VERSION ""

NS_ :

BS_:

BU_: Turbocharger OnBoardDataLogger OffBoardDiagnosticTool2 OffBoardDiagnosticTool1 FileServer ParkingBrakeController SeatControl2 FanDriveController SteeringColumnUnit CommunicationUnitRadio CommunicationUnitSatellite CommunicationUnitCellular PropulsionBatteryCharger ChassisController2 ChassisController1 EngineValveControl AuxiliaryHeater2 AuxiliaryHeater1 ClutchUnit RampControl InformationSystem1 SuspensionSystemController2 OilSensor VehicleDynamicStability ExhaustEmissionController TransmissionDisplay2 TransmissionDisplay1 ClimateControl2 WaterPumpController RearAxleSteeringController LightingOperatorControl SeatController1 IgnitionController2 IgnitionController1 TirePressureController CabController2 CabController1 PneumaticSystemController SuspensionSystemController1 HydraulicPumpController EnduranceBrakingSystem RetarderExhaustEngine2 OnBoardDiagnosticUnit HeadwayController RetarderExhaustEngine1 CabDisplay1 ManagementComputer VirtualTerminal OffVehicleGateway PowerTakeOffFront HitchControl AuxiliaryValveControl BodyController TractorTrailerBridge1 StarterSystem ElectricalSystem VehicleSecurity VehicleNavigation AerodynamicControl ElectricalChargingSystem ClimateControl1 TripRecorder InstrumentCluster SuspensionDriveAxle2 SuspensionDriveAxle1 SuspensionSteerAxle SteeringController FuelSystem CruiseControl RetarderDriveline RetarderEngine BrakesDriveAxle2 BrakesDriveAxle1 BrakesSystemController BrakesSteerAxle AxleDrive2 AxleDrive1 AxleSteering PowerTakeOff ShiftConsoleSecondary ShiftConsolePrimary Transmission2 Transmission1 Engine2 Engine1

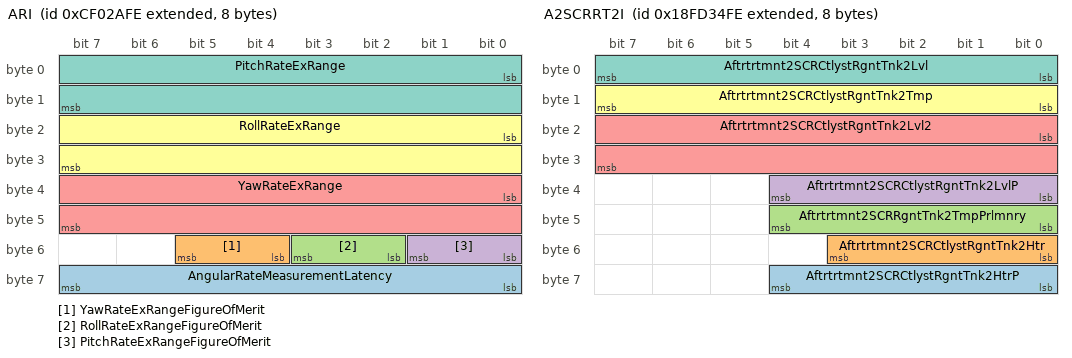
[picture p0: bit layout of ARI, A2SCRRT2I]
BO_ 2364549886 ARI: 8 Vector__XXX
 SG_ AngularRateMeasurementLatency : 56|8@1+ (0.5,0) [0|125] "ms" Vector__XXX
 SG_ YawRateExRangeFigureOfMerit : 52|2@1+ (1,0) [0|3] "" Vector__XXX
 SG_ RollRateExRangeFigureOfMerit : 50|2@1+ (1,0) [0|3] "" Vector__XXX
 SG_ PitchRateExRangeFigureOfMerit : 48|2@1+ (1,0) [0|3] "" Vector__XXX
 SG_ YawRateExRange : 32|16@1+ (0.0078125,-250) [-250|250.992] "deg/sec" Vector__XXX
 SG_ RollRateExRange : 16|16@1+ (0.0078125,-250) [-250|250.992] "deg/sec" Vector__XXX
 SG_ PitchRateExRange : 0|16@1+ (0.0078125,-250) [-250|250.992] "deg/sec" Vector__XXX

BO_ 2566712318 AFT2NAI: 8 Vector__XXX
 SG_ Aftrtrtmnt2NOxAdsrbrDSOxRgnrtnSt : 2|2@1+ (1,0) [0|3] "" Vector__XXX
 SG_ Aftrtrtmnt2NOxAdsrbrDNOxRgnrtnSt : 0|2@1+ (1,0) [0|3] "" Vector__XXX

BO_ 2566712574 AFT1NAI: 8 Vector__XXX
 SG_ Aftrtrtmnt1NOxAdsrbrDSOxRgnrtnSt : 2|2@1+ (1,0) [0|3] "" Vector__XXX
 SG_ Aftrtrtmnt1NOxAdsrbrDNOxRgnrtnSt : 0|2@1+ (1,0) [0|3] "" Vector__XXX

BO_ 2164078590 A2SCRSI: 8 Vector__XXX
 SG_ Aftrtrtmnt2SCRCtlystCnvrsnEffcnc : 32|8@1+ (0.4,0) [0|100] "%" Vector__XXX
 SG_ Aftrtrtmnt2SCRCmddCtlystRgntCnsm : 16|16@1+ (0.05,0) [0|3212.75] "L/h" Vector__XXX
 SG_ Aftrtrtmnt2SCRAvrgCtlystRgntCnsm : 0|16@1+ (0.05,0) [0|3212.75] "L/h" Vector__XXX

BO_ 2566731006 A2SCRRT2I: 8 Vector__XXX
 SG_ Aftrtrtmnt2SCRCtlystRgntTnk2HtrP : 56|5@1+ (1,0) [0|31] "" Vector__XXX
 SG_ Aftrtrtmnt2SCRCtlystRgntTnk2Htr : 48|4@1+ (1,0) [0|15] "" Vector__XXX
 SG_ Aftrtrtmnt2SCRRgntTnk2TmpPrlmnry : 40|5@1+ (1,0) [0|31] "" Vector__XXX
 SG_ Aftrtrtmnt2SCRCtlystRgntTnk2LvlP : 32|5@1+ (1,0) [0|31] "" Vector__XXX
 SG_ Aftrtrtmnt2SCRCtlystRgntTnk2Lvl2 : 16|16@1+ (0.1,0) [0|6425.5] "mm" Vector__XXX
 SG_ Aftrtrtmnt2SCRCtlystRgntTnk2Tmp : 8|8@1+ (1,-40) [-40|210] "degC" Vector__XXX
 SG_ Aftrtrtmnt2SCRCtlystRgntTnk2Lvl : 0|8@1+ (0.4,0) [0|100] "%" Vector__XXX

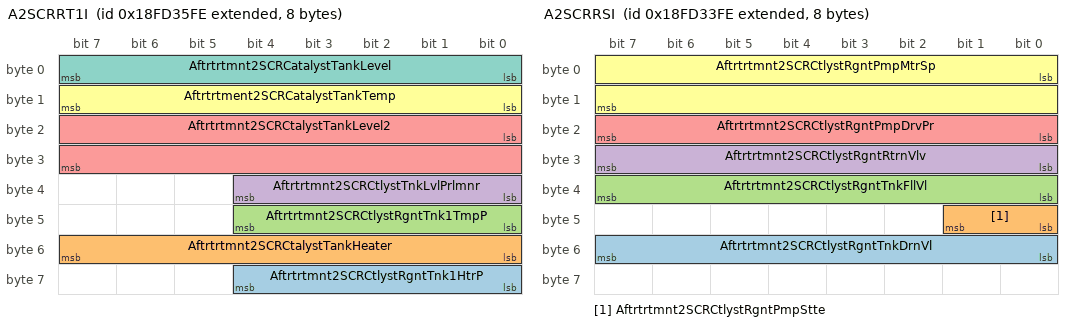
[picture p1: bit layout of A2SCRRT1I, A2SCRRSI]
BO_ 2566731262 A2SCRRT1I: 8 Vector__XXX
 SG_ Aftrtrtmnt2SCRCtlystRgntTnk1HtrP : 56|5@1+ (1,0) [0|31] "" Vector__XXX
 SG_ Aftrtrtmnt2SCRCtalystTankHeater : 48|8@1+ (0.4,0) [0|100] "%" Vector__XXX
 SG_ Aftrtrtmnt2SCRCtlystRgntTnk1TmpP : 40|5@1+ (1,0) [0|31] "" Vector__XXX
 SG_ Aftrtrtmnt2SCRCtlystTnkLvlPrlmnr : 32|5@1+ (1,0) [0|31] "" Vector__XXX
 SG_ Aftrtrtmnt2SCRCtalystTankLevel2 : 16|16@1+ (0.1,0) [0|6425.5] "mm" Vector__XXX
 SG_ Aftrtrtment2SCRCatalystTankTemp : 8|8@1+ (1,-40) [-40|210] "degC" Vector__XXX
 SG_ Aftrtrtmnt2SCRCatalystTankLevel : 0|8@1+ (0.4,0) [0|100] "%" Vector__XXX

BO_ 2566730750 A2SCRRSI: 8 Vector__XXX
 SG_ Aftrtrtmnt2SCRCtlystRgntTnkDrnVl : 48|8@1+ (0.4,0) [0|100] "%" Vector__XXX
 SG_ Aftrtrtmnt2SCRCtlystRgntPmpStte : 40|2@1+ (1,0) [0|3] "" Vector__XXX
 SG_ Aftrtrtmnt2SCRCtlystRgntTnkFllVl : 32|8@1+ (0.4,0) [0|100] "%" Vector__XXX
 SG_ Aftrtrtmnt2SCRCtlystRgntRtrnVlv : 24|8@1+ (0.4,0) [0|100] "%" Vector__XXX
 SG_ Aftrtrtmnt2SCRCtlystRgntPmpDrvPr : 16|8@1+ (0.4,0) [0|100] "%" Vector__XXX
 SG_ Aftrtrtmnt2SCRCtlystRgntPmpMtrSp : 0|16@1+ (0.5,0) [0|32127.5] "rpm" Vector__XXX

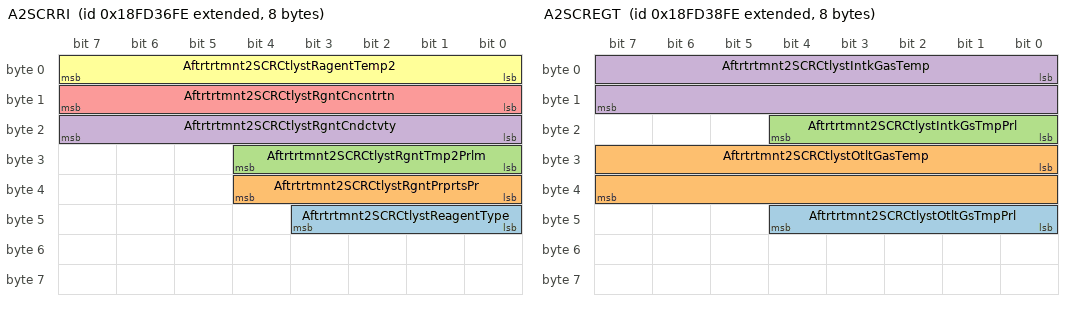
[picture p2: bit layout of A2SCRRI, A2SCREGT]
BO_ 2566731518 A2SCRRI: 8 Vector__XXX
 SG_ Aftrtrtmnt2SCRCtlystReagentType : 40|4@1+ (1,0) [0|15] "" Vector__XXX
 SG_ Aftrtrtmnt2SCRCtlystRgntPrprtsPr : 32|5@1+ (1,0) [0|31] "" Vector__XXX
 SG_ Aftrtrtmnt2SCRCtlystRgntTmp2Prlm : 24|5@1+ (1,0) [0|31] "" Vector__XXX
 SG_ Aftrtrtmnt2SCRCtlystRgntCndctvty : 16|8@1+ (5,0) [0|1250] "microSiemens/mm" Vector__XXX
 SG_ Aftrtrtmnt2SCRCtlystRgntCncntrtn : 8|8@1+ (0.25,0) [0|62.5] "%" Vector__XXX
 SG_ Aftrtrtmnt2SCRCtlystRagentTemp2 : 0|8@1+ (1,-40) [-40|210] "degC" Vector__XXX

BO_ 2566732030 A2SCREGT: 8 Vector__XXX
 SG_ Aftrtrtmnt2SCRCtlystOtltGsTmpPrl : 40|5@1+ (1,0) [0|31] "" Vector__XXX
 SG_ Aftrtrtmnt2SCRCtlystOtltGasTemp : 24|16@1+ (0.03125,-273) [-273|1734.96875] "degC" Vector__XXX
 SG_ Aftrtrtmnt2SCRCtlystIntkGsTmpPrl : 16|5@1+ (1,0) [0|31] "" Vector__XXX
 SG_ Aftrtrtmnt2SCRCtlystIntkGasTemp : 0|16@1+ (0.03125,-273) [-273|1734.96875] "degC" Vector__XXX

BO_ 2566732286 A2SCREGP: 8 Vector__XXX
 SG_ Aftrtrtmnt2SCRCtlystExhstGsDffPr : 16|5@1+ (1,0) [0|31] "" Vector__XXX
 SG_ Aftrtrtmnt2SCRCtlystExhstGs_0000 : 0|16@1+ (0.1,0) [0|6425.5] "kPa" Vector__XXX

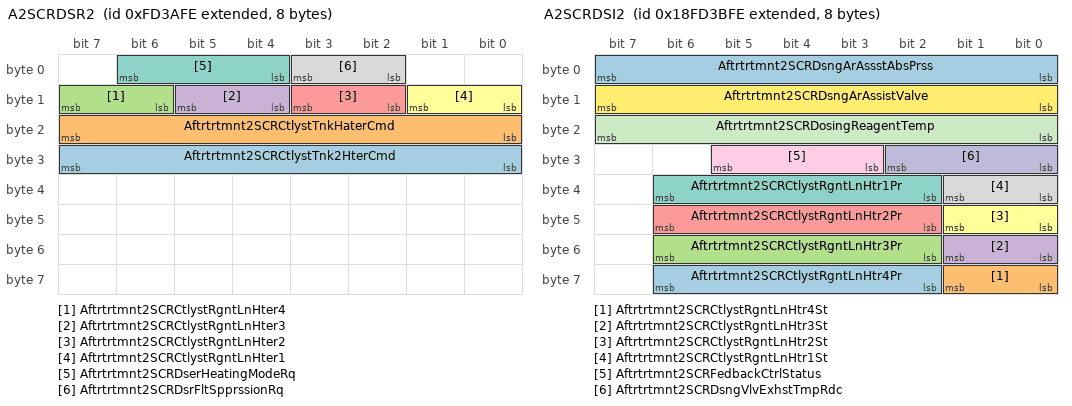
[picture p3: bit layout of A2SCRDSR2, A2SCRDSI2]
BO_ 2164079358 A2SCRDSR2: 8 Vector__XXX
 SG_ Aftrtrtmnt2SCRCtlystTnk2HterCmd : 24|8@1+ (0.4,0) [0|100] "%" Vector__XXX
 SG_ Aftrtrtmnt2SCRCtlystTnkHaterCmd : 16|8@1+ (0.4,0) [0|100] "%" Vector__XXX
 SG_ Aftrtrtmnt2SCRCtlystRgntLnHter4 : 14|2@1+ (1,0) [0|3] "" Vector__XXX
 SG_ Aftrtrtmnt2SCRCtlystRgntLnHter3 : 12|2@1+ (1,0) [0|3] "" Vector__XXX
 SG_ Aftrtrtmnt2SCRCtlystRgntLnHter2 : 10|2@1+ (1,0) [0|3] "" Vector__XXX
 SG_ Aftrtrtmnt2SCRCtlystRgntLnHter1 : 8|2@1+ (1,0) [0|3] "" Vector__XXX
 SG_ Aftrtrtmnt2SCRDserHeatingModeRq : 4|3@1+ (1,0) [0|7] "" Vector__XXX
 SG_ Aftrtrtmnt2SCRDsrFltSpprssionRq : 2|2@1+ (1,0) [0|3] "" Vector__XXX

BO_ 2364549118 A2SCRDSR1: 8 Vector__XXX
 SG_ Aftrtrtmnt2SCRRqdRgntQnttyFrIntg : 24|16@1+ (0.1,0) [0|6425.5] "g" Vector__XXX
 SG_ Aftrtratment2SCRSystemRqedState : 16|4@1+ (1,0) [0|15] "" Vector__XXX
 SG_ Aftrtrtmnt2SCRRqdDsngRgntQntity : 0|16@1+ (0.3,0) [0|19276.5] "g/h" Vector__XXX

BO_ 2566732798 A2SCRDSI2: 8 Vector__XXX
 SG_ Aftrtrtmnt2SCRCtlystRgntLnHtr4Pr : 58|5@1+ (1,0) [0|31] "" Vector__XXX
 SG_ Aftrtrtmnt2SCRCtlystRgntLnHtr4St : 56|2@1+ (1,0) [0|3] "" Vector__XXX
 SG_ Aftrtrtmnt2SCRCtlystRgntLnHtr3Pr : 50|5@1+ (1,0) [0|31] "" Vector__XXX
 SG_ Aftrtrtmnt2SCRCtlystRgntLnHtr3St : 48|2@1+ (1,0) [0|3] "" Vector__XXX
 SG_ Aftrtrtmnt2SCRCtlystRgntLnHtr2Pr : 42|5@1+ (1,0) [0|31] "" Vector__XXX
 SG_ Aftrtrtmnt2SCRCtlystRgntLnHtr2St : 40|2@1+ (1,0) [0|3] "" Vector__XXX
 SG_ Aftrtrtmnt2SCRCtlystRgntLnHtr1Pr : 34|5@1+ (1,0) [0|31] "" Vector__XXX
 SG_ Aftrtrtmnt2SCRCtlystRgntLnHtr1St : 32|2@1+ (1,0) [0|3] "" Vector__XXX
 SG_ Aftrtrtmnt2SCRFedbackCtrlStatus : 27|3@1+ (1,0) [0|7] "" Vector__XXX
 SG_ Aftrtrtmnt2SCRDsngVlvExhstTmpRdc : 24|3@1+ (1,0) [0|7] "" Vector__XXX
 SG_ Aftrtrtmnt2SCRDosingReagentTemp : 16|8@1+ (1,-40) [-40|210] "degC" Vector__XXX
 SG_ Aftrtrtmnt2SCRDsngArAssistValve : 8|8@1+ (0.4,0) [0|100] "%" Vector__XXX
 SG_ Aftrtrtmnt2SCRDsngArAssstAbsPrss : 0|8@1+ (8,0) [0|2000] "kPa" Vector__XXX

BO_ 2364548862 A2SCRDSI1: 8 Vector__XXX
 SG_ Aftrtrtmnt2SCRDsngRgentAbsPress : 40|8@1+ (8,0) [0|2000] "kPa" Vector__XXX
 SG_ Aftrtrtmnt2SCRActlRgntQnttyOfInt : 24|16@1+ (0.1,0) [0|6425.5] "g" Vector__XXX
 SG_ Aftertreatment2SCRSystemState : 16|4@1+ (1,0) [0|15] "" Vector__XXX
 SG_ Aftrtrtmnt2SCRActlDsngRgntQntty : 0|16@1+ (0.3,0) [0|19276.5] "g/h" Vector__XXX

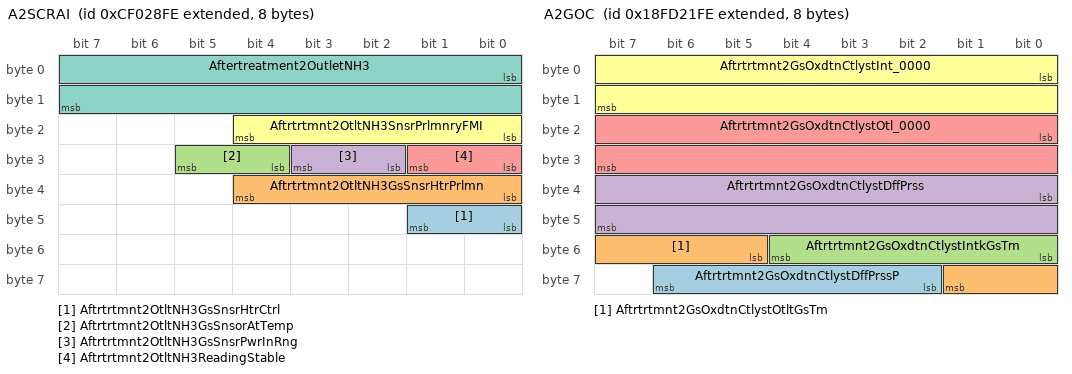
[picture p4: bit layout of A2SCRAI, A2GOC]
BO_ 2364549374 A2SCRAI: 8 Vector__XXX
 SG_ Aftrtrtmnt2OtltNH3GsSnsrHtrCtrl : 40|2@1+ (1,0) [0|3] "" Vector__XXX
 SG_ Aftrtrtmnt2OtltNH3GsSnsrHtrPrlmn : 32|5@1+ (1,0) [0|31] "" Vector__XXX
 SG_ Aftrtrtmnt2OtltNH3GsSnsorAtTemp : 28|2@1+ (1,0) [0|3] "" Vector__XXX
 SG_ Aftrtrtmnt2OtltNH3GsSnsrPwrInRng : 26|2@1+ (1,0) [0|3] "" Vector__XXX
 SG_ Aftrtrtmnt2OtltNH3ReadingStable : 24|2@1+ (1,0) [0|3] "" Vector__XXX
 SG_ Aftrtrtmnt2OtltNH3SnsrPrlmnryFMI : 16|5@1+ (1,0) [0|31] "" Vector__XXX
 SG_ Aftertreatment2OutletNH3 : 0|16@1+ (0.3,0) [0|19276.5] "g/h" Vector__XXX

BO_ 2566726142 A2GOC: 8 Vector__XXX
 SG_ Aftrtrtmnt2GsOxdtnCtlystDffPrssP : 58|5@1+ (1,0) [0|31] "" Vector__XXX
 SG_ Aftrtrtmnt2GsOxdtnCtlystOtltGsTm : 53|5@1+ (1,0) [0|31] "" Vector__XXX
 SG_ Aftrtrtmnt2GsOxdtnCtlystIntkGsTm : 48|5@1+ (1,0) [0|31] "" Vector__XXX
 SG_ Aftrtrtmnt2GsOxdtnCtlystDffPrss : 32|16@1+ (0.1,0) [0|6425.5] "kPa" Vector__XXX
 SG_ Aftrtrtmnt2GsOxdtnCtlystOtl_0000 : 16|16@1+ (0.03125,-273) [-273|1734.96875] "degC" Vector__XXX
 SG_ Aftrtrtmnt2GsOxdtnCtlystInt_0000 : 0|16@1+ (0.03125,-273) [-273|1734.96875] "degC" Vector__XXX

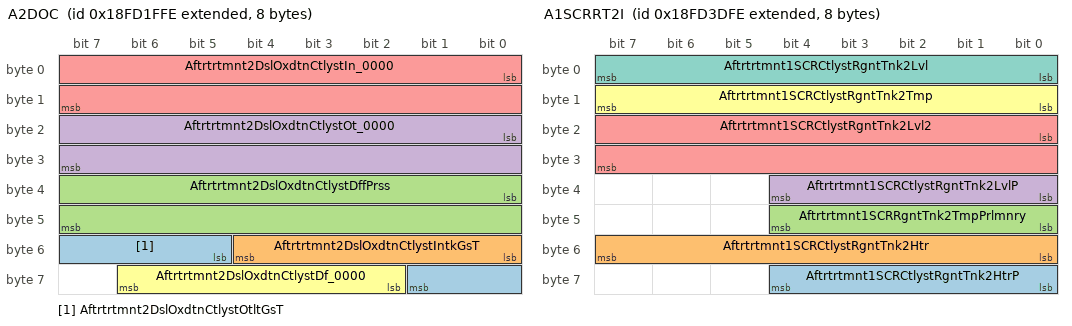
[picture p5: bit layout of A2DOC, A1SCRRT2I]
BO_ 2566725630 A2DOC: 8 Vector__XXX
 SG_ Aftrtrtmnt2DslOxdtnCtlystOtltGsT : 53|5@1+ (1,0) [0|31] "" Vector__XXX
 SG_ Aftrtrtmnt2DslOxdtnCtlystIntkGsT : 48|5@1+ (1,0) [0|31] "" Vector__XXX
 SG_ Aftrtrtmnt2DslOxdtnCtlystDffPrss : 32|16@1+ (0.5,0) [0|32127.5] "kPa" Vector__XXX
 SG_ Aftrtrtmnt2DslOxdtnCtlystOt_0000 : 16|16@1+ (0.03125,-273) [-273|1734.96875] "degC" Vector__XXX
 SG_ Aftrtrtmnt2DslOxdtnCtlystIn_0000 : 0|16@1+ (0.03125,-273) [-273|1734.96875] "degC" Vector__XXX
 SG_ Aftrtrtmnt2DslOxdtnCtlystDf_0000 : 58|5@1+ (1,0) [0|31] "" Vector__XXX

BO_ 2566733310 A1SCRRT2I: 8 Vector__XXX
 SG_ Aftrtrtmnt1SCRCtlystRgntTnk2HtrP : 56|5@1+ (1,0) [0|31] "" Vector__XXX
 SG_ Aftrtrtmnt1SCRCtlystRgntTnk2Htr : 48|8@1+ (0.4,0) [0|100] "%" Vector__XXX
 SG_ Aftrtrtmnt1SCRRgntTnk2TmpPrlmnry : 40|5@1+ (1,0) [0|31] "" Vector__XXX
 SG_ Aftrtrtmnt1SCRCtlystRgntTnk2LvlP : 32|5@1+ (1,0) [0|31] "" Vector__XXX
 SG_ Aftrtrtmnt1SCRCtlystRgntTnk2Lvl2 : 16|16@1+ (0.1,0) [0|6425.5] "mm" Vector__XXX
 SG_ Aftrtrtmnt1SCRCtlystRgntTnk2Tmp : 8|8@1+ (1,-40) [-40|210] "degC" Vector__XXX
 SG_ Aftrtrtmnt1SCRCtlystRgntTnk2Lvl : 0|8@1+ (0.4,0) [0|100] "%" Vector__XXX

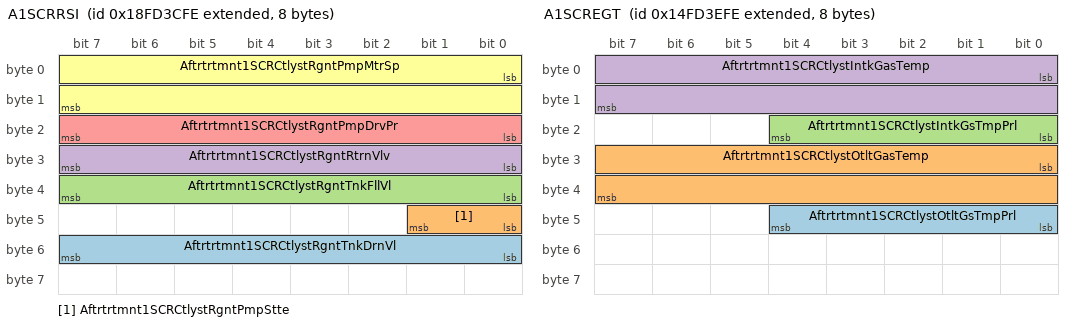
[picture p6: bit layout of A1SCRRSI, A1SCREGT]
BO_ 2566733054 A1SCRRSI: 8 Vector__XXX
 SG_ Aftrtrtmnt1SCRCtlystRgntTnkDrnVl : 48|8@1+ (0.4,0) [0|100] "%" Vector__XXX
 SG_ Aftrtrtmnt1SCRCtlystRgntPmpStte : 40|2@1+ (1,0) [0|3] "" Vector__XXX
 SG_ Aftrtrtmnt1SCRCtlystRgntTnkFllVl : 32|8@1+ (0.4,0) [0|100] "%" Vector__XXX
 SG_ Aftrtrtmnt1SCRCtlystRgntRtrnVlv : 24|8@1+ (0.4,0) [0|100] "%" Vector__XXX
 SG_ Aftrtrtmnt1SCRCtlystRgntPmpDrvPr : 16|8@1+ (0.4,0) [0|100] "%" Vector__XXX
 SG_ Aftrtrtmnt1SCRCtlystRgntPmpMtrSp : 0|16@1+ (0.5,0) [0|32127.5] "rpm" Vector__XXX

BO_ 2499624702 A1SCREGT: 8 Vector__XXX
 SG_ Aftrtrtmnt1SCRCtlystOtltGsTmpPrl : 40|5@1+ (1,0) [0|31] "" Vector__XXX
 SG_ Aftrtrtmnt1SCRCtlystOtltGasTemp : 24|16@1+ (0.03125,-273) [-273|1734.96875] "degC" Vector__XXX
 SG_ Aftrtrtmnt1SCRCtlystIntkGsTmpPrl : 16|5@1+ (1,0) [0|31] "" Vector__XXX
 SG_ Aftrtrtmnt1SCRCtlystIntkGasTemp : 0|16@1+ (0.03125,-273) [-273|1734.96875] "degC" Vector__XXX

BO_ 2566733822 A1SCREGP: 8 Vector__XXX
 SG_ Aftrtrtmnt1SCRCtlystExhstGsDffPr : 16|5@1+ (1,0) [0|31] "" Vector__XXX
 SG_ Aftrtrtmnt1SCRCtlystExhstGs_0000 : 0|16@1+ (0.1,0) [0|6425.5] "kPa" Vector__XXX

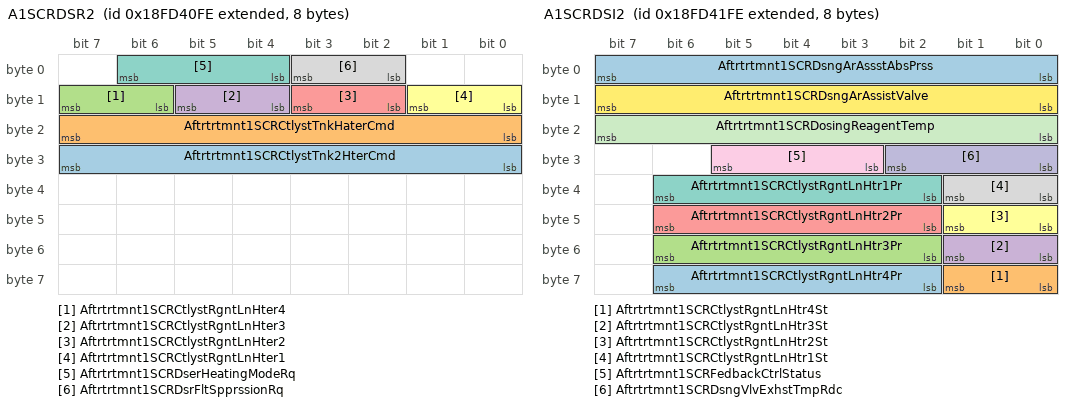
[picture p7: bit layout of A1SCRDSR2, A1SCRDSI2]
BO_ 2566734078 A1SCRDSR2: 8 Vector__XXX
 SG_ Aftrtrtmnt1SCRCtlystTnk2HterCmd : 24|8@1+ (0.4,0) [0|100] "%" Vector__XXX
 SG_ Aftrtrtmnt1SCRCtlystTnkHaterCmd : 16|8@1+ (0.4,0) [0|100] "%" Vector__XXX
 SG_ Aftrtrtmnt1SCRCtlystRgntLnHter4 : 14|2@1+ (1,0) [0|3] "" Vector__XXX
 SG_ Aftrtrtmnt1SCRCtlystRgntLnHter3 : 12|2@1+ (1,0) [0|3] "" Vector__XXX
 SG_ Aftrtrtmnt1SCRCtlystRgntLnHter2 : 10|2@1+ (1,0) [0|3] "" Vector__XXX
 SG_ Aftrtrtmnt1SCRCtlystRgntLnHter1 : 8|2@1+ (1,0) [0|3] "" Vector__XXX
 SG_ Aftrtrtmnt1SCRDserHeatingModeRq : 4|3@1+ (1,0) [0|7] "" Vector__XXX
 SG_ Aftrtrtmnt1SCRDsrFltSpprssionRq : 2|2@1+ (1,0) [0|3] "" Vector__XXX

BO_ 2364548350 A1SCRDSR1: 8 Vector__XXX
 SG_ Aftrtrtmnt1SCRRqdRgntQnttyFrIntg : 24|16@1+ (0.1,0) [0|6425.5] "g" Vector__XXX
 SG_ Aftrtratment1SCRSystemRqedState : 16|4@1+ (1,0) [0|15] "" Vector__XXX
 SG_ Aftrtrtmnt1SCRRqdDsngRgntQntity : 0|16@1+ (0.3,0) [0|19276.5] "g/h" Vector__XXX

BO_ 2566734334 A1SCRDSI2: 8 Vector__XXX
 SG_ Aftrtrtmnt1SCRCtlystRgntLnHtr4Pr : 58|5@1+ (1,0) [0|31] "" Vector__XXX
 SG_ Aftrtrtmnt1SCRCtlystRgntLnHtr4St : 56|2@1+ (1,0) [0|3] "" Vector__XXX
 SG_ Aftrtrtmnt1SCRCtlystRgntLnHtr3Pr : 50|5@1+ (1,0) [0|31] "" Vector__XXX
 SG_ Aftrtrtmnt1SCRCtlystRgntLnHtr3St : 48|2@1+ (1,0) [0|3] "" Vector__XXX
 SG_ Aftrtrtmnt1SCRCtlystRgntLnHtr2Pr : 42|5@1+ (1,0) [0|31] "" Vector__XXX
 SG_ Aftrtrtmnt1SCRCtlystRgntLnHtr2St : 40|2@1+ (1,0) [0|3] "" Vector__XXX
 SG_ Aftrtrtmnt1SCRCtlystRgntLnHtr1Pr : 34|5@1+ (1,0) [0|31] "" Vector__XXX
 SG_ Aftrtrtmnt1SCRCtlystRgntLnHtr1St : 32|2@1+ (1,0) [0|3] "" Vector__XXX
 SG_ Aftrtrtmnt1SCRFedbackCtrlStatus : 27|3@1+ (1,0) [0|7] "" Vector__XXX
 SG_ Aftrtrtmnt1SCRDsngVlvExhstTmpRdc : 24|3@1+ (1,0) [0|7] "" Vector__XXX
 SG_ Aftrtrtmnt1SCRDosingReagentTemp : 16|8@1+ (1,-40) [-40|210] "degC" Vector__XXX
 SG_ Aftrtrtmnt1SCRDsngArAssistValve : 8|8@1+ (0.4,0) [0|100] "%" Vector__XXX
 SG_ Aftrtrtmnt1SCRDsngArAssstAbsPrss : 0|8@1+ (8,0) [0|2000] "kPa" Vector__XXX

BO_ 2364548094 A1SCRDSI1: 8 Vector__XXX
 SG_ Aftrtrtmnt1SCRDsngRgentAbsPress : 40|8@1+ (8,0) [0|2000] "kPa" Vector__XXX
 SG_ Aftrtrtmnt1SCRActlRgntQnttyOfInt : 24|16@1+ (0.1,0) [0|6425.5] "g" Vector__XXX
 SG_ Aftertreatment1SCRSystemState : 16|4@1+ (1,0) [0|15] "" Vector__XXX
 SG_ Aftrtrtmnt1SCRActlDsngRgntQntty : 0|16@1+ (0.3,0) [0|19276.5] "g/h" Vector__XXX

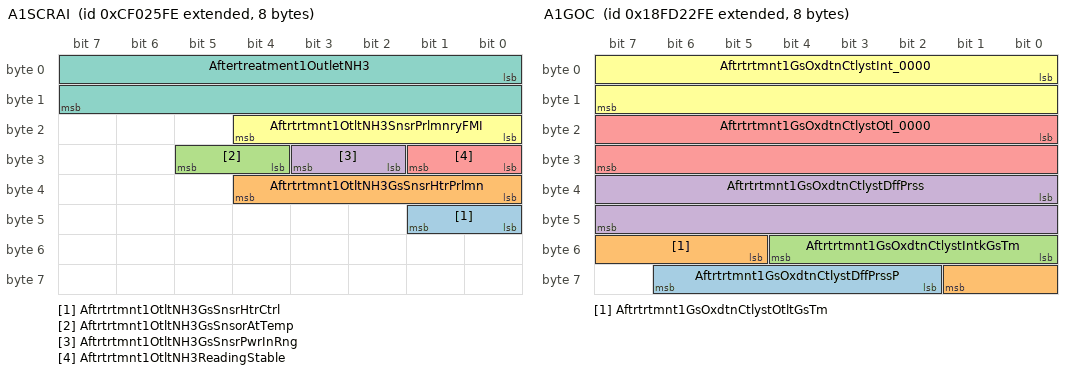
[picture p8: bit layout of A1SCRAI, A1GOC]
BO_ 2364548606 A1SCRAI: 8 Vector__XXX
 SG_ Aftrtrtmnt1OtltNH3GsSnsrHtrCtrl : 40|2@1+ (1,0) [0|3] "" Vector__XXX
 SG_ Aftrtrtmnt1OtltNH3GsSnsrHtrPrlmn : 32|5@1+ (1,0) [0|31] "" Vector__XXX
 SG_ Aftrtrtmnt1OtltNH3GsSnsorAtTemp : 28|2@1+ (1,0) [0|3] "" Vector__XXX
 SG_ Aftrtrtmnt1OtltNH3GsSnsrPwrInRng : 26|2@1+ (1,0) [0|3] "" Vector__XXX
 SG_ Aftrtrtmnt1OtltNH3ReadingStable : 24|2@1+ (1,0) [0|3] "" Vector__XXX
 SG_ Aftrtrtmnt1OtltNH3SnsrPrlmnryFMI : 16|5@1+ (1,0) [0|31] "" Vector__XXX
 SG_ Aftertreatment1OutletNH3 : 0|16@1+ (0.3,0) [0|19276.5] "g/h" Vector__XXX

BO_ 2566726398 A1GOC: 8 Vector__XXX
 SG_ Aftrtrtmnt1GsOxdtnCtlystDffPrssP : 58|5@1+ (1,0) [0|31] "" Vector__XXX
 SG_ Aftrtrtmnt1GsOxdtnCtlystOtltGsTm : 53|5@1+ (1,0) [0|31] "" Vector__XXX
 SG_ Aftrtrtmnt1GsOxdtnCtlystIntkGsTm : 48|5@1+ (1,0) [0|31] "" Vector__XXX
 SG_ Aftrtrtmnt1GsOxdtnCtlystDffPrss : 32|16@1+ (0.1,0) [0|6425.5] "kPa" Vector__XXX
 SG_ Aftrtrtmnt1GsOxdtnCtlystOtl_0000 : 16|16@1+ (0.03125,-273) [-273|1734.96875] "degC" Vector__XXX
 SG_ Aftrtrtmnt1GsOxdtnCtlystInt_0000 : 0|16@1+ (0.03125,-273) [-273|1734.96875] "degC" Vector__XXX

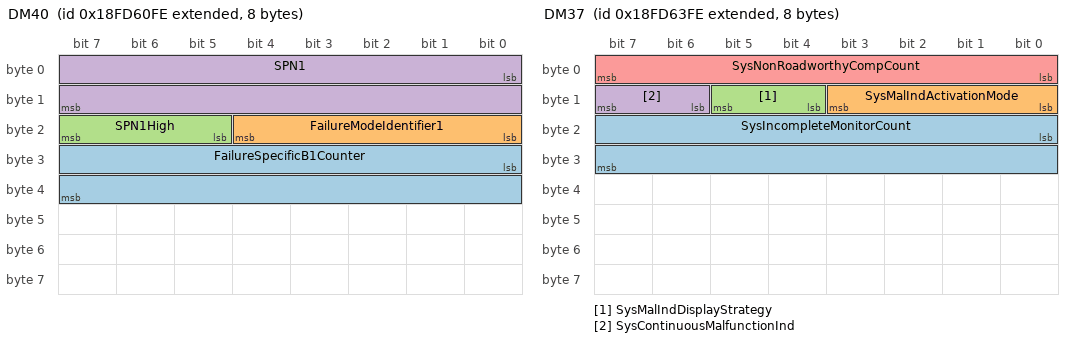
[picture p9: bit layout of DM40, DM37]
BO_ 2566742270 DM40: 8 Vector__XXX
 SG_ FailureSpecificB1Counter : 24|16@1+ (0.1,0) [0|6425.5] "hr" Vector__XXX
 SG_ FailureModeIdentifier1 : 16|5@1+ (1,0) [0|0] "" Vector__XXX
 SG_ SPN1High : 21|3@1+ (1,0) [0|7] "" Vector__XXX
 SG_ SPN1 : 0|16@1+ (1,0) [0|65536] "" Vector__XXX

BO_ 2566742526 DM39: 8 Vector__XXX
 SG_ SysGreatestB1Counter : 32|16@1+ (0.1,0) [0|6425.5] "hr" Vector__XXX
 SG_ SysCumulativeContinuousMITime : 0|32@1+ (0.05,0) [0|210554060.75] "hr" Vector__XXX

BO_ 2566742782 DM38: 8 Vector__XXX
 SG_ RegulationDescription : 0|8@1+ (1,0) [0|255] "" Vector__XXX

BO_ 2566743038 DM37: 8 Vector__XXX
 SG_ SysIncompleteMonitorCount : 16|16@1+ (1,0) [0|64512] "" Vector__XXX
 SG_ SysMalIndActivationMode : 8|4@1+ (1,0) [0|15] "" Vector__XXX
 SG_ SysMalIndDisplayStrategy : 12|2@1+ (1,0) [0|3] "" Vector__XXX
 SG_ SysContinuousMalfunctionInd : 14|2@1+ (1,0) [0|3] "" Vector__XXX
 SG_ SysNonRoadworthyCompCount : 0|8@1+ (1,0) [0|250] "" Vector__XXX

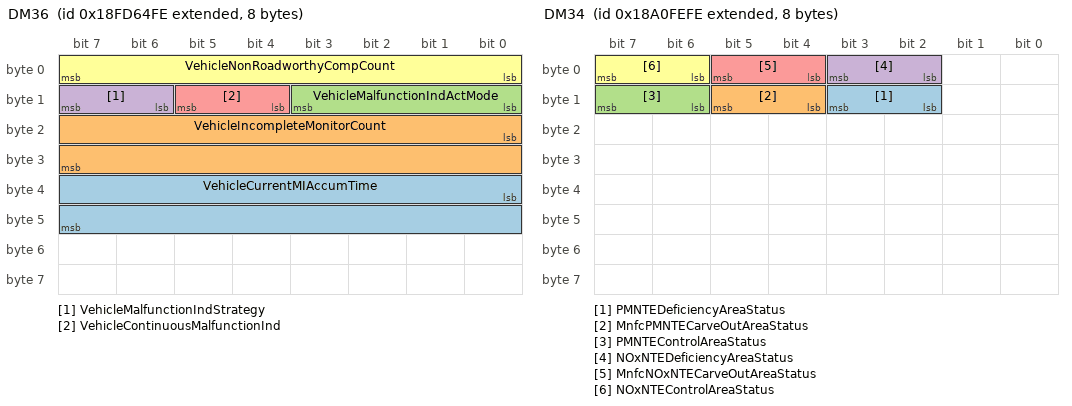
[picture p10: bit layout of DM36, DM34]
BO_ 2566743294 DM36: 8 Vector__XXX
 SG_ VehicleCurrentMIAccumTime : 32|16@1+ (1,0) [0|64255] "min" Vector__XXX
 SG_ VehicleIncompleteMonitorCount : 16|16@1+ (1,0) [0|64255] "" Vector__XXX
 SG_ VehicleMalfunctionIndActMode : 8|4@1+ (1,0) [0|15] "" Vector__XXX
 SG_ VehicleMalfunctionIndStrategy : 14|2@1+ (1,0) [0|3] "" Vector__XXX
 SG_ VehicleContinuousMalfunctionInd : 12|2@1+ (1,0) [0|3] "" Vector__XXX
 SG_ VehicleNonRoadworthyCompCount : 0|8@1+ (1,0) [0|250] "" Vector__XXX

BO_ 2560687870 DM34: 8 Vector__XXX
 SG_ PMNTEDeficiencyAreaStatus : 10|2@1+ (1,0) [0|3] "" Vector__XXX
 SG_ MnfcPMNTECarveOutAreaStatus : 12|2@1+ (1,0) [0|3] "" Vector__XXX
 SG_ PMNTEControlAreaStatus : 14|2@1+ (1,0) [0|3] "" Vector__XXX
 SG_ NOxNTEDeficiencyAreaStatus : 2|2@1+ (1,0) [0|3] "" Vector__XXX
 SG_ MnfcNOxNTECarveOutAreaStatus : 4|2@1+ (1,0) [0|3] "" Vector__XXX
 SG_ NOxNTEControlAreaStatus : 6|2@1+ (1,0) [0|3] "" Vector__XXX

BO_ 2292317950 DM33: 9 Vector__XXX
 SG_ AECDEngineHours1Timer2 : 40|32@1+ (1,0) [0|4294967295] "min" Vector__XXX
 SG_ AECDEngineHours1Timer1 : 8|32@1+ (1,0) [0|4294967295] "min" Vector__XXX
 SG_ AECDNumber1 : 0|8@1+ (1,0) [0|250] "" Vector__XXX

BO_ 2566809342 BM: 8 Vector__XXX
 SG_ BatteryMainSwitchHoldState : 0|2@1+ (1,0) [0|3] "" Vector__XXX

BO_ 2365446910 BJM3: 8 Vector__XXX
 SG_ Joystick3XAxisDetentPosStatus : 38|2@1+ (1,0) [0|3] "" Vector__XXX
 SG_ Joystick3Button9PressedStatus : 62|2@1+ (1,0) [0|3] "" Vector__XXX
 SG_ Joystick3Button10PressedStatus : 60|2@1+ (1,0) [0|3] "" Vector__XXX
 SG_ Joystick3Button11PressedStatus : 58|2@1+ (1,0) [0|3] "" Vector__XXX
 SG_ Joystick3Button12PressedStatus : 56|2@1+ (1,0) [0|3] "" Vector__XXX
 SG_ Joystick3YAxisDetentPosStatus : 36|2@1+ (1,0) [0|3] "" Vector__XXX
 SG_ Joystick3YAxisPos : 22|10@1+ (0.1,0) [0|102] "%" Vector__XXX
 SG_ Jystck3YAxsLvrFrwrdPstvPsStatus : 20|2@1+ (1,0) [0|3] "" Vector__XXX
 SG_ Jystck3YAxsLvrBckNgtvePosStatus : 18|2@1+ (1,0) [0|3] "" Vector__XXX
 SG_ Joystick3YAxisNeutralPosStatus : 16|2@1+ (1,0) [0|3] "" Vector__XXX
 SG_ Joystick3XAxisPos : 6|10@1+ (0.1,0) [0|102] "%" Vector__XXX
 SG_ Jystck3XAxsLvrRghtPstvPosStatus : 4|2@1+ (1,0) [0|3] "" Vector__XXX
 SG_ Jystck3XAxsLvrLftNgtvePosStatus : 2|2@1+ (1,0) [0|3] "" Vector__XXX
 SG_ Joystick3XAxisNeutralPosStatus : 0|2@1+ (1,0) [0|3] "" Vector__XXX
 SG_ Joystick3Button5PressedStatus : 54|2@1+ (1,0) [0|3] "" Vector__XXX
 SG_ Joystick3Button6PressedStatus : 52|2@1+ (1,0) [0|3] "" Vector__XXX
 SG_ Joystick3Button7PressedStatus : 50|2@1+ (1,0) [0|3] "" Vector__XXX
 SG_ Joystick3Button8PressedStatus : 48|2@1+ (1,0) [0|3] "" Vector__XXX
 SG_ Joystick3Button1PressedStatus : 46|2@1+ (1,0) [0|3] "" Vector__XXX
 SG_ Joystick3Button2PressedStatus : 44|2@1+ (1,0) [0|3] "" Vector__XXX
 SG_ Joystick3Button3PressedStatus : 42|2@1+ (1,0) [0|3] "" Vector__XXX
 SG_ Joystick3Button4PressedStatus : 40|2@1+ (1,0) [0|3] "" Vector__XXX

BO_ 2365446398 BJM2: 8 Vector__XXX
 SG_ Joystick2XAxisDetentPosStatus : 38|2@1+ (1,0) [0|3] "" Vector__XXX
 SG_ Joystick2YAxisDetentPosStatus : 36|2@1+ (1,0) [0|3] "" Vector__XXX
 SG_ Joystick2YAxisPos : 22|10@1+ (0.1,0) [0|102] "%" Vector__XXX
 SG_ Jystck2YAxsLvrFrwrdPstvPsStatus : 20|2@1+ (1,0) [0|3] "" Vector__XXX
 SG_ Jystck2YAxsLvrBckNgtvePosStatus : 18|2@1+ (1,0) [0|3] "" Vector__XXX
 SG_ Joystick2YAxisNeutralPosStatus : 16|2@1+ (1,0) [0|3] "" Vector__XXX
 SG_ Joystick2XAxisPos : 6|10@1+ (0.1,0) [0|102] "%" Vector__XXX
 SG_ Jystck2XAxsLvrRghtPstvPosStatus : 4|2@1+ (1,0) [0|3] "" Vector__XXX
 SG_ Jystck2XAxsLvrLftNgtvePosStatus : 2|2@1+ (1,0) [0|3] "" Vector__XXX
 SG_ Joystick2XAxisNeutralPosStatus : 0|2@1+ (1,0) [0|3] "" Vector__XXX
 SG_ Joystick2Button9PressedStatus : 62|2@1+ (1,0) [0|3] "" Vector__XXX
 SG_ Joystick2Button10PressedStatus : 60|2@1+ (1,0) [0|3] "" Vector__XXX
 SG_ Joystick2Button11PressedStatus : 58|2@1+ (1,0) [0|3] "" Vector__XXX
 SG_ Joystick2Button12PressedStatus : 56|2@1+ (1,0) [0|3] "" Vector__XXX
 SG_ Joystick2Button5PressedStatus : 54|2@1+ (1,0) [0|3] "" Vector__XXX
 SG_ Joystick2Button6PressedStatus : 52|2@1+ (1,0) [0|3] "" Vector__XXX
 SG_ Joystick2Button7PressedStatus : 50|2@1+ (1,0) [0|3] "" Vector__XXX
 SG_ Joystick2Button8PressedStatus : 48|2@1+ (1,0) [0|3] "" Vector__XXX
 SG_ Joystick2Button1PressedStatus : 46|2@1+ (1,0) [0|3] "" Vector__XXX
 SG_ Joystick2Button2PressedStatus : 44|2@1+ (1,0) [0|3] "" Vector__XXX
 SG_ Joystick2Button3PressedStatus : 42|2@1+ (1,0) [0|3] "" Vector__XXX
 SG_ Joystick2Button4PressedStatus : 40|2@1+ (1,0) [0|3] "" Vector__XXX

BO_ 2365445886 BJM1: 8 Vector__XXX
 SG_ Joystick1XAxisDetentPosStatus : 38|2@1+ (1,0) [0|3] "" Vector__XXX
 SG_ Joystick1YAxisDetentPosStatus : 36|2@1+ (1,0) [0|3] "" Vector__XXX
 SG_ Joystick1YAxisPos : 22|10@1+ (0.1,0) [0|102] "%" Vector__XXX
 SG_ Jystck1YAxsLvrFrwrdPstvPsStatus : 20|2@1+ (1,0) [0|3] "" Vector__XXX
 SG_ Jystck1YAxsLvrBckNgtvePosStatus : 18|2@1+ (1,0) [0|3] "" Vector__XXX
 SG_ Joystick1YAxisNeutralPosStatus : 16|2@1+ (1,0) [0|3] "" Vector__XXX
 SG_ Joystick1XAxisPos : 6|10@1+ (0.1,0) [0|102] "%" Vector__XXX
 SG_ Joystick1Button9PressedStatus : 62|2@1+ (1,0) [0|3] "" Vector__XXX
 SG_ Joystick1Button10PressedStatus : 60|2@1+ (1,0) [0|3] "" Vector__XXX
 SG_ Joystick1Button11PressedStatus : 58|2@1+ (1,0) [0|3] "" Vector__XXX
 SG_ Joystick1Button12PressedStatus : 56|2@1+ (1,0) [0|3] "" Vector__XXX
 SG_ Joystick1Button5PressedStatus : 54|2@1+ (1,0) [0|3] "" Vector__XXX
 SG_ Joystick1Button6PressedStatus : 52|2@1+ (1,0) [0|3] "" Vector__XXX
 SG_ Joystick1Button7PressedStatus : 50|2@1+ (1,0) [0|3] "" Vector__XXX
 SG_ Joystick1Button8PressedStatus : 48|2@1+ (1,0) [0|3] "" Vector__XXX
 SG_ Joystick1Button1PressedStatus : 46|2@1+ (1,0) [0|3] "" Vector__XXX
 SG_ Joystick1Button2PressedStatus : 44|2@1+ (1,0) [0|3] "" Vector__XXX
 SG_ Joystick1Button3PressedStatus : 42|2@1+ (1,0) [0|3] "" Vector__XXX
 SG_ Joystick1Button4PressedStatus : 40|2@1+ (1,0) [0|3] "" Vector__XXX
 SG_ Jystck1XAxsLvrRghtPstvPosStatus : 4|2@1+ (1,0) [0|3] "" Vector__XXX
 SG_ Jystck1XAxsLvrLftNgtvePosStatus : 2|2@1+ (1,0) [0|3] "" Vector__XXX
 SG_ Joystick1XAxisNeutralPosStatus : 0|2@1+ (1,0) [0|3] "" Vector__XXX

BO_ 2566847230 B: 8 Vector__XXX
 SG_ ParkingBrakeRedWarningSignal : 26|2@1+ (1,0) [0|3] "" Vector__XXX
 SG_ ParkBrakeReleaseInhibitStatus : 28|2@1+ (1,0) [0|3] "" Vector__XXX
 SG_ ParkingBrakeActuator : 24|2@1+ (1,0) [0|3] "" Vector__XXX
 SG_ BrakeSecondPress : 16|8@1+ (4,0) [0|1000] "kPa" Vector__XXX
 SG_ BrakePrimaryPress : 8|8@1+ (4,0) [0|1000] "kPa" Vector__XXX
 SG_ BrakeAppPress : 0|8@1+ (4,0) [0|1000] "kPa" Vector__XXX

BO_ 2566848254 AWPP: 8 Vector__XXX
 SG_ AuxPumpPress : 0|8@1+ (16,0) [0|4000] "kPa" Vector__XXX

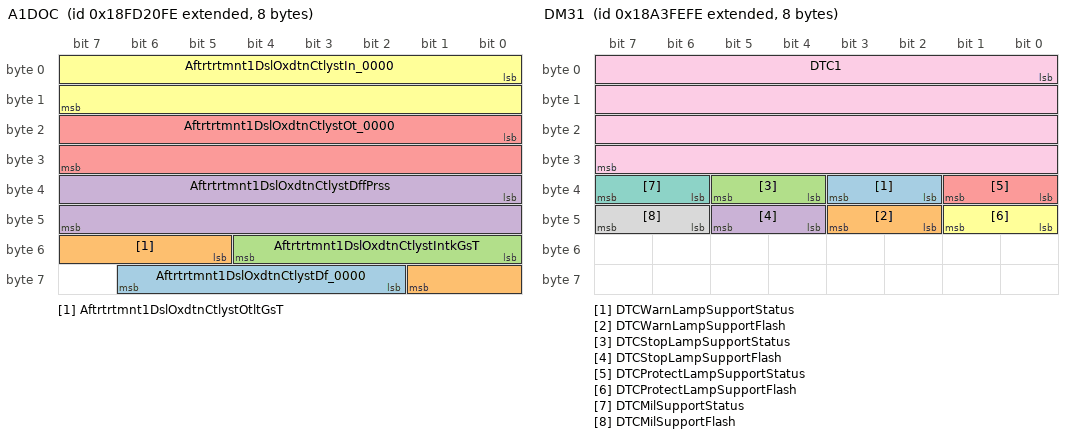
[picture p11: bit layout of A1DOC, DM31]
BO_ 2566725886 A1DOC: 8 Vector__XXX
 SG_ Aftrtrtmnt1DslOxdtnCtlystDf_0000 : 58|5@1+ (1,0) [0|31] "" Vector__XXX
 SG_ Aftrtrtmnt1DslOxdtnCtlystOtltGsT : 53|5@1+ (1,0) [0|31] "" Vector__XXX
 SG_ Aftrtrtmnt1DslOxdtnCtlystIntkGsT : 48|5@1+ (1,0) [0|31] "" Vector__XXX
 SG_ Aftrtrtmnt1DslOxdtnCtlystDffPrss : 32|16@1+ (0.1,0) [0|6425.5] "kPa" Vector__XXX
 SG_ Aftrtrtmnt1DslOxdtnCtlystOt_0000 : 16|16@1+ (0.03125,-273) [-273|1734.96875] "degC" Vector__XXX
 SG_ Aftrtrtmnt1DslOxdtnCtlystIn_0000 : 0|16@1+ (0.03125,-273) [-273|1734.96875] "degC" Vector__XXX

BO_ 2560884478 DM31: 8 Vector__XXX
 SG_ DTCWarnLampSupportStatus : 34|2@1+ (1,0) [0|3] "" Vector__XXX
 SG_ DTCWarnLampSupportFlash : 42|2@1+ (1,0) [0|3] "" Vector__XXX
 SG_ DTCStopLampSupportStatus : 36|2@1+ (1,0) [0|3] "" Vector__XXX
 SG_ DTCStopLampSupportFlash : 44|2@1+ (1,0) [0|3] "" Vector__XXX
 SG_ DTCProtectLampSupportStatus : 32|2@1+ (1,0) [0|3] "" Vector__XXX
 SG_ DTCProtectLampSupportFlash : 40|2@1+ (1,0) [0|3] "" Vector__XXX
 SG_ DTCMilSupportStatus : 38|2@1+ (1,0) [0|3] "" Vector__XXX
 SG_ DTCMilSupportFlash : 46|2@1+ (1,0) [0|3] "" Vector__XXX
 SG_ DTC1 : 0|32@1+ (1,0) [0|4294967295] "" Vector__XXX

BO_ 2633844734 TML: 8 Vector__XXX

BO_ 2560360190 PMI: 8 Vector__XXX
 SG_ DataDictionaryMethod : 11|21@1+ (1,0) [0|2097151] "" Vector__XXX
 SG_ DataDictionaryManufacturerCode : 0|11@1+ (1,0) [0|2047] "" Vector__XXX

BO_ 2566736126 O2FT2: 8 Vector__XXX
 SG_ ShorttermFuelTrimBank2 : 16|16@1+ (0.1,-100) [-100|100] "%" Vector__XXX
 SG_ LongtermFuelTrimBank2 : 0|16@1+ (0.1,-100) [-100|100] "%" Vector__XXX
 SG_ EngExhstGsOxygnSnsrClsdLpOprtnBn : 32|4@1+ (1,0) [0|15] "" Vector__XXX

BO_ 2566736382 O2FT1: 8 Vector__XXX
 SG_ ShorttermFuelTrimBank1 : 16|16@1+ (0.1,-100) [-100|100] "%" Vector__XXX
 SG_ LongtermFuelTrimBank1 : 0|16@1+ (0.1,-100) [-100|100] "%" Vector__XXX
 SG_ EngExhstGsOxygnSnsrClsdLpOp_0000 : 32|4@1+ (1,0) [0|15] "" Vector__XXX

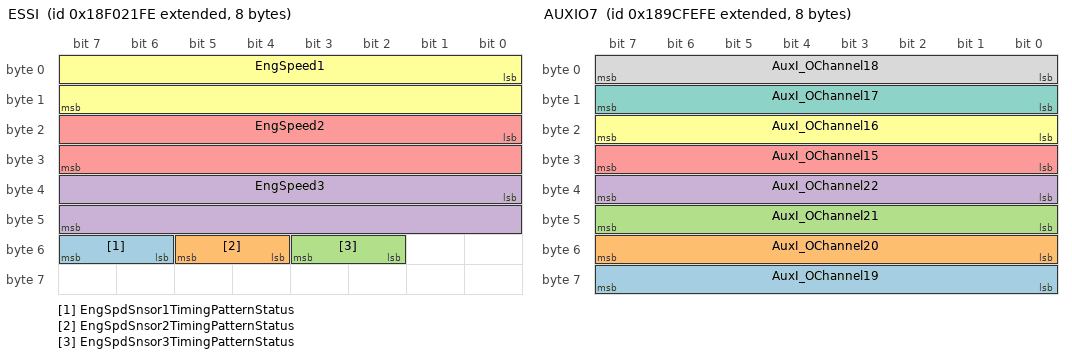
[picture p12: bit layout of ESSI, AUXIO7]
BO_ 2565874174 ESSI: 8 Vector__XXX
 SG_ EngSpdSnsor1TimingPatternStatus : 54|2@1+ (1,0) [0|3] "" Vector__XXX
 SG_ EngSpdSnsor2TimingPatternStatus : 52|2@1+ (1,0) [0|3] "" Vector__XXX
 SG_ EngSpdSnsor3TimingPatternStatus : 50|2@1+ (1,0) [0|3] "" Vector__XXX
 SG_ EngSpeed3 : 32|16@1+ (0.5,0) [0|32127.5] "rpm" Vector__XXX
 SG_ EngSpeed2 : 16|16@1+ (0.5,0) [0|32127.5] "rpm" Vector__XXX
 SG_ EngSpeed1 : 0|16@1+ (0.5,0) [0|32127.5] "rpm" Vector__XXX

BO_ 2432520958 ECCVC: 8 Vector__XXX
 SG_ DsrdEngCoolantThermostatOpening : 16|8@1+ (0.4,0) [0|100] "%" Vector__XXX
 SG_ DesiredEngCoolantPumpOutletTemp : 8|8@1+ (1,-40) [-40|210] "degC" Vector__XXX
 SG_ EngCoolantThermostatMode : 0|2@1+ (1,0) [0|3] "" Vector__XXX

BO_ 2560425726 AUXIO7: 8 Vector__XXX
 SG_ AuxI_OChannel19 : 56|8@1+ (1,0) [0|250] "" Vector__XXX
 SG_ AuxI_OChannel20 : 48|8@1+ (1,0) [0|250] "" Vector__XXX
 SG_ AuxI_OChannel21 : 40|8@1+ (1,0) [0|250] "" Vector__XXX
 SG_ AuxI_OChannel22 : 32|8@1+ (1,0) [0|250] "" Vector__XXX
 SG_ AuxI_OChannel15 : 24|8@1+ (1,0) [0|250] "" Vector__XXX
 SG_ AuxI_OChannel16 : 16|8@1+ (1,0) [0|250] "" Vector__XXX
 SG_ AuxI_OChannel17 : 8|8@1+ (1,0) [0|250] "" Vector__XXX
 SG_ AuxI_OChannel18 : 0|8@1+ (1,0) [0|250] "" Vector__XXX

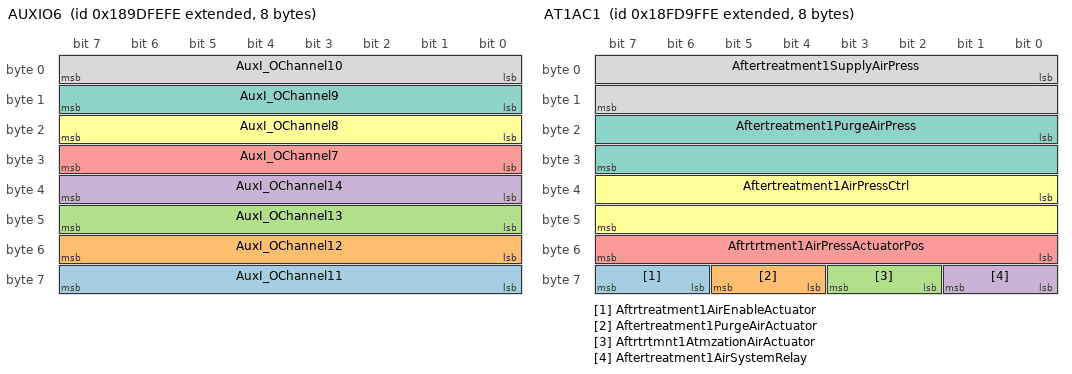
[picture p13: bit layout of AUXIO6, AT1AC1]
BO_ 2560491262 AUXIO6: 8 Vector__XXX
 SG_ AuxI_OChannel11 : 56|8@1+ (1,0) [0|250] "" Vector__XXX
 SG_ AuxI_OChannel12 : 48|8@1+ (1,0) [0|250] "" Vector__XXX
 SG_ AuxI_OChannel13 : 40|8@1+ (1,0) [0|250] "" Vector__XXX
 SG_ AuxI_OChannel14 : 32|8@1+ (1,0) [0|250] "" Vector__XXX
 SG_ AuxI_OChannel7 : 24|8@1+ (1,0) [0|250] "" Vector__XXX
 SG_ AuxI_OChannel8 : 16|8@1+ (1,0) [0|250] "" Vector__XXX
 SG_ AuxI_OChannel9 : 8|8@1+ (1,0) [0|250] "" Vector__XXX
 SG_ AuxI_OChannel10 : 0|8@1+ (1,0) [0|250] "" Vector__XXX

BO_ 2349399806 AUXIO5: 8 Vector__XXX
 SG_ AuxI_OChannel3 : 48|16@1+ (1,0) [0|64255] "counts" Vector__XXX
 SG_ AuxI_OChannel4 : 32|16@1+ (1,0) [0|64255] "counts" Vector__XXX
 SG_ AuxI_OChannel5 : 16|16@1+ (1,0) [0|64255] "counts" Vector__XXX
 SG_ AuxI_OChannel6 : 0|16@1+ (1,0) [0|64255] "counts" Vector__XXX

BO_ 2566758398 AT1AC1: 8 Vector__XXX
 SG_ Aftrtreatment1AirEnableActuator : 62|2@1+ (1,0) [0|3] "" Vector__XXX
 SG_ Aftertreatment1PurgeAirActuator : 60|2@1+ (1,0) [0|3] "" Vector__XXX
 SG_ Aftrtrtmnt1AtmzationAirActuator : 58|2@1+ (1,0) [0|3] "" Vector__XXX
 SG_ Aftertreatment1AirSystemRelay : 56|2@1+ (1,0) [0|3] "" Vector__XXX
 SG_ Aftrtrtment1AirPressActuatorPos : 48|8@1+ (0.4,0) [0|100] "%" Vector__XXX
 SG_ Aftertreatment1AirPressCtrl : 32|16@1+ (0.0025,0) [0|160.6375] "%" Vector__XXX
 SG_ Aftertreatment1PurgeAirPress : 16|16@1+ (0.1,0) [0|6425.5] "kPa" Vector__XXX
 SG_ Aftertreatment1SupplyAirPress : 0|16@1+ (0.1,0) [0|6425.5] "kPa" Vector__XXX

BO_ 2566745598 AT1AC2: 8 Vector__XXX
 SG_ Aftertreatment1SecondAirPress : 48|16@1+ (0.1,0) [0|6425.5] "kPa" Vector__XXX
 SG_ Aftrtreatment1SecondAirMassFlow : 32|16@1+ (0.2,0) [0|12851] "kg/h" Vector__XXX
 SG_ Aftertreatment1SecondAirTemp : 16|16@1+ (0.03125,-273) [-273|1734.96875] "degC" Vector__XXX
 SG_ Aftrtratment1SecondAirDiffPress : 0|16@1+ (0.0078125,-250) [-250|251.99] "kPa" Vector__XXX

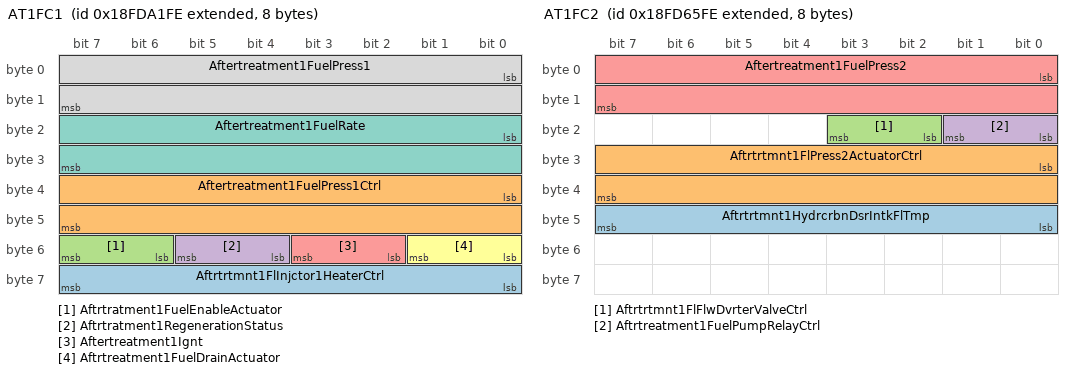
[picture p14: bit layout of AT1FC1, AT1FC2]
BO_ 2566758910 AT1FC1: 8 Vector__XXX
 SG_ Aftrtrtmnt1FlInjctor1HeaterCtrl : 56|8@1+ (0.4,0) [0|100] "%" Vector__XXX
 SG_ Aftertreatment1FuelPress1Ctrl : 32|16@1+ (0.0025,0) [0|160.6375] "%" Vector__XXX
 SG_ Aftrtratment1FuelEnableActuator : 54|2@1+ (1,0) [0|3] "" Vector__XXX
 SG_ Aftrtratment1RegenerationStatus : 52|2@1+ (1,0) [0|3] "" Vector__XXX
 SG_ Aftertreatment1Ignt : 50|2@1+ (1,0) [0|3] "" Vector__XXX
 SG_ Aftrtreatment1FuelDrainActuator : 48|2@1+ (1,0) [0|3] "" Vector__XXX
 SG_ Aftertreatment1FuelRate : 16|16@1+ (0.05,0) [0|3212.75] "L/h" Vector__XXX
 SG_ Aftertreatment1FuelPress1 : 0|16@1+ (0.1,0) [0|6425.5] "kPa" Vector__XXX

BO_ 2566743550 AT1FC2: 8 Vector__XXX
 SG_ Aftrtrtmnt1HydrcrbnDsrIntkFlTmp : 40|8@1+ (1,-40) [-40|210] "degC" Vector__XXX
 SG_ Aftrtrtmnt1FlPress2ActuatorCtrl : 24|16@1+ (0.0025,0) [0|160.6375] "%" Vector__XXX
 SG_ Aftrtrtmnt1FlFlwDvrterValveCtrl : 18|2@1+ (1,0) [0|3] "" Vector__XXX
 SG_ Aftrtreatment1FuelPumpRelayCtrl : 16|2@1+ (1,0) [0|3] "" Vector__XXX
 SG_ Aftertreatment1FuelPress2 : 0|16@1+ (0.1,0) [0|6425.5] "kPa" Vector__XXX

BO_ 2566753534 AT1GP: 8 Vector__XXX
 SG_ DslPrticulateFilterOutletPress1 : 16|16@1+ (0.1,0) [0|6425.5] "kPa" Vector__XXX
 SG_ DslPrticulateFilterIntakePress1 : 0|16@1+ (0.1,0) [0|6425.5] "kPa" Vector__XXX

BO_ 2566756606 AT1HI: 36 Vector__XXX
 SG_ Aftrtrtmnt1TtlNmbrOfActvRgnrtnMn : 224|32@1+ (1,0) [0|4294967295] "counts" Vector__XXX
 SG_ Aftrtrtmnt1TtlNmbrOfActvRgnrtnIn : 192|32@1+ (1,0) [0|4294967295] "counts" Vector__XXX
 SG_ Aftrtrtmnt1AvrgTmBtwnActvRgnrtns : 256|32@1+ (1,0) [0|4211081215] "s" Vector__XXX
 SG_ Aftrtrtmnt1TtlNmbrOfPssvRgnrtns : 160|32@1+ (1,0) [0|4294967295] "counts" Vector__XXX
 SG_ Aftrtrtmnt1TtlPssvRgnrationTime : 128|32@1+ (1,0) [0|4211081215] "s" Vector__XXX
 SG_ Aftrtrtmnt1TtlNmbrOfActvRgnrtns : 96|32@1+ (1,0) [0|4294967295] "counts" Vector__XXX
 SG_ Aftrtreatment1TotalDisabledTime : 64|32@1+ (1,0) [0|4211081215] "s" Vector__XXX
 SG_ Aftrtrtmnt1TtalRegenerationTime : 32|32@1+ (1,0) [0|4211081215] "s" Vector__XXX
 SG_ Aftertreatment1TotalFuelUsed : 0|32@1+ (0.5,0) [0|2105540607.5] "L" Vector__XXX

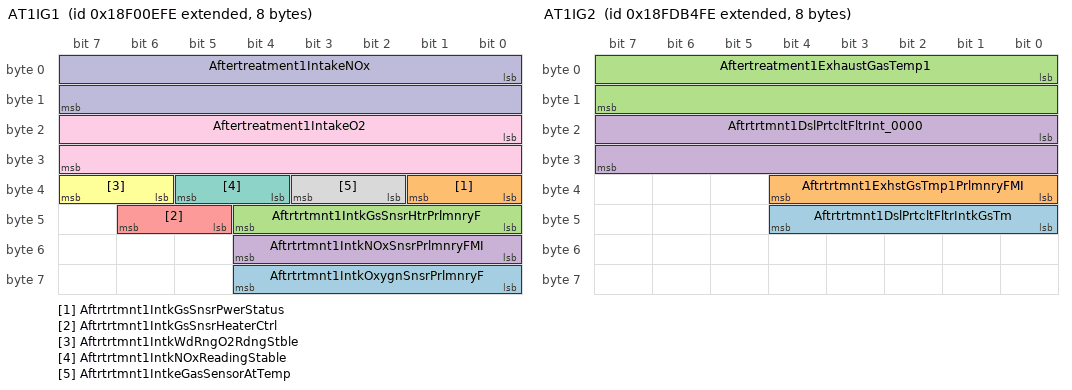
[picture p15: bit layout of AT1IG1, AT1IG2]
BO_ 2565869310 AT1IG1: 8 Vector__XXX
 SG_ Aftrtrtmnt1IntkOxygnSnsrPrlmnryF : 56|5@1+ (1,0) [0|31] "" Vector__XXX
 SG_ Aftrtrtmnt1IntkGsSnsrPwerStatus : 32|2@1+ (1,0) [0|3] "" Vector__XXX
 SG_ Aftrtrtmnt1IntkGsSnsrHtrPrlmnryF : 40|5@1+ (1,0) [0|31] "" Vector__XXX
 SG_ Aftrtrtmnt1IntkNOxSnsrPrlmnryFMI : 48|5@1+ (1,0) [0|31] "" Vector__XXX
 SG_ Aftrtrtmnt1IntkGsSnsrHeaterCtrl : 45|2@1+ (1,0) [0|3] "" Vector__XXX
 SG_ Aftrtrtmnt1IntkWdRngO2RdngStble : 38|2@1+ (1,0) [0|3] "" Vector__XXX
 SG_ Aftrtrtmnt1IntkNOxReadingStable : 36|2@1+ (1,0) [0|3] "" Vector__XXX
 SG_ Aftrtrtmnt1IntkeGasSensorAtTemp : 34|2@1+ (1,0) [0|3] "" Vector__XXX
 SG_ Aftertreatment1IntakeO2 : 16|16@1+ (0.000514,-12) [-12|21] "%" Vector__XXX
 SG_ Aftertreatment1IntakeNOx : 0|16@1+ (0.05,-200) [-200|3012.75] "ppm" Vector__XXX

BO_ 2566763774 AT1IG2: 8 Vector__XXX
 SG_ Aftrtrtmnt1DslPrtcltFltrIntkGsTm : 40|5@1+ (1,0) [0|31] "" Vector__XXX
 SG_ Aftrtrtmnt1ExhstGsTmp1PrlmnryFMI : 32|5@1+ (1,0) [0|31] "" Vector__XXX
 SG_ Aftertreatment1ExhaustGasTemp1 : 0|16@1+ (0.03125,-273) [-273|1734.96875] "degC" Vector__XXX
 SG_ Aftrtrtmnt1DslPrtcltFltrInt_0000 : 16|16@1+ (0.03125,-273) [-273|1734.96875] "degC" Vector__XXX

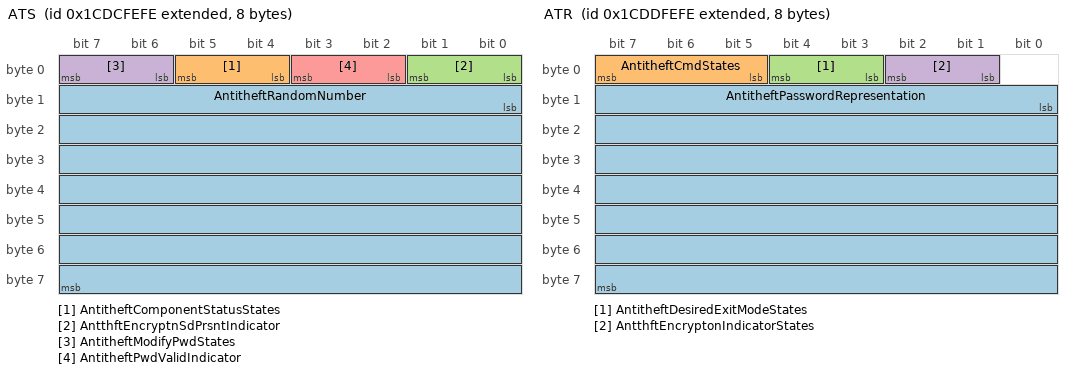
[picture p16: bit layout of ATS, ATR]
BO_ 2631728894 ATS: 8 Vector__XXX
 SG_ AntitheftRandomNumber : 8|56@1+ (1,0) [0|255] "" Vector__XXX
 SG_ AntitheftComponentStatusStates : 4|2@1+ (1,0) [0|3] "" Vector__XXX
 SG_ AntthftEncryptnSdPrsntIndicator : 0|2@1+ (1,0) [0|3] "" Vector__XXX
 SG_ AntitheftModifyPwdStates : 6|2@1+ (1,0) [0|3] "" Vector__XXX
 SG_ AntitheftPwdValidIndicator : 2|2@1+ (1,0) [0|3] "" Vector__XXX

BO_ 2631794430 ATR: 8 Vector__XXX
 SG_ AntitheftPasswordRepresentation : 8|56@1+ (1,0) [0|255] "" Vector__XXX
 SG_ AntitheftCmdStates : 5|3@1+ (1,0) [0|7] "" Vector__XXX
 SG_ AntitheftDesiredExitModeStates : 3|2@1+ (1,0) [0|3] "" Vector__XXX
 SG_ AntthftEncryptonIndicatorStates : 1|2@1+ (1,0) [0|3] "" Vector__XXX

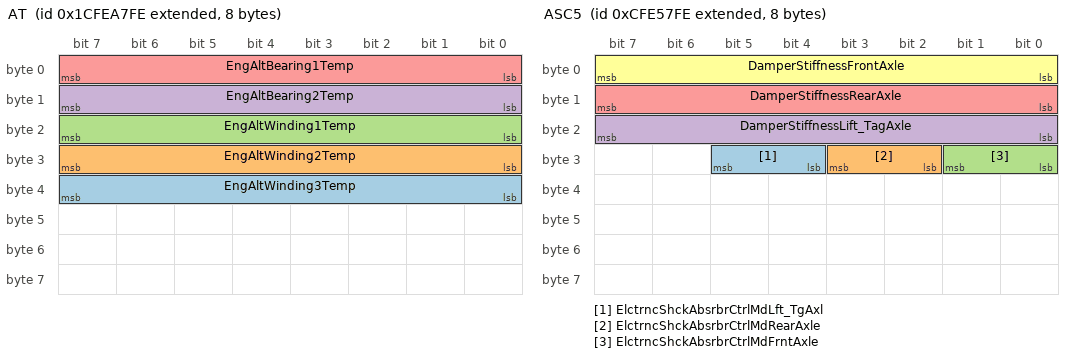
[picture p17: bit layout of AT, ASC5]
BO_ 2633934846 AT: 8 Vector__XXX
 SG_ EngAltWinding3Temp : 32|8@1+ (1,-40) [-40|210] "degC" Vector__XXX
 SG_ EngAltWinding2Temp : 24|8@1+ (1,-40) [-40|210] "degC" Vector__XXX
 SG_ EngAltWinding1Temp : 16|8@1+ (1,-40) [-40|210] "degC" Vector__XXX
 SG_ EngAltBearing2Temp : 8|8@1+ (1,-40) [-40|210] "degC" Vector__XXX
 SG_ EngAltBearing1Temp : 0|8@1+ (1,-40) [-40|210] "degC" Vector__XXX

BO_ 2362572542 ASC6: 8 Vector__XXX
 SG_ LevelPresetRearAxleRight : 48|16@1+ (0.1,-3200) [-3200|3225.5] "mm" Vector__XXX
 SG_ LevelPresetRearAxleLeft : 32|16@1+ (0.1,-3200) [-3200|3225.5] "mm" Vector__XXX
 SG_ LevelPresetFrontAxleRight : 16|16@1+ (0.1,-3200) [-3200|3225.5] "mm" Vector__XXX
 SG_ LevelPresetFrontAxleLeft : 0|16@1+ (0.1,-3200) [-3200|3225.5] "mm" Vector__XXX

BO_ 2365478910 ASC5: 8 Vector__XXX
 SG_ ElctrncShckAbsrbrCtrlMdLft_TgAxl : 28|2@1+ (1,0) [0|3] "" Vector__XXX
 SG_ ElctrncShckAbsrbrCtrlMdRearAxle : 26|2@1+ (1,0) [0|3] "" Vector__XXX
 SG_ ElctrncShckAbsrbrCtrlMdFrntAxle : 24|2@1+ (1,0) [0|3] "" Vector__XXX
 SG_ DamperStiffnessLift_TagAxle : 16|8@1+ (0.4,0) [0|100] "%" Vector__XXX
 SG_ DamperStiffnessRearAxle : 8|8@1+ (0.4,0) [0|100] "%" Vector__XXX
 SG_ DamperStiffnessFrontAxle : 0|8@1+ (0.4,0) [0|100] "%" Vector__XXX

BO_ 2560950014 DM30: 12 Vector__XXX
 SG_ TestLimitMinimum : 80|16@1+ (1,0) [0|64255] "" Vector__XXX
 SG_ TestLimitMaximum : 64|16@1+ (1,0) [0|64255] "" Vector__XXX
 SG_ TestValue : 48|16@1+ (1,0) [0|64255] "" Vector__XXX
 SG_ SlotId : 32|16@1+ (1,0) [0|64255] "" Vector__XXX
 SG_ TestIdentifier : 0|8@1+ (1,0) [0|255] "" Vector__XXX
 SG_ FailureModeIdentifier1 : 24|5@1+ (1,0) [0|0] "" Vector__XXX
 SG_ SPN1High : 29|3@1+ (1,0) [0|7] "" Vector__XXX
 SG_ SPN1 : 8|16@1+ (1,0) [0|65536] "" Vector__XXX

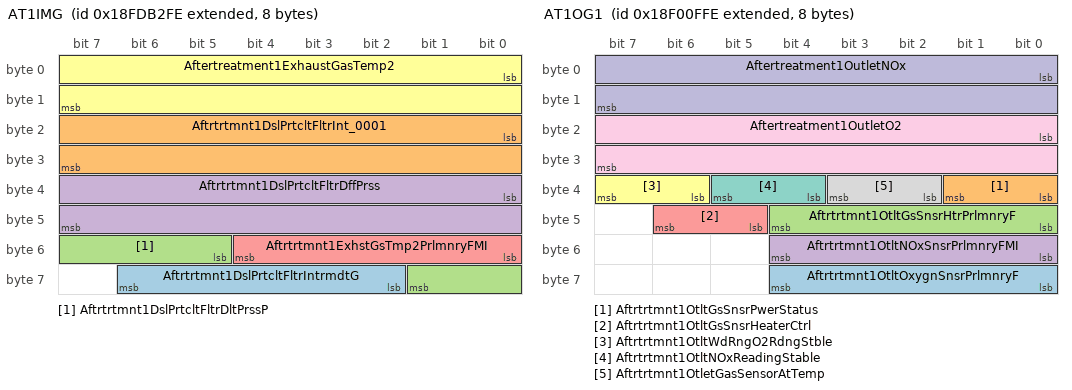
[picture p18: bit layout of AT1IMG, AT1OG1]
BO_ 2566763262 AT1IMG: 8 Vector__XXX
 SG_ Aftrtrtmnt1DslPrtcltFltrIntrmdtG : 58|5@1+ (1,0) [0|31] "" Vector__XXX
 SG_ Aftrtrtmnt1DslPrtcltFltrInt_0001 : 16|16@1+ (0.03125,-273) [-273|1734.96875] "degC" Vector__XXX
 SG_ Aftrtrtmnt1DslPrtcltFltrDltPrssP : 53|5@1+ (1,0) [0|31] "" Vector__XXX
 SG_ Aftrtrtmnt1DslPrtcltFltrDffPrss : 32|16@1+ (0.1,0) [0|6425.5] "kPa" Vector__XXX
 SG_ Aftrtrtmnt1ExhstGsTmp2PrlmnryFMI : 48|5@1+ (1,0) [0|31] "" Vector__XXX
 SG_ Aftertreatment1ExhaustGasTemp2 : 0|16@1+ (0.03125,-273) [-273|1734.96875] "degC" Vector__XXX

BO_ 2565869566 AT1OG1: 8 Vector__XXX
 SG_ Aftrtrtmnt1OtltOxygnSnsrPrlmnryF : 56|5@1+ (1,0) [0|31] "" Vector__XXX
 SG_ Aftrtrtmnt1OtltGsSnsrPwerStatus : 32|2@1+ (1,0) [0|3] "" Vector__XXX
 SG_ Aftrtrtmnt1OtltGsSnsrHtrPrlmnryF : 40|5@1+ (1,0) [0|31] "" Vector__XXX
 SG_ Aftrtrtmnt1OtltNOxSnsrPrlmnryFMI : 48|5@1+ (1,0) [0|31] "" Vector__XXX
 SG_ Aftrtrtmnt1OtltGsSnsrHeaterCtrl : 45|2@1+ (1,0) [0|3] "" Vector__XXX
 SG_ Aftrtrtmnt1OtltWdRngO2RdngStble : 38|2@1+ (1,0) [0|3] "" Vector__XXX
 SG_ Aftrtrtmnt1OtltNOxReadingStable : 36|2@1+ (1,0) [0|3] "" Vector__XXX
 SG_ Aftrtrtmnt1OtletGasSensorAtTemp : 34|2@1+ (1,0) [0|3] "" Vector__XXX
 SG_ Aftertreatment1OutletO2 : 16|16@1+ (0.000514,-12) [-12|21] "%" Vector__XXX
 SG_ Aftertreatment1OutletNOx : 0|16@1+ (0.05,-200) [-200|3012.75] "ppm" Vector__XXX

BO_ 2566763518 AT1OG2: 8 Vector__XXX
 SG_ Aftrtrtmnt1DslPrtcltFltrOtltGsTm : 16|16@1+ (0.03125,-273) [-273|1734.96875] "degC" Vector__XXX
 SG_ Aftrtrtmnt1DslPrtcltFltrOtltExhs : 40|5@1+ (1,0) [0|31] "" Vector__XXX
 SG_ Aftrtrtmnt1ExhstGsTmp3PrlmnryFMI : 32|5@1+ (1,0) [0|31] "" Vector__XXX
 SG_ Aftertreatment1ExhaustGasTemp3 : 0|16@1+ (0.03125,-273) [-273|1734.96875] "degC" Vector__XXX

BO_ 2566749182 AT1S: 8 Vector__XXX
 SG_ DslPrtclteFilter1AshLoadPercent : 8|8@1+ (1,0) [0|250] "%" Vector__XXX
 SG_ DslPrtcltFltr1TmSncLstActvRgnrtn : 16|32@1+ (1,0) [0|4211081215] "s" Vector__XXX
 SG_ DslPrtcltFilter1SootLoadPercent : 0|8@1+ (1,0) [0|250] "%" Vector__XXX
 SG_ Aftrtrtmnt1DslPrtcltFltrStLdRgnr : 48|16@1+ (0.0025,0) [0|160.6375] "%" Vector__XXX

BO_ 2566748670 AT1TI: 32 Vector__XXX
 SG_ Aftrtrtmnt1TrpNmbrOfActvRgnrtnMn : 224|32@1+ (1,0) [0|4294967295] "counts" Vector__XXX
 SG_ Aftrtrtmnt1TrpNmbrOfActvRgnrtnIn : 192|32@1+ (1,0) [0|4294967295] "counts" Vector__XXX
 SG_ Aftrtrtmnt1TrpNmbrOfPssvRgnrtns : 160|32@1+ (1,0) [0|4294967295] "counts" Vector__XXX
 SG_ Aftrtrtmnt1TrpPssvRgnrationTime : 128|32@1+ (1,0) [0|4211081215] "s" Vector__XXX
 SG_ Aftrtrtmnt1TrpNmbrOfActvRgnrtns : 96|32@1+ (1,0) [0|4294967295] "counts" Vector__XXX
 SG_ Aftertreatment1TripDisabledTime : 64|32@1+ (1,0) [0|4211081215] "s" Vector__XXX
 SG_ Aftrtrtmnt1TrpActvRgnrationTime : 32|32@1+ (1,0) [0|4211081215] "s" Vector__XXX
 SG_ Aftertreatment1TripFuelUsed : 0|32@1+ (0.5,0) [0|2105540607.5] "L" Vector__XXX

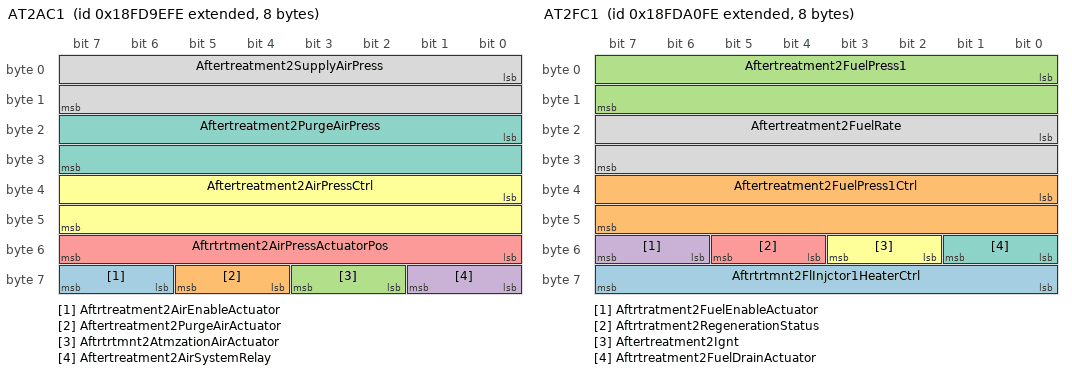
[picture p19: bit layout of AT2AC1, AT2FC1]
BO_ 2566758142 AT2AC1: 8 Vector__XXX
 SG_ Aftrtreatment2AirEnableActuator : 62|2@1+ (1,0) [0|3] "" Vector__XXX
 SG_ Aftertreatment2PurgeAirActuator : 60|2@1+ (1,0) [0|3] "" Vector__XXX
 SG_ Aftrtrtmnt2AtmzationAirActuator : 58|2@1+ (1,0) [0|3] "" Vector__XXX
 SG_ Aftertreatment2AirSystemRelay : 56|2@1+ (1,0) [0|3] "" Vector__XXX
 SG_ Aftrtrtment2AirPressActuatorPos : 48|8@1+ (0.4,0) [0|100] "%" Vector__XXX
 SG_ Aftertreatment2AirPressCtrl : 32|16@1+ (0.0025,0) [0|160.6375] "%" Vector__XXX
 SG_ Aftertreatment2PurgeAirPress : 16|16@1+ (0.1,0) [0|6425.5] "kPa" Vector__XXX
 SG_ Aftertreatment2SupplyAirPress : 0|16@1+ (0.1,0) [0|6425.5] "kPa" Vector__XXX

BO_ 2566745342 AT2AC2: 8 Vector__XXX
 SG_ Aftertreatment2SecondAirPress : 48|16@1+ (0.1,0) [0|6425.5] "kPa" Vector__XXX
 SG_ Aftrtreatment2SecondAirMassFlow : 32|16@1+ (0.2,0) [0|12851] "kg/h" Vector__XXX
 SG_ Aftertreatment2SecondAirTemp : 16|16@1+ (0.03125,-273) [-273|1734.96875] "degC" Vector__XXX
 SG_ Aftrtratment2SecondAirDiffPress : 0|16@1+ (0.0078125,-250) [-250|251.99] "kPa" Vector__XXX

BO_ 2566758654 AT2FC1: 8 Vector__XXX
 SG_ Aftrtrtmnt2FlInjctor1HeaterCtrl : 56|8@1+ (0.4,0) [0|100] "%" Vector__XXX
 SG_ Aftertreatment2FuelPress1Ctrl : 32|16@1+ (0.0025,0) [0|160.6375] "%" Vector__XXX
 SG_ Aftertreatment2FuelPress1 : 0|16@1+ (0.1,0) [0|6425.5] "kPa" Vector__XXX
 SG_ Aftrtratment2FuelEnableActuator : 54|2@1+ (1,0) [0|3] "" Vector__XXX
 SG_ Aftrtratment2RegenerationStatus : 52|2@1+ (1,0) [0|3] "" Vector__XXX
 SG_ Aftertreatment2Ignt : 50|2@1+ (1,0) [0|3] "" Vector__XXX
 SG_ Aftrtreatment2FuelDrainActuator : 48|2@1+ (1,0) [0|3] "" Vector__XXX
 SG_ Aftertreatment2FuelRate : 16|16@1+ (0.05,0) [0|3212.75] "L/h" Vector__XXX

CM_ BO_ 2364549886 "Angular Rate Information";
CM_ SG_ 2364549886 AngularRateMeasurementLatency "The estimated measurement latency of the measurement.";
CM_ SG_ 2364549886 YawRateExRangeFigureOfMerit "Figure of merit for yaw angle measurement.";
CM_ SG_ 2364549886 RollRateExRangeFigureOfMerit "Figure of merit for roll angle measurement.";
CM_ SG_ 2364549886 PitchRateExRangeFigureOfMerit "Figure of merit for pitch angle measurement.";
CM_ SG_ 2364549886 YawRateExRange "Yaw rate is the rate-of-change of the yaw angle over time.";
CM_ SG_ 2364549886 RollRateExRange "Roll rate is the rate-of-change of the roll angle over time.";
CM_ SG_ 2364549886 PitchRateExRange "Pitch rate is the rate-of-change of the pitch angle over time, where the pitch angle vector is in the direction of travel of the";
CM_ BO_ 2566712318 "Aftertreatment 2 NOx Adsorber Information";
CM_ SG_ 2566712318 Aftrtrtmnt2NOxAdsrbrDSOxRgnrtnSt "Indicates whether the NOx adsorber deSOx regeneration in the second aftertreatment system is active or inactive";
CM_ SG_ 2566712318 Aftrtrtmnt2NOxAdsrbrDNOxRgnrtnSt "Indicates whether the NOx adsorber deNOx regeneration in the second aftertreatment system is active or inactive";
CM_ BO_ 2566712574 "Aftertreatment 1 NOx Adsorber Information";
CM_ SG_ 2566712574 Aftrtrtmnt1NOxAdsrbrDSOxRgnrtnSt "Indicates whether the NOx adsorber deSOx regeneration in the first aftertreatment system is active or inactive";
CM_ SG_ 2566712574 Aftrtrtmnt1NOxAdsrbrDNOxRgnrtnSt "Indicates whether the NOx adsorber deNOx regeneration in the first aftertreatment system is active or inactive";
CM_ BO_ 2164078590 "Aftertreatment 2 SCR Service Information";
CM_ SG_ 2164078590 Aftrtrtmnt2SCRCtlystCnvrsnEffcnc "The SCR catalyst conversion efficiency percentage.";
CM_ SG_ 2164078590 Aftrtrtmnt2SCRCmddCtlystRgntCnsm "This parameter transmits the amount of reagent that the emissions control system has requested to be used, averaged";
CM_ SG_ 2164078590 Aftrtrtmnt2SCRAvrgCtlystRgntCnsm "Measured use of reagent by a Selective Catalytic Reduction system for exhaust emission control, averaged over the";
CM_ BO_ 2566731006 "Aftertreatment 2 SCR Reagant Tank 2 Information";
CM_ SG_ 2566731006 Aftrtrtmnt2SCRCtlystRgntTnk2HtrP "Used to identify the applicable J1939-73 FMI detected in the SCR catalyst reagent tank 2 heater, by the manufacturer's";
CM_ SG_ 2566731006 Aftrtrtmnt2SCRCtlystRgntTnk2Htr "The SCR catalyst reagent tank 2 heater percentage for aftertreatment system 1 (exhaust bank 1).";
CM_ SG_ 2566731006 Aftrtrtmnt2SCRRgntTnk2TmpPrlmnry "Used to identify the applicable J1939-73 FMI detected in the SCR catalyst reagent tank 2 temperature, by the";
CM_ SG_ 2566731006 Aftrtrtmnt2SCRCtlystRgntTnk2LvlP "Used to identify the applicable J1939-73 FMI detected in the SCR catalyst reagent tank 2 level, by the manufacturer's";
CM_ SG_ 2566731006 Aftrtrtmnt2SCRCtlystRgntTnk2Lvl2 "The SCR catalyst reagent tank 2 level height in mm for aftertreatment system 2 (exhaust bank 2).";
CM_ SG_ 2566731006 Aftrtrtmnt2SCRCtlystRgntTnk2Tmp "The SCR catalyst reagent tank 2 temperature for aftertreatment system 2 (exhaust bank 2).";
CM_ SG_ 2566731006 Aftrtrtmnt2SCRCtlystRgntTnk2Lvl "The SCR catalyst reagent tank 2 level percentage for aftertreatment system 2 (exhaust bank 2).";
CM_ BO_ 2566731262 "Aftertreatment 2 SCR Reagant Tank 1 Information";
CM_ SG_ 2566731262 Aftrtrtmnt2SCRCtlystRgntTnk1HtrP "Used to identify the applicable J1939-73 FMI detected in the SCR catalyst reagent tank 1 heater, by the manufacturer's";
CM_ SG_ 2566731262 Aftrtrtmnt2SCRCtalystTankHeater "Percentage of heating applied to the aftertreatment 2 catalyst tank heater.";
CM_ SG_ 2566731262 Aftrtrtmnt2SCRCtlystRgntTnk1TmpP "Used to identify the applicable J1939-73 FMI detected in the SCR catalyst reagent tank 1 temperature, by the";
CM_ SG_ 2566731262 Aftrtrtmnt2SCRCtlystTnkLvlPrlmnr "Used to identify the applicable J1939-73 FMI that applies to the most significant failure of the catalyst tank level sensor.";
CM_ SG_ 2566731262 Aftrtrtmnt2SCRCtalystTankLevel2 "The measure of the reagent level in the catalyst tank.";
CM_ SG_ 2566731262 Aftrtrtment2SCRCatalystTankTemp "Temperature of the reagent in the storage tank.";
CM_ SG_ 2566731262 Aftrtrtmnt2SCRCatalystTankLevel "A special catalyst uses chemical substance to reach legal requirement for NOX emissions.";
CM_ BO_ 2566730750 "Aftertreatment 2 SCR Reagent Supply Information";
CM_ SG_ 2566730750 Aftrtrtmnt2SCRCtlystRgntTnkDrnVl "Commanded percentage of maximum Aftertreatment 2 SCR Catalyst Reagent Tank Drain Valve opening.";
CM_ SG_ 2566730750 Aftrtrtmnt2SCRCtlystRgntPmpStte "State of aftertreatment 2 SCR Catalyst Reagent dosing pump.";
CM_ SG_ 2566730750 Aftrtrtmnt2SCRCtlystRgntTnkFllVl "Commanded percentage of maximum Aftertreatment 2 SCR Catalyst Reagent Tank Fill Valve opening.";
CM_ SG_ 2566730750 Aftrtrtmnt2SCRCtlystRgntRtrnVlv "Command to the valve which determines whether the reagent is delivered to the injector or is routed back to the reagent";
CM_ SG_ 2566730750 Aftrtrtmnt2SCRCtlystRgntPmpDrvPr "The percent (command) sent to the motor to control the speed of the reagent pump.";
CM_ SG_ 2566730750 Aftrtrtmnt2SCRCtlystRgntPmpMtrSp "Rotational speed of the motor driving a pump for reagent used in an aftertreatment system.";
CM_ BO_ 2566731518 "Aftertreatment 2 SCR Reagent Information";
CM_ SG_ 2566731518 Aftrtrtmnt2SCRCtlystReagentType "This parameter indicates what reagent is in the tank.";
CM_ SG_ 2566731518 Aftrtrtmnt2SCRCtlystRgntPrprtsPr "Used to identify the applicable J1939-73 FMI that applies to the most significant failure of the catalyst reagent properties";
CM_ SG_ 2566731518 Aftrtrtmnt2SCRCtlystRgntTmp2Prlm "Used to identify the applicable J1939-73 FMI that applies to the most significant failure of the catalyst temperature sensor.";
CM_ SG_ 2566731518 Aftrtrtmnt2SCRCtlystRgntCndctvty "A measure of the conductivity of the reagent or fluid at the sensor.";
CM_ SG_ 2566731518 Aftrtrtmnt2SCRCtlystRgntCncntrtn "A measure of the concentration of urea in water.";
CM_ SG_ 2566731518 Aftrtrtmnt2SCRCtlystRagentTemp2 "Temperature of the catalyst reagent at the device measuring reagent quality";
CM_ BO_ 2566732030 "Aftertreatment 2 SCR Exhaust Gas Temperature";
CM_ SG_ 2566732030 Aftrtrtmnt2SCRCtlystOtltGsTmpPrl "Used to identify the applicable J1939-73 FMI detected in the SCR catalyst outlet gas temperature sensor by the";
CM_ SG_ 2566732030 Aftrtrtmnt2SCRCtlystOtltGasTemp "Temperature of engine combustion byproducts leaving the SCR catalyst exhaust in exhaust bank 2.";
CM_ SG_ 2566732030 Aftrtrtmnt2SCRCtlystIntkGsTmpPrl "Used to identify the applicable J1939-73 FMI detected in the SCR catalyst intake gas temperature sensor by the";
CM_ SG_ 2566732030 Aftrtrtmnt2SCRCtlystIntkGasTemp "Temperature of engine combustion byproducts entering the SCR catalyst in exhaust bank 2.";
CM_ BO_ 2566732286 "Aftertreatment 2 SCR Exhaust Gas Pressures";
CM_ SG_ 2566732286 Aftrtrtmnt2SCRCtlystExhstGsDffPr "Used to identify the applicable J1939-73 FMI detected in the SCR catalyst differential pressure sensor by the";
CM_ SG_ 2566732286 Aftrtrtmnt2SCRCtlystExhstGs_0000 "Exhaust differential pressure measured between the intake and exhaust of a SCR catalyst in exhaust bank 2.";
CM_ BO_ 2164079358 "Aftertreatment 2 SCR Dosing System Requests 2";
CM_ SG_ 2164079358 Aftrtrtmnt2SCRCtlystTnk2HterCmd "This is the command for the Aftertreatment 2 SCR Catalyst Tank 2 Heater.";
CM_ SG_ 2164079358 Aftrtrtmnt2SCRCtlystTnkHaterCmd "Command for the Aftertreatment 2 SCR Catalyst Tank Heater.";
CM_ SG_ 2164079358 Aftrtrtmnt2SCRCtlystRgntLnHter4 "The SCR catalyst reagent line heater 4 request for aftertreatment system 2 (exhaust bank 2).";
CM_ SG_ 2164079358 Aftrtrtmnt2SCRCtlystRgntLnHter3 "The SCR catalyst reagent line heater 3 request for aftertreatment system 2 (exhaust bank 2).";
CM_ SG_ 2164079358 Aftrtrtmnt2SCRCtlystRgntLnHter2 "The SCR catalyst reagent line heater 2 request for aftertreatment system 2 (exhaust bank 2).";
CM_ SG_ 2164079358 Aftrtrtmnt2SCRCtlystRgntLnHter1 "The SCR catalyst reagent line heater 1 request for aftertreatment system 2 (exhaust bank 2).";
CM_ SG_ 2164079358 Aftrtrtmnt2SCRDserHeatingModeRq "Used if multiple heater modes are available in the Doser.";
CM_ SG_ 2164079358 Aftrtrtmnt2SCRDsrFltSpprssionRq "Used if external devices can warn of conditions that require suppression of potential faults in the doser due to";
CM_ BO_ 2364549118 "Aftertreatment 2 SCR Dosing System Requests 1";
CM_ SG_ 2364549118 Aftrtrtmnt2SCRRqdRgntQnttyFrIntg "Represents the command for the reducing agent quantity integrator in the dosing control unit";
CM_ SG_ 2364549118 Aftrtratment2SCRSystemRqedState "Requested state of SCR system for aftertreatment system 2 (exhaust bank 2).";
CM_ SG_ 2364549118 Aftrtrtmnt2SCRRqdDsngRgntQntity "Actual requested dosing quantity of catalyst reagent";
CM_ BO_ 2566732798 "Aftertreatment 2 SCR Dosing System Information 2";
CM_ SG_ 2566732798 Aftrtrtmnt2SCRCtlystRgntLnHtr4Pr "Used to identify the applicable J1939-73 FMI detected in the SCR catalyst reagent line heater 4, by the manufacturer's";
CM_ SG_ 2566732798 Aftrtrtmnt2SCRCtlystRgntLnHtr4St "The SCR catalyst reagent line heater 4 state for aftertreatment system 2 (exhaust bank 2).";
CM_ SG_ 2566732798 Aftrtrtmnt2SCRCtlystRgntLnHtr3Pr "Used to identify the applicable J1939-73 FMI detected in the SCR catalyst reagent line heater 3, by the manufacturer's";
CM_ SG_ 2566732798 Aftrtrtmnt2SCRCtlystRgntLnHtr3St "The SCR catalyst reagent line heater 3 state for aftertreatment system 2 (exhaust bank 2).";
CM_ SG_ 2566732798 Aftrtrtmnt2SCRCtlystRgntLnHtr2Pr "Used to identify the applicable J1939-73 FMI detected in the SCR catalyst reagent line heater 2, by the manufacturer's";
CM_ SG_ 2566732798 Aftrtrtmnt2SCRCtlystRgntLnHtr2St "The SCR catalyst reagent line heater 2 state for aftertreatment system 2 (exhaust bank 2).";
CM_ SG_ 2566732798 Aftrtrtmnt2SCRCtlystRgntLnHtr1Pr "Used to identify the applicable J1939-73 FMI detected in the SCR catalyst reagent line heater 1, by the manufacturer's";
CM_ SG_ 2566732798 Aftrtrtmnt2SCRCtlystRgntLnHtr1St "The SCR catalyst reagent line heater 1 state for aftertreatment system 2 (exhaust bank 2).";
CM_ SG_ 2566732798 Aftrtrtmnt2SCRFedbackCtrlStatus "The SCR feedback control status (open/closed loop) for aftertreatment system 2 (exhaust bank 2).";
CM_ SG_ 2566732798 Aftrtrtmnt2SCRDsngVlvExhstTmpRdc "Protection request for the dosing valve of the SCR-system to prevent overheating";
CM_ SG_ 2566732798 Aftrtrtmnt2SCRDosingReagentTemp "The SCR dosing reagent temperature (measured closest to dosing valve) for aftertreatment system 2 (exhaust bank 2).";
CM_ SG_ 2566732798 Aftrtrtmnt2SCRDsngArAssistValve "The position of the valve used to regulate the air supply of an air assist SCR dosing system for an engine.";
CM_ SG_ 2566732798 Aftrtrtmnt2SCRDsngArAssstAbsPrss "The SCR dosing system air assist absolute pressure for aftertreatment system 2 (exhaust bank 2).";
CM_ BO_ 2364548862 "Aftertreatment 2 SCR Dosing System Information 1";
CM_ SG_ 2364548862 Aftrtrtmnt2SCRDsngRgentAbsPress "The SCR dosing reagent absolute pressure (measured closest to dosing valve) for aftertreatment system 2 (exhaust bank";
CM_ SG_ 2364548862 Aftrtrtmnt2SCRActlRgntQnttyOfInt "The SCR requested reagent integrator total quantity for aftertreatment system 2 (exhaust bank 2).";
CM_ SG_ 2364548862 Aftertreatment2SCRSystemState "Actual state of SCR system";
CM_ SG_ 2364548862 Aftrtrtmnt2SCRActlDsngRgntQntty "Actual reducing agent quantity of SCR system.";
CM_ BO_ 2364549374 "Aftertreatment 2 SCR Ammonia Information";
CM_ SG_ 2364549374 Aftrtrtmnt2OtltNH3GsSnsrHtrCtrl "Indicates the heater status in the warm-up process.";
CM_ SG_ 2364549374 Aftrtrtmnt2OtltNH3GsSnsrHtrPrlmn "Used to identify the applicable J1939-73 FMI detected in the heater of the outlet NH3 exhaust gas sensor by the";
CM_ SG_ 2364549374 Aftrtrtmnt2OtltNH3GsSnsorAtTemp "Indicates that the heater element of the aftertreatment outlet NH3 gas sensor is within the manufacturer's specified range";
CM_ SG_ 2364549374 Aftrtrtmnt2OtltNH3GsSnsrPwrInRng "Indicates that the power supplied to the aftertreatment outlet NH3 gas sensor is within the manufacturer's specification in";
CM_ SG_ 2364549374 Aftrtrtmnt2OtltNH3ReadingStable "Indicates that the NH3 reading of the aftertreatment outlet NH3 sensor is stable as determined by the manufacturer's";
CM_ SG_ 2364549374 Aftrtrtmnt2OtltNH3SnsrPrlmnryFMI "Used to identify the applicable J1939-73 FMI detected in the aftertreatment outlet NH3 sensor by the manufacturer's";
CM_ SG_ 2364549374 Aftertreatment2OutletNH3 "The amount of NH3 in the exhaust exiting the aftertreatment system measured by a NH3 sensor at the aftertreatment";
CM_ BO_ 2566726142 "Aftertreatment 2 Gas Oxidation Catalyst";
CM_ SG_ 2566726142 Aftrtrtmnt2GsOxdtnCtlystDffPrssP "Used to identify the applicable J1939-73 FMI detected in the gas oxidation catalyst differential pressure sensor by the";
CM_ SG_ 2566726142 Aftrtrtmnt2GsOxdtnCtlystOtltGsTm "Used to identify the applicable J1939-73 FMI detected in the gas oxidation catalyst outlet gas temperature sensor by the";
CM_ SG_ 2566726142 Aftrtrtmnt2GsOxdtnCtlystIntkGsTm "Used to identify the applicable J1939-73 FMI detected in the gas oxidation catalyst intake gas temperature sensor by the";
CM_ SG_ 2566726142 Aftrtrtmnt2GsOxdtnCtlystDffPrss "Exhaust differential pressure measured between the intake and exhaust of the gas oxidation catalyst in exhaust bank 2.";
CM_ SG_ 2566726142 Aftrtrtmnt2GsOxdtnCtlystOtl_0000 "Temperature of engine combustion byproducts leaving the gas oxidation catalyst in exhaust bank 2.";
CM_ SG_ 2566726142 Aftrtrtmnt2GsOxdtnCtlystInt_0000 "Temperature of engine combustion byproducts entering the gas oxidation catalyst in exhaust bank 2.";
CM_ BO_ 2566725630 "Aftertreatment 2 Diesel Oxidation Catalyst";
CM_ SG_ 2566725630 Aftrtrtmnt2DslOxdtnCtlystOtltGsT "Used to identify the applicable J1939-73 FMI detected in the diesel oxidation catalyst outlet gas temperature sensor by";
CM_ SG_ 2566725630 Aftrtrtmnt2DslOxdtnCtlystIntkGsT "Used to identify the applicable J1939-73 FMI detected in the diesel oxidation catalyst intake gas temperature sensor by";
CM_ SG_ 2566725630 Aftrtrtmnt2DslOxdtnCtlystDffPrss "Exhaust differential pressure measured between the intake and exhaust of a diesel oxidation catalyst in exhaust bank 2.";
CM_ SG_ 2566725630 Aftrtrtmnt2DslOxdtnCtlystOt_0000 "Temperature of engine combustion byproducts leaving the diesel oxidation catalyst exhaust in exhaust bank 2.";
CM_ SG_ 2566725630 Aftrtrtmnt2DslOxdtnCtlystIn_0000 "Temperature of engine combustion byproducts entering the diesel oxidation catalyst in exhaust bank 2.";
CM_ SG_ 2566725630 Aftrtrtmnt2DslOxdtnCtlystDf_0000 "Used to identify the applicable J1939-73 FMI detected in the diesel oxidation catalyst differential pressure sensor by the";
CM_ BO_ 2566733310 "Aftertreatment 1 SCR Reagant Tank 2 Information";
CM_ SG_ 2566733310 Aftrtrtmnt1SCRCtlystRgntTnk2HtrP "Used to identify the applicable J1939-73 FMI detected in the SCR catalyst reagent tank 2 heater, by the manufacturer's";
CM_ SG_ 2566733310 Aftrtrtmnt1SCRCtlystRgntTnk2Htr "The SCR catalyst reagent tank 2 heater percentage for aftertreatment system 1 (exhaust bank 1).";
CM_ SG_ 2566733310 Aftrtrtmnt1SCRRgntTnk2TmpPrlmnry "Used to identify the applicable J1939-73 FMI detected in the SCR catalyst reagent tank 2 temperature, by the";
CM_ SG_ 2566733310 Aftrtrtmnt1SCRCtlystRgntTnk2LvlP "Used to identify the applicable J1939-73 FMI detected in the SCR catalyst reagent tank 2 level, by the manufacturer's";
CM_ SG_ 2566733310 Aftrtrtmnt1SCRCtlystRgntTnk2Lvl2 "The SCR catalyst reagent tank 2 level height in mm for aftertreatment system 1 (exhaust bank 1).";
CM_ SG_ 2566733310 Aftrtrtmnt1SCRCtlystRgntTnk2Tmp "The SCR catalyst reagent tank 2 temperature for aftertreatment system 1 (exhaust bank 1).";
CM_ SG_ 2566733310 Aftrtrtmnt1SCRCtlystRgntTnk2Lvl "The SCR catalyst reagent tank 2 level percentage for aftertreatment system 1 (exhaust bank 1).";
CM_ BO_ 2566733054 "Aftertreatment 1 SCR Reagent Supply Information";
CM_ SG_ 2566733054 Aftrtrtmnt1SCRCtlystRgntTnkDrnVl "Commanded percentage of maximum Aftertreatment 1 SCR Catalyst Reagent Tank Drain Valve opening.";
CM_ SG_ 2566733054 Aftrtrtmnt1SCRCtlystRgntPmpStte "State of aftertreatment 1 SCR Catalyst Reagent dosing pump.";
CM_ SG_ 2566733054 Aftrtrtmnt1SCRCtlystRgntTnkFllVl "Commanded percentage of maximum Aftertreatment 1 SCR Catalyst Reagent Tank Fill Valve opening.";
CM_ SG_ 2566733054 Aftrtrtmnt1SCRCtlystRgntRtrnVlv "Command to the valve which determines whether the reagent is delivered to the injector or is routed back to the reagent";
CM_ SG_ 2566733054 Aftrtrtmnt1SCRCtlystRgntPmpDrvPr "The percent (command) sent to the motor to control the speed of the reagent pump.";
CM_ SG_ 2566733054 Aftrtrtmnt1SCRCtlystRgntPmpMtrSp "Rotational speed of the motor driving a pump for reagent used in an aftertreatment system.";
CM_ BO_ 2499624702 "Aftertreatment 1 SCR Exhaust Gas Temperature";
CM_ SG_ 2499624702 Aftrtrtmnt1SCRCtlystOtltGsTmpPrl "Used to identify the applicable J1939-73 FMI detected in the SCR catalyst outlet gas temperature sensor by the";
CM_ SG_ 2499624702 Aftrtrtmnt1SCRCtlystOtltGasTemp "Temperature of engine combustion byproducts leaving the SCR catalyst exhaust in exhaust bank 1.";
CM_ SG_ 2499624702 Aftrtrtmnt1SCRCtlystIntkGsTmpPrl "Used to identify the applicable J1939-73 FMI detected in the SCR catalyst intake gas temperature sensor by the";
CM_ SG_ 2499624702 Aftrtrtmnt1SCRCtlystIntkGasTemp "Temperature of engine combustion byproducts entering the SCR catalyst in exhaust bank 1.";
CM_ BO_ 2566733822 "Aftertreatment 1 SCR Exhaust Gas Pressures";
CM_ SG_ 2566733822 Aftrtrtmnt1SCRCtlystExhstGsDffPr "Used to identify the applicable J1939-73 FMI detected in the SCR catalyst differential pressure sensor by the";
CM_ SG_ 2566733822 Aftrtrtmnt1SCRCtlystExhstGs_0000 "Exhaust differential pressure measured between the intake and exhaust of a SCR catalyst in exhaust bank 1.";
CM_ BO_ 2566734078 "Aftertreatment 1 SCR Dosing System Requests 2";
CM_ SG_ 2566734078 Aftrtrtmnt1SCRCtlystTnk2HterCmd "This is the command for the Aftertreatment 1 SCR Catalyst Tank 2 Heater.";
CM_ SG_ 2566734078 Aftrtrtmnt1SCRCtlystTnkHaterCmd "Command for the Aftertreatment 1 SCR Catalyst Tank Heater.";
CM_ SG_ 2566734078 Aftrtrtmnt1SCRCtlystRgntLnHter4 "The SCR catalyst reagent line heater 4 request for aftertreatment system 1 (exhaust bank 1).";
CM_ SG_ 2566734078 Aftrtrtmnt1SCRCtlystRgntLnHter3 "The SCR catalyst reagent line heater 3 request for aftertreatment system 1 (exhaust bank 1).";
CM_ SG_ 2566734078 Aftrtrtmnt1SCRCtlystRgntLnHter2 "The SCR catalyst reagent line heater 2 request for aftertreatment system 1 (exhaust bank 1).";
CM_ SG_ 2566734078 Aftrtrtmnt1SCRCtlystRgntLnHter1 "The SCR catalyst reagent line heater 1 request for aftertreatment system 1 (exhaust bank 1).";
CM_ SG_ 2566734078 Aftrtrtmnt1SCRDserHeatingModeRq "Used if multiple heater modes are available in the Doser.";
CM_ SG_ 2566734078 Aftrtrtmnt1SCRDsrFltSpprssionRq "Used if external devices can warn of conditions that require suppression of potential faults in the doser due to";
CM_ BO_ 2364548350 "Aftertreatment 1 SCR Dosing System Requests 1";
CM_ SG_ 2364548350 Aftrtrtmnt1SCRRqdRgntQnttyFrIntg "Represents the command for the reducing agent quantity integrator in the dosing control unit";
CM_ SG_ 2364548350 Aftrtratment1SCRSystemRqedState "Requested state of SCR system for aftertreatment system 1 (exhaust bank 1).";
CM_ SG_ 2364548350 Aftrtrtmnt1SCRRqdDsngRgntQntity "Actual requested dosing quantity of catalyst reagent";
CM_ BO_ 2566734334 "Aftertreatment 1 SCR Dosing System Information 2";
CM_ SG_ 2566734334 Aftrtrtmnt1SCRCtlystRgntLnHtr4Pr "Used to identify the applicable J1939-73 FMI detected in the SCR catalyst reagent line heater 4, by the manufacturer's";
CM_ SG_ 2566734334 Aftrtrtmnt1SCRCtlystRgntLnHtr4St "The SCR catalyst reagent line heater 4 state for aftertreatment system 1 (exhaust bank 1).";
CM_ SG_ 2566734334 Aftrtrtmnt1SCRCtlystRgntLnHtr3Pr "Used to identify the applicable J1939-73 FMI detected in the SCR catalyst reagent line heater 3, by the manufacturer's";
CM_ SG_ 2566734334 Aftrtrtmnt1SCRCtlystRgntLnHtr3St "The SCR catalyst reagent line heater 3 state for aftertreatment system 1 (exhaust bank 1).";
CM_ SG_ 2566734334 Aftrtrtmnt1SCRCtlystRgntLnHtr2Pr "Used to identify the applicable J1939-73 FMI detected in the SCR catalyst reagent line heater 2, by the manufacturer's";
CM_ SG_ 2566734334 Aftrtrtmnt1SCRCtlystRgntLnHtr2St "The SCR catalyst reagent line heater 2 state for aftertreatment system 1 (exhaust bank 1).";
CM_ SG_ 2566734334 Aftrtrtmnt1SCRCtlystRgntLnHtr1Pr "Used to identify the applicable J1939-73 FMI detected in the SCR catalyst reagent line heater 1, by the manufacturer's";
CM_ SG_ 2566734334 Aftrtrtmnt1SCRCtlystRgntLnHtr1St "The SCR catalyst reagent line heater 1 state for aftertreatment system 1 (exhaust bank 1).";
CM_ SG_ 2566734334 Aftrtrtmnt1SCRFedbackCtrlStatus "The SCR feedback control status (open/closed loop) for aftertreatment system 1 (exhaust bank 1).";
CM_ SG_ 2566734334 Aftrtrtmnt1SCRDsngVlvExhstTmpRdc "Protection request for the dosing valve of the SCR-system to prevent overheating";
CM_ SG_ 2566734334 Aftrtrtmnt1SCRDosingReagentTemp "The SCR dosing reagent temperature (measured closest to dosing valve) for aftertreatment system 1 (exhaust bank 1).";
CM_ SG_ 2566734334 Aftrtrtmnt1SCRDsngArAssistValve "The position of the valve used to regulate the air supply of an air assist SCR dosing system for an engine.";
CM_ SG_ 2566734334 Aftrtrtmnt1SCRDsngArAssstAbsPrss "The SCR dosing system air assist absolute pressure for aftertreatment system 1 (exhaust bank 1).";
CM_ BO_ 2364548094 "Aftertreatment 1 SCR Dosing System Information 1";
CM_ SG_ 2364548094 Aftrtrtmnt1SCRDsngRgentAbsPress "The SCR dosing reagent absolute pressure (measured closest to dosing valve) for aftertreatment system 1 (exhaust bank";
CM_ SG_ 2364548094 Aftrtrtmnt1SCRActlRgntQnttyOfInt "The SCR requested reagent integrator total quantity for aftertreatment system 1 (exhaust bank 1).";
CM_ SG_ 2364548094 Aftertreatment1SCRSystemState "Actual state of SCR system";
CM_ SG_ 2364548094 Aftrtrtmnt1SCRActlDsngRgntQntty "Actual reducing agent quantity of SCR-system";
CM_ BO_ 2364548606 "Aftertreatment 1 SCR Ammonia Information";
CM_ SG_ 2364548606 Aftrtrtmnt1OtltNH3GsSnsrHtrCtrl "Indicates the heater status in the warm-up process.";
CM_ SG_ 2364548606 Aftrtrtmnt1OtltNH3GsSnsrHtrPrlmn "Used to identify the applicable J1939-73 FMI detected in the heater of the outlet NH3 exhaust gas sensor by the";
CM_ SG_ 2364548606 Aftrtrtmnt1OtltNH3GsSnsorAtTemp "Indicates that the heater element of the aftertreatment outlet NH3 gas sensor is within the manufacturer's specified range";
CM_ SG_ 2364548606 Aftrtrtmnt1OtltNH3GsSnsrPwrInRng "Indicates that the power supplied to the aftertreatment outlet NH3 gas sensor is within the manufacturer's specification in";
CM_ SG_ 2364548606 Aftrtrtmnt1OtltNH3ReadingStable "Indicates that the NH3 reading of the aftertreatment outlet NH3 sensor is stable as determined by the manufacturer's";
CM_ SG_ 2364548606 Aftrtrtmnt1OtltNH3SnsrPrlmnryFMI "Used to identify the applicable J1939-73 FMI detected in the aftertreatment outlet NH3 sensor by the manufacturer's";
CM_ SG_ 2364548606 Aftertreatment1OutletNH3 "The amount of NH3 in the exhaust exiting the aftertreatment system measured by a NH3 sensor at the aftertreatment";
CM_ BO_ 2566726398 "Aftertreatment 1 Gas Oxidation Catalyst";
CM_ SG_ 2566726398 Aftrtrtmnt1GsOxdtnCtlystDffPrssP "Used to identify the applicable J1939-73 FMI detected in the gas oxidation catalyst differential pressure sensor by the";
CM_ SG_ 2566726398 Aftrtrtmnt1GsOxdtnCtlystOtltGsTm "Used to identify the applicable J1939-73 FMI detected in the gas oxidation catalyst outlet gas temperature sensor by the";
CM_ SG_ 2566726398 Aftrtrtmnt1GsOxdtnCtlystIntkGsTm "Used to identify the applicable J1939-73 FMI detected in the gas oxidation catalyst intake gas temperature sensor by the";
CM_ SG_ 2566726398 Aftrtrtmnt1GsOxdtnCtlystDffPrss "Exhaust differential pressure measured between the intake and exhaust of the gas oxidation catalyst in exhaust bank 1.";
CM_ SG_ 2566726398 Aftrtrtmnt1GsOxdtnCtlystOtl_0000 "Temperature of engine combustion byproducts leaving the gas oxidation catalyst in exhaust bank 1.";
CM_ SG_ 2566726398 Aftrtrtmnt1GsOxdtnCtlystInt_0000 "Temperature of engine combustion byproducts entering the gas oxidation catalyst in exhaust bank 1.";
CM_ BO_ 2566742270 "HB1C provides the system specific individual B1 failure counters";
CM_ SG_ 2566742270 FailureSpecificB1Counter "The Failure Specific B1 Counter provides an individual B1 counter";
CM_ SG_ 2566742270 FailureModeIdentifier1 "The FMI defines the type of failure detected in the subsystem identified by an SPN.";
CM_ SG_ 2566742270 SPN1High "SPN #1 (Conversion Version 4)";
CM_ SG_ 2566742270 SPN1 "SPN #1 (Conversion Version 4)";
CM_ BO_ 2566742526 "Cumulative Continuous MI-System";
CM_ SG_ 2566742526 SysGreatestB1Counter "System Greatest B1 Counter";
CM_ SG_ 2566742526 SysCumulativeContinuousMITime "System Cumulative Continuous MI Time";
CM_ BO_ 2566742782 "Harmonized Global Regulation Description";
CM_ SG_ 2566742782 RegulationDescription "Global Technical Regulation Description";
CM_ BO_ 2566743038 "Harmonized Roadworthiness";
CM_ SG_ 2566743038 SysIncompleteMonitorCount "System Incomplete Monitor Count";
CM_ SG_ 2566743038 SysMalIndActivationMode "System Malfunction Indicator Status";
CM_ SG_ 2566743038 SysMalIndDisplayStrategy "System Malfunction Indicator Display";
CM_ SG_ 2566743038 SysContinuousMalfunctionInd "System Continuous Malfunction Indicator";
CM_ SG_ 2566743038 SysNonRoadworthyCompCount "System Non-Roadworthy Component Count";
CM_ BO_ 2566743294 "Harmonized Roadworthiness ";
CM_ SG_ 2566743294 VehicleCurrentMIAccumTime "Vehicle Current MI Accumulated Time";
CM_ SG_ 2566743294 VehicleIncompleteMonitorCount "Vehicle Incomplete Monitor Count";
CM_ SG_ 2566743294 VehicleMalfunctionIndActMode "Vehicle Malfunction Indicator Status ";
CM_ SG_ 2566743294 VehicleMalfunctionIndStrategy "Vehicle Malfunction Indicator Display Strategy ";
CM_ SG_ 2566743294 VehicleContinuousMalfunctionInd "Vehicle Continuous Malfunction Indicator";
CM_ SG_ 2566743294 VehicleNonRoadworthyCompCount "Vehicle Non-Roadworthy Component Count";
CM_ BO_ 2560687870 "The status of engine operating in the NTE control areas for given pollutants, such as NOx and PM";
CM_ SG_ 2560687870 PMNTEDeficiencyAreaStatus "Status of engine operation within the PM NTE Deficiency Area";
CM_ SG_ 2560687870 MnfcPMNTECarveOutAreaStatus "Status of engine operation within the manufacturer specific PM NTE carve out area";
CM_ SG_ 2560687870 PMNTEControlAreaStatus "Status of engine operation within the bounded region of the engine's torque and speed map.";
CM_ SG_ 2560687870 NOxNTEDeficiencyAreaStatus "Status of engine operation within the NOx NTE Deficiency Area";
CM_ SG_ 2560687870 MnfcNOxNTECarveOutAreaStatus "Status of engine operation within the bounded region of the engine's torque and speed map.";
CM_ SG_ 2560687870 NOxNTEControlAreaStatus "Status of engine operation within the bounded region of the engine's torque and speed map.";
CM_ BO_ 2292317950 "The total engine run time while each of the Emission Increasing Auxiliary Emission Control Devices is active";
CM_ SG_ 2292317950 AECDEngineHours1Timer2 "The total engine running hours recorded in the second timer for the EI-AECD";
CM_ SG_ 2292317950 AECDEngineHours1Timer1 "The total engine running hours recorded in the first timer for the EI-AECD";
CM_ SG_ 2292317950 AECDNumber1 "The manufacturer assigned number for the specific EI-AECD";
CM_ BO_ 2566809342 "Battery Main Switch Information";
CM_ SG_ 2566809342 BatteryMainSwitchHoldState "Parameter indicating whether the battery main switch is held due to an external request or not.";
CM_ BO_ 2365446910 "Basic Joystick Message 3";
CM_ SG_ 2365446910 Joystick3XAxisDetentPosStatus "Reports when the current joystick position is in the detent position for that axis of travel.";
CM_ SG_ 2365446910 Joystick3Button9PressedStatus "Reports when the joystick button has been pressed.";
CM_ SG_ 2365446910 Joystick3Button10PressedStatus "Reports when the joystick button has been pressed.";
CM_ SG_ 2365446910 Joystick3Button11PressedStatus "Reports when the joystick button has been pressed.";
CM_ SG_ 2365446910 Joystick3Button12PressedStatus "Reports when the joystick button has been pressed.";
CM_ SG_ 2365446910 Joystick3YAxisDetentPosStatus "Reports when the current joystick position is in the detent position for that axis of travel.";
CM_ SG_ 2365446910 Joystick3YAxisPos "The position of the joystick in the relative motion of travel from the neutral position.";
CM_ SG_ 2365446910 Jystck3YAxsLvrFrwrdPstvPsStatus "Reports when the current joystick position is on the positive travel side (forward, right, clockwise, up) relative to the";
CM_ SG_ 2365446910 Jystck3YAxsLvrBckNgtvePosStatus "Reports when the current joystick position is on the negative travel side (back, left, counterclockwise, down) relative to the";
CM_ SG_ 2365446910 Joystick3YAxisNeutralPosStatus "Reports when the current joystick position is in the neutral position for that axis of travel.";
CM_ SG_ 2365446910 Joystick3XAxisPos "The position of the joystick in the relative motion of travel from the neutral position.";
CM_ SG_ 2365446910 Jystck3XAxsLvrRghtPstvPosStatus "Reports when the current joystick position is on the positive travel side (forward, right, clockwise, up) relative to the";
CM_ SG_ 2365446910 Jystck3XAxsLvrLftNgtvePosStatus "Reports when the current joystick position is on the negative travel side (back, left, counterclockwise, down) relative to the";
CM_ SG_ 2365446910 Joystick3XAxisNeutralPosStatus "Reports when the current joystick position is in the neutral position for that axis of travel.";
CM_ SG_ 2365446910 Joystick3Button5PressedStatus "Reports when the joystick button has been pressed.";
CM_ SG_ 2365446910 Joystick3Button6PressedStatus "Reports when the joystick button has been pressed.";
CM_ SG_ 2365446910 Joystick3Button7PressedStatus "Reports when the joystick button has been pressed.";
CM_ SG_ 2365446910 Joystick3Button8PressedStatus "Reports when the joystick button has been pressed.";
CM_ SG_ 2365446910 Joystick3Button1PressedStatus "Reports when the joystick button has been pressed.";
CM_ SG_ 2365446910 Joystick3Button2PressedStatus "Reports when the joystick button has been pressed.";
CM_ SG_ 2365446910 Joystick3Button3PressedStatus "Reports when the joystick button has been pressed.";
CM_ SG_ 2365446910 Joystick3Button4PressedStatus "Reports when the joystick button has been pressed.";
CM_ BO_ 2365446398 "Basic Joystick Message 2";
CM_ SG_ 2365446398 Joystick2XAxisDetentPosStatus "Reports when the current joystick position is in the detent position for that axis of travel.";
CM_ SG_ 2365446398 Joystick2YAxisDetentPosStatus "Reports when the current joystick position is in the detent position for that axis of travel.";
CM_ SG_ 2365446398 Joystick2YAxisPos "The position of the joystick in the relative motion of travel from the neutral position.";
CM_ SG_ 2365446398 Jystck2YAxsLvrFrwrdPstvPsStatus "Reports when the current joystick position is on the positive travel side (forward, right, clockwise, up) relative to the";
CM_ SG_ 2365446398 Jystck2YAxsLvrBckNgtvePosStatus "Reports when the current joystick position is on the negative travel side (back, left, counterclockwise, down) relative to the";
CM_ SG_ 2365446398 Joystick2YAxisNeutralPosStatus "Reports when the current joystick position is in the neutral position for that axis of travel.";
CM_ SG_ 2365446398 Joystick2XAxisPos "The position of the joystick in the relative motion of travel from the neutral position.";
CM_ SG_ 2365446398 Jystck2XAxsLvrRghtPstvPosStatus "Reports when the current joystick position is on the positive travel side (forward, right, clockwise, up) relative to the";
CM_ SG_ 2365446398 Jystck2XAxsLvrLftNgtvePosStatus "Reports when the current joystick position is on the negative travel side (back, left, counterclockwise, down) relative to the";
CM_ SG_ 2365446398 Joystick2XAxisNeutralPosStatus "Reports when the current joystick position is in the neutral position for that axis of travel.";
CM_ SG_ 2365446398 Joystick2Button9PressedStatus "Reports when the joystick button has been pressed.";
CM_ SG_ 2365446398 Joystick2Button10PressedStatus "Reports when the joystick button has been pressed.";
CM_ SG_ 2365446398 Joystick2Button11PressedStatus "Reports when the joystick button has been pressed.";
CM_ SG_ 2365446398 Joystick2Button12PressedStatus "Reports when the joystick button has been pressed.";
CM_ SG_ 2365446398 Joystick2Button5PressedStatus "Reports when the joystick button has been pressed.";
CM_ SG_ 2365446398 Joystick2Button6PressedStatus "Reports when the joystick button has been pressed.";
CM_ SG_ 2365446398 Joystick2Button7PressedStatus "Reports when the joystick button has been pressed.";
CM_ SG_ 2365446398 Joystick2Button8PressedStatus "Reports when the joystick button has been pressed.";
CM_ SG_ 2365446398 Joystick2Button1PressedStatus "Reports when the joystick button has been pressed.";
CM_ SG_ 2365446398 Joystick2Button2PressedStatus "Reports when the joystick button has been pressed.";
CM_ SG_ 2365446398 Joystick2Button3PressedStatus "Reports when the joystick button has been pressed.";
CM_ SG_ 2365446398 Joystick2Button4PressedStatus "Reports when the joystick button has been pressed.";
CM_ BO_ 2365445886 "Basic Joystick Message 1";
CM_ SG_ 2365445886 Joystick1XAxisDetentPosStatus "Reports when the current joystick position is in the detent position for that axis of travel.";
CM_ SG_ 2365445886 Joystick1YAxisDetentPosStatus "Reports when the current joystick position is in the detent position for that axis of travel.";
CM_ SG_ 2365445886 Joystick1YAxisPos "The position of the joystick in the relative motion of travel from the neutral position.";
CM_ SG_ 2365445886 Jystck1YAxsLvrFrwrdPstvPsStatus "Reports when the current joystick position is on the positive travel side (forward, right, clockwise, up) relative to the";
CM_ SG_ 2365445886 Jystck1YAxsLvrBckNgtvePosStatus "Reports when the current joystick position is on the negative travel side (back, left, counterclockwise, down) relative to the";
CM_ SG_ 2365445886 Joystick1YAxisNeutralPosStatus "Reports when the current joystick position is in the neutral position for that axis of travel.";
CM_ SG_ 2365445886 Joystick1XAxisPos "The position of the joystick in the relative motion of travel from the neutral position.";
CM_ SG_ 2365445886 Joystick1Button9PressedStatus "Reports when the joystick button has been pressed.";
CM_ SG_ 2365445886 Joystick1Button10PressedStatus "Reports when the joystick button has been pressed.";
CM_ SG_ 2365445886 Joystick1Button11PressedStatus "Reports when the joystick button has been pressed.";
CM_ SG_ 2365445886 Joystick1Button12PressedStatus "Reports when the joystick button has been pressed.";
CM_ SG_ 2365445886 Joystick1Button5PressedStatus "Reports when the joystick button has been pressed.";
CM_ SG_ 2365445886 Joystick1Button6PressedStatus "Reports when the joystick button has been pressed.";
CM_ SG_ 2365445886 Joystick1Button7PressedStatus "Reports when the joystick button has been pressed.";
CM_ SG_ 2365445886 Joystick1Button8PressedStatus "Reports when the joystick button has been pressed.";
CM_ SG_ 2365445886 Joystick1Button1PressedStatus "Reports when the joystick button has been pressed.";
CM_ SG_ 2365445886 Joystick1Button2PressedStatus "Reports when the joystick button has been pressed.";
CM_ SG_ 2365445886 Joystick1Button3PressedStatus "Reports when the joystick button has been pressed.";
CM_ SG_ 2365445886 Joystick1Button4PressedStatus "Reports when the joystick button has been pressed.";
CM_ SG_ 2365445886 Jystck1XAxsLvrRghtPstvPosStatus "Reports when the current joystick position is on the positive travel side (forward, right, clockwise, up) relative to the";
CM_ SG_ 2365445886 Jystck1XAxsLvrLftNgtvePosStatus "Reports when the current joystick position is on the negative travel side (back, left, counterclockwise, down) relative to the";
CM_ SG_ 2365445886 Joystick1XAxisNeutralPosStatus "Reports when the current joystick position is in the neutral position for that axis of travel.";
CM_ BO_ 2566847230 "Brakes";
CM_ SG_ 2566847230 ParkingBrakeRedWarningSignal "This parameter commands the Parking Brake red optical warning signal.";
CM_ SG_ 2566847230 ParkBrakeReleaseInhibitStatus "This parameter provides reports on the status of the Park Brake Release Inhibit function.";
CM_ SG_ 2566847230 ParkingBrakeActuator "Signal which indicates the current state of the actuator(s) that control the parking brake (see also SPN 70).";
CM_ SG_ 2566847230 BrakeSecondPress "Gage pressure of air in the secondary, or service side, of the air brake system.";
CM_ SG_ 2566847230 BrakePrimaryPress "Gage pressure of air in the primary, or supply side, of the air brake system.";
CM_ SG_ 2566847230 BrakeAppPress "Gage pressure of compressed air or fluid in vehicle braking system measured at the brake chamber when brake shoe (or";
CM_ BO_ 2566848254 "Auxiliary Water Pump Pressure";
CM_ SG_ 2566848254 AuxPumpPress "Gage pressure of auxiliary water pump driven as a PTO device.";
CM_ BO_ 2566725886 "Aftertreatment 1 Diesel Oxidation Catalyst";
CM_ SG_ 2566725886 Aftrtrtmnt1DslOxdtnCtlystDf_0000 "Used to identify the applicable J1939-73 FMI detected in the diesel oxidation catalyst differential pressure sensor by the";
CM_ SG_ 2566725886 Aftrtrtmnt1DslOxdtnCtlystOtltGsT "Used to identify the applicable J1939-73 FMI detected in the diesel oxidation catalyst outlet gas temperature sensor by";
CM_ SG_ 2566725886 Aftrtrtmnt1DslOxdtnCtlystIntkGsT "Used to identify the applicable J1939-73 FMI detected in the diesel oxidation catalyst intake gas temperature sensor by";
CM_ SG_ 2566725886 Aftrtrtmnt1DslOxdtnCtlystDffPrss "Exhaust differential pressure measured between the intake and exhaust of a diesel oxidation catalyst in exhaust bank 1.";
CM_ SG_ 2566725886 Aftrtrtmnt1DslOxdtnCtlystOt_0000 "Temperature of engine combustion byproducts leaving the diesel oxidation catalyst exhaust in exhaust bank 1.";
CM_ SG_ 2566725886 Aftrtrtmnt1DslOxdtnCtlystIn_0000 "Temperature of engine combustion byproducts entering the diesel oxidation catalyst in exhaust bank 1.";
CM_ BO_ 2560884478 "This message shall provide the applicable lamp for each individual DTC";
CM_ SG_ 2560884478 DTCWarnLampSupportStatus "Lamp support status";
CM_ SG_ 2560884478 DTCWarnLampSupportFlash "Lamp support status";
CM_ SG_ 2560884478 DTCStopLampSupportStatus "Lamp support status";
CM_ SG_ 2560884478 DTCStopLampSupportFlash "Lamp support status";
CM_ SG_ 2560884478 DTCProtectLampSupportStatus "Lamp support status";
CM_ SG_ 2560884478 DTCProtectLampSupportFlash "Lamp support status";
CM_ SG_ 2560884478 DTCMilSupportStatus "Lamp support status";
CM_ SG_ 2560884478 DTCMilSupportFlash "Lamp support status";
CM_ SG_ 2560884478 DTC1 "Diagnostic Trouble Code";
CM_ BO_ 2633844734 "Transmission Mode Labels";
CM_ BO_ 2560360190 "Proprietary Method Identification";
CM_ SG_ 2560360190 DataDictionaryMethod "A manufacturer defined code to define the proprietary communications method.";
CM_ SG_ 2560360190 DataDictionaryManufacturerCode "The J1939 Manufacturer Code (see J1939 Table B10) associated with the manufacturer who defined the proprietary";
CM_ BO_ 2566736126 "Engine Exhaust Bank 2 O2 Fuel Trim";
CM_ SG_ 2566736126 ShorttermFuelTrimBank2 "This parameter is the short-term percent change in fueling based on the O2 sensor feedback for cylinder bank 2, based";
CM_ SG_ 2566736126 LongtermFuelTrimBank2 "This parameter is the long-term percent change in fueling based on the O2 sensor feedback for cylinder bank 2, based on";
CM_ SG_ 2566736126 EngExhstGsOxygnSnsrClsdLpOprtnBn "This parameter indicates the status of the bank 2 O2 sensor feedback closed loop operation";
CM_ BO_ 2566736382 "Engine Exhaust Bank 1 O2 Fuel Trim";
CM_ SG_ 2566736382 ShorttermFuelTrimBank1 "This parameter is the short-term percent change in fueling based on the O2 sensor feedback for cylinder bank 1, based";
CM_ SG_ 2566736382 LongtermFuelTrimBank1 "This parameter is the long-term percent change in fueling based on the O2 sensor feedback for cylinder bank 1, based on";
CM_ SG_ 2566736382 EngExhstGsOxygnSnsrClsdLpOp_0000 "This parameter indicates the status of the bank 1 O2 sensor feedback closed loop operation";
CM_ BO_ 2565874174 "Engine Speed Sensor Information";
CM_ SG_ 2565874174 EngSpdSnsor1TimingPatternStatus "This is the timing pattern status of the engine speed sensor signal for sensor 1.";
CM_ SG_ 2565874174 EngSpdSnsor2TimingPatternStatus "This is the timing pattern status of the engine speed sensor signal for sensor 2.";
CM_ SG_ 2565874174 EngSpdSnsor3TimingPatternStatus "This is the timing pattern status of the engine speed sensor signal for sensor 3.";
CM_ SG_ 2565874174 EngSpeed3 "The engine speed as measured by speed sensor 3.";
CM_ SG_ 2565874174 EngSpeed2 "The engine speed as measured by speed sensor 2";
CM_ SG_ 2565874174 EngSpeed1 "The engine speed as measured by speed sensor 1.";
CM_ BO_ 2432520958 "Engine Coolant Control Valve Command";
CM_ SG_ 2432520958 DsrdEngCoolantThermostatOpening "Indicates the desired position of the engine coolant control valve.";
CM_ SG_ 2432520958 DesiredEngCoolantPumpOutletTemp "Desired engine coolant temperature of the engine to an electronic thermostat.";
CM_ SG_ 2432520958 EngCoolantThermostatMode "Specifies if the engine coolant thermostat valve will operate in temperature control mode or position control mode.";
CM_ BO_ 2560425726 "Auxiliary Input/Output Status 7";
CM_ SG_ 2560425726 AuxI_OChannel19 "Identifies the current value of auxiliary input/output channels that are configured uniquely per application.";
CM_ SG_ 2560425726 AuxI_OChannel20 "Identifies the current value of auxiliary input/output channels that are configured uniquely per application.";
CM_ SG_ 2560425726 AuxI_OChannel21 "Identifies the current value of auxiliary input/output channels that are configured uniquely per application.";
CM_ SG_ 2560425726 AuxI_OChannel22 "Identifies the current value of auxiliary input/output channels that are configured uniquely per application.";
CM_ SG_ 2560425726 AuxI_OChannel15 "Identifies the current value of auxiliary input/output channels that are configured uniquely per application.";
CM_ SG_ 2560425726 AuxI_OChannel16 "Identifies the current value of auxiliary input/output channels that are configured uniquely per application.";
CM_ SG_ 2560425726 AuxI_OChannel17 "Identifies the current value of auxiliary input/output channels that are configured uniquely per application.";
CM_ SG_ 2560425726 AuxI_OChannel18 "Identifies the current value of auxiliary input/output channels that are configured uniquely per application.";
CM_ BO_ 2560491262 "Auxiliary Input/Output Status 6";
CM_ SG_ 2560491262 AuxI_OChannel11 "Identifies the current value of auxiliary input/output channels that are configured uniquely per application.";
CM_ SG_ 2560491262 AuxI_OChannel12 "Identifies the current value of auxiliary input/output channels that are configured uniquely per application.";
CM_ SG_ 2560491262 AuxI_OChannel13 "Identifies the current value of auxiliary input/output channels that are configured uniquely per application.";
CM_ SG_ 2560491262 AuxI_OChannel14 "Identifies the current value of auxiliary input/output channels that are configured uniquely per application.";
CM_ SG_ 2560491262 AuxI_OChannel7 "Identifies the current value of auxiliary input/output channels that are configured uniquely per application.";
CM_ SG_ 2560491262 AuxI_OChannel8 "Identifies the current value of auxiliary input/output channels that are configured uniquely per application.";
CM_ SG_ 2560491262 AuxI_OChannel9 "Identifies the current value of auxiliary input/output channels that are configured uniquely per application.";
CM_ SG_ 2560491262 AuxI_OChannel10 "Identifies the current value of auxiliary input/output channels that are configured uniquely per application.";
CM_ BO_ 2349399806 "Auxiliary Input/Output Status 5";
CM_ SG_ 2349399806 AuxI_OChannel3 "Identifies the current value of auxiliary input/output channels that are configured uniquely per application.";
CM_ SG_ 2349399806 AuxI_OChannel4 "Identifies the current value of auxiliary input/output channels that are configured uniquely per application.";
CM_ SG_ 2349399806 AuxI_OChannel5 "Identifies the current value of auxiliary input/output channels that are configured uniquely per application.";
CM_ SG_ 2349399806 AuxI_OChannel6 "Identifies the current value of auxiliary input/output channels that are configured uniquely per application.";
CM_ BO_ 2566758398 "Aftertreatment 1 Air Control 1";
CM_ SG_ 2566758398 Aftrtreatment1AirEnableActuator "Indicates whether aftertreatment 1 air enable actuator is on or off";
CM_ SG_ 2566758398 Aftertreatment1PurgeAirActuator "Indicates whether aftertreatment 1 purge air actuator is on or off";
CM_ SG_ 2566758398 Aftrtrtmnt1AtmzationAirActuator "Indicates whether aftertreatment 1 atomization air actuator is on or off";
CM_ SG_ 2566758398 Aftertreatment1AirSystemRelay "Indicates whether aftertreatment 1 air system relay is on or off";
CM_ SG_ 2566758398 Aftrtrtment1AirPressActuatorPos "Position of the aftertreatment 1 air pressure actuator as measured by a position feedback sensor.";
CM_ SG_ 2566758398 Aftertreatment1AirPressCtrl "Position that the controller is commanding the aftertreatment 1 air pressure control to maintain.";
CM_ SG_ 2566758398 Aftertreatment1PurgeAirPress "Pressure of the purge air supply for aftertreatment 1";
CM_ SG_ 2566758398 Aftertreatment1SupplyAirPress "Pressure of the supply air for aftertreatment 1.";
CM_ BO_ 2566745598 "Aftertreatment 1 Air Control 2";
CM_ SG_ 2566745598 Aftertreatment1SecondAirPress "Pressure of the secondary air for aftertreatment 1.";
CM_ SG_ 2566745598 Aftrtreatment1SecondAirMassFlow "Indicates the secondary air mass flow for aftertreatment 1.";
CM_ SG_ 2566745598 Aftertreatment1SecondAirTemp "Indicates the secondary air temperature for aftertreatment 1.";
CM_ SG_ 2566745598 Aftrtratment1SecondAirDiffPress "Indicates the secondary air differential pressure for aftertreatment 1.";
CM_ BO_ 2566758910 "Aftertreatment 1 Fuel Control 1";
CM_ SG_ 2566758910 Aftrtrtmnt1FlInjctor1HeaterCtrl "Heating level that the controller is commanding the aftertreatment 1 fuel injector 1 heater control to maintain.";
CM_ SG_ 2566758910 Aftertreatment1FuelPress1Ctrl "Position that the controller is commanding the aftertreatment 1 fuel pressure control to maintain.";
CM_ SG_ 2566758910 Aftrtratment1FuelEnableActuator "Indicates whether aftertreatment 1 fuel enable actuator is on or off";
CM_ SG_ 2566758910 Aftrtratment1RegenerationStatus "Indicates whether regeneration is active or inactive in aftertreatment 1.";
CM_ SG_ 2566758910 Aftertreatment1Ignt "Indicates whether aftertreatment 1 ignition circuit is energized by the ECM.";
CM_ SG_ 2566758910 Aftrtreatment1FuelDrainActuator "Indicates whether aftertreatment 1 fuel drain actuator is on or off";
CM_ SG_ 2566758910 Aftertreatment1FuelRate "Rate of fuel being delivered to aftertreatment 1 for regeneration";
CM_ SG_ 2566758910 Aftertreatment1FuelPress1 "First fuel pressure measurement for the aftertreatment 1 system";
CM_ BO_ 2566743550 "Aftertreatment 1 Fuel Control 2";
CM_ SG_ 2566743550 Aftrtrtmnt1HydrcrbnDsrIntkFlTmp "Measured temperature of the intake fuel to the hydrocarbon dosing device";
CM_ SG_ 2566743550 Aftrtrtmnt1FlPress2ActuatorCtrl "Indicates how the device is controlling the aftertreatment 1 fuel pressure 2 regulating control valve.";
CM_ SG_ 2566743550 Aftrtrtmnt1FlFlwDvrterValveCtrl "Indicates how the device is controlling the aftertreatment 1 fuel flow diverter valve.";
CM_ SG_ 2566743550 Aftrtreatment1FuelPumpRelayCtrl "Indicates how the device is controlling the aftertreatment 1 fuel pump relay.";
CM_ SG_ 2566743550 Aftertreatment1FuelPress2 "Second fuel pressure measurement for the aftertreatment 1 system";
CM_ BO_ 2566753534 "Aftertreatment 1 Gas Parameters";
CM_ SG_ 2566753534 DslPrticulateFilterOutletPress1 "This parameter indicates the diesel particulate filter outlet gage pressure 1 (bank 1).";
CM_ SG_ 2566753534 DslPrticulateFilterIntakePress1 "This parameter indicates the diesel particulate filter intake gage pressure 1 (bank 1).";
CM_ BO_ 2566756606 "Aftertreatment 1 Historical Information";
CM_ SG_ 2566756606 Aftrtrtmnt1TtlNmbrOfActvRgnrtnMn "Total number of aftertreatment device 1 active regeneration manual requests by the operator over the lifetime of the";
CM_ SG_ 2566756606 Aftrtrtmnt1TtlNmbrOfActvRgnrtnIn "Total number of aftertreatment device 1 active regeneration inhibit requests by the operator over the lifetime of the device.";
CM_ SG_ 2566756606 Aftrtrtmnt1AvrgTmBtwnActvRgnrtns "Indicates the average time since last reset between active regenerations, that have not been forced to occur by manual";
CM_ SG_ 2566756606 Aftrtrtmnt1TtlNmbrOfPssvRgnrtns "Total number of passive regenerations by aftertreatment device 1 over the lifetime of the device.";
CM_ SG_ 2566756606 Aftrtrtmnt1TtlPssvRgnrationTime "Total amount of time that aftertreatment device 1 has been in passive regeneration over the lifetime of the device.";
CM_ SG_ 2566756606 Aftrtrtmnt1TtlNmbrOfActvRgnrtns "Total number of active regenerations by aftertreatment device 1 over the lifetime of the device.";
CM_ SG_ 2566756606 Aftrtreatment1TotalDisabledTime "Total amount of time that aftertreatment 1 regeneration has been manually disabled.";
CM_ SG_ 2566756606 Aftrtrtmnt1TtalRegenerationTime "Total amount of time that aftertreatment device 1 has been regenerating over the lifetime of the device.";
CM_ SG_ 2566756606 Aftertreatment1TotalFuelUsed "Total amount of fuel used by aftertreatment device 1 over the lifetime of the device.";
CM_ BO_ 2565869310 "Aftertreatment 1 Intake Gas 1";
CM_ SG_ 2565869310 Aftrtrtmnt1IntkOxygnSnsrPrlmnryF "Used to identify the applicable J1939-73 FMI detected in the aftertreatment intake oxygen sensor by the manufacturer's";
CM_ SG_ 2565869310 Aftrtrtmnt1IntkGsSnsrPwerStatus "Indicates that the power supplied to the aftertreatment intake gas sensor, either NOx or O2, is within the manufacturer's";
CM_ SG_ 2565869310 Aftrtrtmnt1IntkGsSnsrHtrPrlmnryF "Used to identify the applicable J1939-73 FMI detected in the heater of the intake exhaust gas sensor, either NOx or O2,";
CM_ SG_ 2565869310 Aftrtrtmnt1IntkNOxSnsrPrlmnryFMI "Used to identify the applicable J1939-73 FMI detected in the aftertreatment intake NOx sensor by the manufacturer's";
CM_ SG_ 2565869310 Aftrtrtmnt1IntkGsSnsrHeaterCtrl "Indicates the heater status in the warm-up process.";
CM_ SG_ 2565869310 Aftrtrtmnt1IntkWdRngO2RdngStble "Indicates that the %O2 reading of the aftertreatment intake gas sensor, either NOx or O2, is stable as determined by the";
CM_ SG_ 2565869310 Aftrtrtmnt1IntkNOxReadingStable "Indicates that the NOx reading of the aftertreatment intake NOx sensor is stable as determined by the manufacturer's";
CM_ SG_ 2565869310 Aftrtrtmnt1IntkeGasSensorAtTemp "Indicates that the heater element of the aftertreatment intake gas sensor, either NOx or O2, is within the manufacturer's";
CM_ SG_ 2565869310 Aftertreatment1IntakeO2 "The actual oxidation factor (%O2) of the gas within the exhaust stream.";
CM_ SG_ 2565869310 Aftertreatment1IntakeNOx "The amount of combined NO and NO2 in the exhaust entering the aftertreatment system measured by a NOx sensor at";
CM_ BO_ 2566763774 "Aftertreatment 1 Intake Gas 2";
CM_ SG_ 2566763774 Aftrtrtmnt1DslPrtcltFltrIntkGsTm "Used to identify the applicable J1939-73 FMI detected in the diesel particulate filter intake gas temperature sensor by the";
CM_ SG_ 2566763774 Aftrtrtmnt1ExhstGsTmp1PrlmnryFMI "Used to identify the applicable J1939-73 FMI detected in the exhaust gas temperature 1 sensor by the manufacturer's";
CM_ SG_ 2566763774 Aftertreatment1ExhaustGasTemp1 "The reading from the exhaust gas temperature sensor located farthest upstream in the aftertreatment system in exhaust bank 1.";
CM_ SG_ 2566763774 Aftrtrtmnt1DslPrtcltFltrInt_0000 "Temperature of engine combustion byproducts entering the diesel particulate filter in exhaust bank 1.";
CM_ BO_ 2631728894 "Anti-theft Status";
CM_ SG_ 2631728894 AntitheftRandomNumber "A seven byte random numeric code provided by the component in response to an anti-theft request.";
CM_ SG_ 2631728894 AntitheftComponentStatusStates "Indicates whether or not the component can be started.";
CM_ SG_ 2631728894 AntthftEncryptnSdPrsntIndicator "Indicates the presence of the encryption seed random number.";
CM_ SG_ 2631728894 AntitheftModifyPwdStates "This parameter is used to indicate whether a password request was successfully performed, or if the request could not be";
CM_ SG_ 2631728894 AntitheftPwdValidIndicator "Indicates the presence of a validated password.";
CM_ BO_ 2631794430 "Anti-theft Request";
CM_ SG_ 2631794430 AntitheftPasswordRepresentation "This parameter is the seven byte numeric code (i.";
CM_ SG_ 2631794430 AntitheftCmdStates "This parameter is used to identify the specific requests being sent to the component.";
CM_ SG_ 2631794430 AntitheftDesiredExitModeStates "This parameter is used to specify the desired triggers that are to be used by the component in deciding when to transition";
CM_ SG_ 2631794430 AntthftEncryptonIndicatorStates "This parameter is used to indicate if a random number seed is being requested, or if an encrypted password is being";
CM_ BO_ 2633934846 "Alternator Temperature";
CM_ SG_ 2633934846 EngAltWinding3Temp "Temperature of the windings inside the alternator.";
CM_ SG_ 2633934846 EngAltWinding2Temp "Temperature of the windings inside the alternator.";
CM_ SG_ 2633934846 EngAltWinding1Temp "Temperature of the windings inside the alternator.";
CM_ SG_ 2633934846 EngAltBearing2Temp "Temperature of the bearing inside the alternator.";
CM_ SG_ 2633934846 EngAltBearing1Temp "Temperature of the bearing inside the alternator.";
CM_ BO_ 2362572542 "Air Suspension Control 6";
CM_ SG_ 2362572542 LevelPresetRearAxleRight "Set value for nominal level 'preset level' at the right side of the rear axle.";
CM_ SG_ 2362572542 LevelPresetRearAxleLeft "Set value for nominal level 'preset level' at the left side of the rear axle.";
CM_ SG_ 2362572542 LevelPresetFrontAxleRight "Set value for nominal level 'preset level' at the right side of the front axle.";
CM_ SG_ 2362572542 LevelPresetFrontAxleLeft "Set value for nominal level 'preset level' at the left side of the front axle.";
CM_ BO_ 2365478910 "Air Suspension Control 5";
CM_ SG_ 2365478910 ElctrncShckAbsrbrCtrlMdLft_TgAxl "Signal which indicates the current mode of operation of the electronic shock absorber control at the lift/tag axle.";
CM_ SG_ 2365478910 ElctrncShckAbsrbrCtrlMdRearAxle "Signal which indicates the current mode of operation of the electronic shock absorber control at the rear axle.";
CM_ SG_ 2365478910 ElctrncShckAbsrbrCtrlMdFrntAxle "Signal which indicates the current mode of operation of the electronic shock absorber control at the front axle.";
CM_ SG_ 2365478910 DamperStiffnessLift_TagAxle "Damper stiffness information of the shock absorber control at the lift of tag axle";
CM_ SG_ 2365478910 DamperStiffnessRearAxle "Damper stiffness information of the shock absorber control at the rear axle";
CM_ SG_ 2365478910 DamperStiffnessFrontAxle "Damper stiffness information of the shock absorber control at the front axle";
CM_ BO_ 2560950014 "This message conveys the scaled test results for the applicable test requested in DM7.";
CM_ SG_ 2560950014 TestLimitMinimum "The test value must be greater than or equal to Test Limit Minimum in order for the test to pass";
CM_ SG_ 2560950014 TestLimitMaximum "The test value must be less than or equal to Test Limit Maximum in order for the test to pass.";
CM_ SG_ 2560950014 TestValue "The test value collected during the test.";
CM_ SG_ 2560950014 SlotId "The SLOT Identifer is used to determine the multiplier and offset to be used to scale the test value.";
CM_ SG_ 2560950014 TestIdentifier "Test Identifier";
CM_ SG_ 2560950014 FailureModeIdentifier1 "The FMI defines the type of failure detected in the subsystem identified by an SPN.";
CM_ SG_ 2560950014 SPN1High "SPN #1 (Conversion Version 4)";
CM_ SG_ 2560950014 SPN1 "SPN #1 (Conversion Version 4)";
CM_ BO_ 2566763262 "Aftertreatment 1 Intermediate Gas";
CM_ SG_ 2566763262 Aftrtrtmnt1DslPrtcltFltrIntrmdtG "Used to identify the applicable J1939-73 FMI detected in the diesel particulate filter intermediate gas temperature sensor";
CM_ SG_ 2566763262 Aftrtrtmnt1DslPrtcltFltrInt_0001 "Temperature of engine combustion byproducts at a mid-point in the diesel particulate filter in exhaust bank 1.";
CM_ SG_ 2566763262 Aftrtrtmnt1DslPrtcltFltrDltPrssP "Used to identify the applicable J1939-73 FMI detected in the diesel particulate filter differential pressure sensor by the";
CM_ SG_ 2566763262 Aftrtrtmnt1DslPrtcltFltrDffPrss "Exhaust differential pressure measured between the intake and exhaust of a diesel particulate filter in exhaust bank 1.";
CM_ SG_ 2566763262 Aftrtrtmnt1ExhstGsTmp2PrlmnryFMI "Used to identify the applicable J1939-73 FMI detected in the exhaust gas temperature 2 sensor by the manufacturer's sensor";
CM_ SG_ 2566763262 Aftertreatment1ExhaustGasTemp2 "The reading from the exhaust gas temperature sensor located midstream of the other two temperature sensors in the";
CM_ BO_ 2565869566 "Aftertreatment 1 Outlet Gas 1";
CM_ SG_ 2565869566 Aftrtrtmnt1OtltOxygnSnsrPrlmnryF "Used to identify the applicable J1939-73 FMI detected in the aftertreatment outlet oxygen sensor by the manufacturer's";
CM_ SG_ 2565869566 Aftrtrtmnt1OtltGsSnsrPwerStatus "Indicates that the power supplied to the aftertreatment outlet gas sensor, either NOx or O2, is within the manufacturer's";
CM_ SG_ 2565869566 Aftrtrtmnt1OtltGsSnsrHtrPrlmnryF "Used to identify the applicable J1939-73 FMI detected in the heater of the outlet exhaust gas sensor, either NOx or O2, by";
CM_ SG_ 2565869566 Aftrtrtmnt1OtltNOxSnsrPrlmnryFMI "Used to identify the applicable J1939-73 FMI detected in the aftertreatment outlet NOx sensor by the manufacturer's";
CM_ SG_ 2565869566 Aftrtrtmnt1OtltGsSnsrHeaterCtrl "Indicates the heater status in the warm-up process.";
CM_ SG_ 2565869566 Aftrtrtmnt1OtltWdRngO2RdngStble "Indicates that the %O2 reading of the aftertreatment outlet gas sensor, either NOx or O2, is stable as determined by the";
CM_ SG_ 2565869566 Aftrtrtmnt1OtltNOxReadingStable "Indicates that the NOx reading of the aftertreatment outlet NOx sensor is stable as determined by the manufacturer's";
CM_ SG_ 2565869566 Aftrtrtmnt1OtletGasSensorAtTemp "Indicates that the heater element of the aftertreatment outlet gas sensor, either NOx or O2, is within the manufacturer's";
CM_ SG_ 2565869566 Aftertreatment1OutletO2 "The actual oxidation factor (%O2) of the gas within the exhaust stream.";
CM_ SG_ 2565869566 Aftertreatment1OutletNOx "The amount of combined NO and NO2 in the exhaust entering the aftertreatment system measured by a NOx sensor at";
CM_ BO_ 2566763518 "Aftertreatment 1 Outlet Gas 2";
CM_ SG_ 2566763518 Aftrtrtmnt1DslPrtcltFltrOtltGsTm "Temperature of engine combustion byproducts leaving the diesel particulate filter exhaust in exhaust bank 1.";
CM_ SG_ 2566763518 Aftrtrtmnt1DslPrtcltFltrOtltExhs "Used to identify the applicable J1939-73 FMI detected in the diesel particulate filter outlet gas temperature sensor by the";
CM_ SG_ 2566763518 Aftrtrtmnt1ExhstGsTmp3PrlmnryFMI "Used to identify the applicable J1939-73 FMI detected in the exhaust gas temperature 3 sensor by the manufacturer's";
CM_ SG_ 2566763518 Aftertreatment1ExhaustGasTemp3 "The reading from the exhaust gas temperature sensor located farthest downstream in the aftertreatment system in";
CM_ BO_ 2566749182 "Aftertreatment 1 Service";
CM_ SG_ 2566749182 DslPrtclteFilter1AshLoadPercent "Indicates the ash load percent of diesel particulate filter 1.";
CM_ SG_ 2566749182 DslPrtcltFltr1TmSncLstActvRgnrtn "Indicates the time since the last active regeneration event of diesel particulate filter 1.";
CM_ SG_ 2566749182 DslPrtcltFilter1SootLoadPercent "Indicates the soot load percent of diesel particulate filter 1.";
CM_ SG_ 2566749182 Aftrtrtmnt1DslPrtcltFltrStLdRgnr "This parameter indicates the value that will first cause DPF regeneration in aftertreatment 1.";
CM_ BO_ 2566748670 "Aftertreatment 1 Trip Information";
CM_ SG_ 2566748670 Aftrtrtmnt1TrpNmbrOfActvRgnrtnMn "Total number of Aftertreatment device 1 active regeneration manual requests by the operator during the current trip";
CM_ SG_ 2566748670 Aftrtrtmnt1TrpNmbrOfActvRgnrtnIn "Total number of aftertreatment device 1 active regeneration inhibit requests by the operator during the current trip period.";
CM_ SG_ 2566748670 Aftrtrtmnt1TrpNmbrOfPssvRgnrtns "Total number of passive regenerations by Aftertreatment device 1 during the current trip period.";
CM_ SG_ 2566748670 Aftrtrtmnt1TrpPssvRgnrationTime "Total amount of time that aftertreatment device 1 has been in passive regeneration during the current trip period.";
CM_ SG_ 2566748670 Aftrtrtmnt1TrpNmbrOfActvRgnrtns "Total number of active regenerations by Aftertreatment device 1 during the current trip period.";
CM_ SG_ 2566748670 Aftertreatment1TripDisabledTime "Total amount of time that aftertreatment 1 regeneration has been manually disabled during the current trip period.";
CM_ SG_ 2566748670 Aftrtrtmnt1TrpActvRgnrationTime "Total amount of time that aftertreatment device 1 has been in active regeneration during the current trip period.";
CM_ SG_ 2566748670 Aftertreatment1TripFuelUsed "Total amount of fuel used by aftertreatment device 1 during the current trip period.";
CM_ BO_ 2566758142 "Aftertreatment 2 Air Control 1";
CM_ SG_ 2566758142 Aftrtreatment2AirEnableActuator "Indicates whether aftertreatment 2 air enable actuator is on or off";
CM_ SG_ 2566758142 Aftertreatment2PurgeAirActuator "Indicates whether aftertreatment 2 purge air actuator is on or off";
CM_ SG_ 2566758142 Aftrtrtmnt2AtmzationAirActuator "Indicates whether aftertreatment 2 atomization air actuator is on or off";
CM_ SG_ 2566758142 Aftertreatment2AirSystemRelay "Indicates whether aftertreatment 2 air system relay is on or off";
CM_ SG_ 2566758142 Aftrtrtment2AirPressActuatorPos "Position of the aftertreatment 2 air pressure actuator as measured by a position feedback sensor.";
CM_ SG_ 2566758142 Aftertreatment2AirPressCtrl "Position that the controller is commanding the aftertreatment 2 air pressure control to maintain.";
CM_ SG_ 2566758142 Aftertreatment2PurgeAirPress "Pressure of the purge air supply for aftertreatment 2";
CM_ SG_ 2566758142 Aftertreatment2SupplyAirPress "Pressure of the supply air for aftertreatment 2.";
CM_ BO_ 2566745342 "Aftertreatment 2 Air Control 2";
CM_ SG_ 2566745342 Aftertreatment2SecondAirPress "Pressure of the secondary air for aftertreatment 2.";
CM_ SG_ 2566745342 Aftrtreatment2SecondAirMassFlow "Indicates the secondary air mass flow for aftertreatment 2.";
CM_ SG_ 2566745342 Aftertreatment2SecondAirTemp "Indicates the secondary air temperature for aftertreatment 2.";
CM_ SG_ 2566745342 Aftrtratment2SecondAirDiffPress "Indicates the secondary air differential pressure for aftertreatment 2.";
CM_ BO_ 2566758654 "Aftertreatment 2 Fuel Control 1";
CM_ SG_ 2566758654 Aftrtrtmnt2FlInjctor1HeaterCtrl "Heating level that the controller is commanding the aftertreatment 2 fuel injector 1 heater control to maintain.";
CM_ SG_ 2566758654 Aftertreatment2FuelPress1Ctrl "Position that the controller is commanding the aftertreatment 2 fuel pressure control to maintain.";
CM_ SG_ 2566758654 Aftertreatment2FuelPress1 "Pressure of the fuel for Aftertreatment 2.";
CM_ SG_ 2566758654 Aftrtratment2FuelEnableActuator "Indicates whether aftertreatment 2 fuel enable actuator is on or off";
CM_ SG_ 2566758654 Aftrtratment2RegenerationStatus "Indicates whether regeneration is active or inactive in aftertreatment 2.";
CM_ SG_ 2566758654 Aftertreatment2Ignt "Indicates whether aftertreatment 2 ignition circuit is energized by the ECM.";
CM_ SG_ 2566758654 Aftrtreatment2FuelDrainActuator "Indicates whether aftertreatment 2 fuel drain actuator is on or off";
CM_ SG_ 2566758654 Aftertreatment2FuelRate "Rate of fuel being delivered to aftertreatment 2 for regeneration";
BA_DEF_ SG_  "SigType" ENUM  "Default","Range","RangeSigned","ASCII","Discrete","Control","ReferencePGN","DTC","StringDelimiter","StringLength","StringLengthControl";
BA_DEF_ SG_  "GenSigStartValue" INT 0 10000;
BA_DEF_ SG_  "GenSigSendType" ENUM  "Cyclic","OnWrite","reserved","OnChange","reserved","reserved","reserved","NoSigSendType";
BA_DEF_ SG_  "GenSigILSupport" ENUM  "Yes","No";
BA_DEF_ SG_  "GenSigEVName" STRING ;
BA_DEF_ SG_  "SPN" INT 0 524287;
BA_DEF_ BO_  "GenMsgStartDelayTime" INT 0 100000;
BA_DEF_ BO_  "GenMsgILSupport" ENUM  "Yes","No";
BA_DEF_ BO_  "GenMsgRequestable" INT 0 1;
BA_DEF_ BO_  "GenMsgSendType" ENUM  "cyclic","reserved","cyclicIfActive","reserved","reserved","reserved","reserved","reserved","noMsgSendType";
BA_DEF_ BO_  "VFrameFormat" ENUM  "StandardCAN","ExtendedCAN","reserved","J1939PG";
BA_DEF_ BO_  "GenMsgCycleTime" INT 0 3600000;
BA_DEF_ SG_  "SystemSignalLongSymbol" STRING ;
BA_DEF_DEF_  "SigType" "Default";
BA_DEF_DEF_  "GenSigStartValue" 0;
BA_DEF_DEF_  "GenSigSendType" "NoSigSendType";
BA_DEF_DEF_  "GenSigILSupport" "Yes";
BA_DEF_DEF_  "GenSigEVName" "Env@Nodename_@Signame";
BA_DEF_DEF_  "SPN" 0;
BA_DEF_DEF_  "GenMsgStartDelayTime" 0;
BA_DEF_DEF_  "GenMsgILSupport" "Yes";
BA_DEF_DEF_  "GenMsgRequestable" 1;
BA_DEF_DEF_  "GenMsgSendType" "noMsgSendType";
BA_DEF_DEF_  "VFrameFormat" "J1939PG";
BA_DEF_DEF_  "GenMsgCycleTime" 0;
BA_DEF_DEF_  "SystemSignalLongSymbol" "";
BA_ "GenMsgCycleTime" BO_ 2364549886 10;
BA_ "GenMsgSendType" BO_ 2364549886 0;
BA_ "GenMsgCycleTime" BO_ 2566712318 1000;
BA_ "GenMsgSendType" BO_ 2566712318 0;
BA_ "GenMsgCycleTime" BO_ 2566712574 1000;
BA_ "GenMsgSendType" BO_ 2566712574 0;
BA_ "GenMsgCycleTime" BO_ 2566731006 1000;
BA_ "GenMsgSendType" BO_ 2566731006 0;
BA_ "GenMsgCycleTime" BO_ 2566731262 1000;
BA_ "GenMsgSendType" BO_ 2566731262 0;
BA_ "GenMsgCycleTime" BO_ 2566730750 1000;
BA_ "GenMsgSendType" BO_ 2566730750 0;
BA_ "GenMsgCycleTime" BO_ 2566731518 1000;
BA_ "GenMsgSendType" BO_ 2566731518 0;
BA_ "GenMsgCycleTime" BO_ 2566732030 500;
BA_ "GenMsgSendType" BO_ 2566732030 0;
BA_ "GenMsgCycleTime" BO_ 2566732286 500;
BA_ "GenMsgSendType" BO_ 2566732286 0;
BA_ "GenMsgCycleTime" BO_ 2164079358 500;
BA_ "GenMsgSendType" BO_ 2164079358 0;
BA_ "GenMsgCycleTime" BO_ 2364549118 50;
BA_ "GenMsgSendType" BO_ 2364549118 0;
BA_ "GenMsgCycleTime" BO_ 2566732798 500;
BA_ "GenMsgSendType" BO_ 2566732798 0;
BA_ "GenMsgCycleTime" BO_ 2364548862 50;
BA_ "GenMsgSendType" BO_ 2364548862 0;
BA_ "GenMsgCycleTime" BO_ 2364549374 50;
BA_ "GenMsgSendType" BO_ 2364549374 0;
BA_ "GenMsgCycleTime" BO_ 2566726142 500;
BA_ "GenMsgSendType" BO_ 2566726142 0;
BA_ "GenMsgCycleTime" BO_ 2566725630 500;
BA_ "GenMsgSendType" BO_ 2566725630 0;
BA_ "GenMsgCycleTime" BO_ 2566733310 1000;
BA_ "GenMsgSendType" BO_ 2566733310 0;
BA_ "GenMsgCycleTime" BO_ 2566733054 1000;
BA_ "GenMsgSendType" BO_ 2566733054 0;
BA_ "GenMsgCycleTime" BO_ 2499624702 500;
BA_ "GenMsgSendType" BO_ 2499624702 0;
BA_ "GenMsgCycleTime" BO_ 2566733822 500;
BA_ "GenMsgSendType" BO_ 2566733822 0;
BA_ "GenMsgCycleTime" BO_ 2566734078 500;
BA_ "GenMsgSendType" BO_ 2566734078 0;
BA_ "GenMsgCycleTime" BO_ 2364548350 50;
BA_ "GenMsgSendType" BO_ 2364548350 0;
BA_ "GenMsgCycleTime" BO_ 2566734334 500;
BA_ "GenMsgSendType" BO_ 2566734334 0;
BA_ "GenMsgCycleTime" BO_ 2364548094 50;
BA_ "GenMsgSendType" BO_ 2364548094 0;
BA_ "GenMsgCycleTime" BO_ 2364548606 50;
BA_ "GenMsgSendType" BO_ 2364548606 0;
BA_ "GenMsgCycleTime" BO_ 2566726398 500;
BA_ "GenMsgSendType" BO_ 2566726398 0;
BA_ "GenMsgCycleTime" BO_ 2566809342 1000;
BA_ "GenMsgSendType" BO_ 2566809342 0;
BA_ "GenMsgCycleTime" BO_ 2365446910 100;
BA_ "GenMsgSendType" BO_ 2365446910 0;
BA_ "GenMsgCycleTime" BO_ 2365446398 100;
BA_ "GenMsgSendType" BO_ 2365446398 0;
BA_ "GenMsgCycleTime" BO_ 2365445886 100;
BA_ "GenMsgSendType" BO_ 2365445886 0;
BA_ "GenMsgCycleTime" BO_ 2566847230 1000;
BA_ "GenMsgSendType" BO_ 2566847230 0;
BA_ "GenMsgCycleTime" BO_ 2566848254 1000;
BA_ "GenMsgSendType" BO_ 2566848254 0;
BA_ "GenMsgCycleTime" BO_ 2566725886 500;
BA_ "GenMsgSendType" BO_ 2566725886 0;
BA_ "GenMsgCycleTime" BO_ 2432520958 1000;
BA_ "GenMsgCycleTime" BO_ 2566758398 500;
BA_ "GenMsgSendType" BO_ 2566758398 0;
BA_ "GenMsgCycleTime" BO_ 2566745598 500;
BA_ "GenMsgSendType" BO_ 2566745598 0;
BA_ "GenMsgCycleTime" BO_ 2566758910 500;
BA_ "GenMsgSendType" BO_ 2566758910 0;
BA_ "GenMsgCycleTime" BO_ 2566743550 500;
BA_ "GenMsgSendType" BO_ 2566743550 0;
BA_ "GenMsgCycleTime" BO_ 2566753534 500;
BA_ "GenMsgSendType" BO_ 2566753534 0;
BA_ "GenMsgCycleTime" BO_ 2565869310 50;
BA_ "GenMsgSendType" BO_ 2565869310 0;
BA_ "GenMsgCycleTime" BO_ 2566763774 500;
BA_ "GenMsgSendType" BO_ 2566763774 0;
BA_ "GenMsgCycleTime" BO_ 2633934846 1000;
BA_ "GenMsgSendType" BO_ 2633934846 0;
BA_ "GenMsgCycleTime" BO_ 2362572542 100;
BA_ "GenMsgSendType" BO_ 2362572542 2;
BA_ "GenMsgCycleTime" BO_ 2365478910 100;
BA_ "GenMsgSendType" BO_ 2365478910 0;
BA_ "GenMsgCycleTime" BO_ 2566763262 500;
BA_ "GenMsgSendType" BO_ 2566763262 0;
BA_ "GenMsgCycleTime" BO_ 2565869566 50;
BA_ "GenMsgSendType" BO_ 2565869566 0;
BA_ "GenMsgCycleTime" BO_ 2566763518 500;
BA_ "GenMsgSendType" BO_ 2566763518 0;
BA_ "GenMsgCycleTime" BO_ 2566758142 500;
BA_ "GenMsgSendType" BO_ 2566758142 0;
BA_ "GenMsgCycleTime" BO_ 2566745342 500;
BA_ "GenMsgSendType" BO_ 2566745342 0;
BA_ "GenMsgCycleTime" BO_ 2566758654 500;
BA_ "GenMsgSendType" BO_ 2566758654 0;
BA_ "SPN" SG_ 2364549886 AngularRateMeasurementLatency 4989;
BA_ "SigType" SG_ 2364549886 AngularRateMeasurementLatency 1;
BA_ "SPN" SG_ 2364549886 YawRateExRangeFigureOfMerit 4988;
BA_ "SigType" SG_ 2364549886 YawRateExRangeFigureOfMerit 4;
BA_ "SPN" SG_ 2364549886 RollRateExRangeFigureOfMerit 4987;
BA_ "SigType" SG_ 2364549886 RollRateExRangeFigureOfMerit 4;
BA_ "SPN" SG_ 2364549886 PitchRateExRangeFigureOfMerit 4986;
BA_ "SigType" SG_ 2364549886 PitchRateExRangeFigureOfMerit 4;
BA_ "SPN" SG_ 2364549886 YawRateExRange 4985;
BA_ "SigType" SG_ 2364549886 YawRateExRange 1;
BA_ "SPN" SG_ 2364549886 RollRateExRange 4984;
BA_ "SigType" SG_ 2364549886 RollRateExRange 1;
BA_ "SPN" SG_ 2364549886 PitchRateExRange 4983;
BA_ "SigType" SG_ 2364549886 PitchRateExRange 1;
BA_ "SPN" SG_ 2566712318 Aftrtrtmnt2NOxAdsrbrDSOxRgnrtnSt 5462;
BA_ "SigType" SG_ 2566712318 Aftrtrtmnt2NOxAdsrbrDSOxRgnrtnSt 4;
BA_ "SystemSignalLongSymbol" SG_ 2566712318 Aftrtrtmnt2NOxAdsrbrDSOxRgnrtnSt "Aftrtrtmnt2NOxAdsrbrDSOxRgnrtnStts";
BA_ "SPN" SG_ 2566712318 Aftrtrtmnt2NOxAdsrbrDNOxRgnrtnSt 5460;
BA_ "SigType" SG_ 2566712318 Aftrtrtmnt2NOxAdsrbrDNOxRgnrtnSt 4;
BA_ "SystemSignalLongSymbol" SG_ 2566712318 Aftrtrtmnt2NOxAdsrbrDNOxRgnrtnSt "Aftrtrtmnt2NOxAdsrbrDNOxRgnrtnStts";
BA_ "SPN" SG_ 2566712574 Aftrtrtmnt1NOxAdsrbrDSOxRgnrtnSt 5461;
BA_ "SigType" SG_ 2566712574 Aftrtrtmnt1NOxAdsrbrDSOxRgnrtnSt 4;
BA_ "SystemSignalLongSymbol" SG_ 2566712574 Aftrtrtmnt1NOxAdsrbrDSOxRgnrtnSt "Aftrtrtmnt1NOxAdsrbrDSOxRgnrtnStts";
BA_ "SPN" SG_ 2566712574 Aftrtrtmnt1NOxAdsrbrDNOxRgnrtnSt 5459;
BA_ "SigType" SG_ 2566712574 Aftrtrtmnt1NOxAdsrbrDNOxRgnrtnSt 4;
BA_ "SystemSignalLongSymbol" SG_ 2566712574 Aftrtrtmnt1NOxAdsrbrDNOxRgnrtnSt "Aftrtrtmnt1NOxAdsrbrDNOxRgnrtnStts";
BA_ "SPN" SG_ 2164078590 Aftrtrtmnt2SCRCtlystCnvrsnEffcnc 4419;
BA_ "SigType" SG_ 2164078590 Aftrtrtmnt2SCRCtlystCnvrsnEffcnc 1;
BA_ "SystemSignalLongSymbol" SG_ 2164078590 Aftrtrtmnt2SCRCtlystCnvrsnEffcnc "Aftrtrtmnt2SCRCtlystCnvrsnEffcncy";
BA_ "SPN" SG_ 2164078590 Aftrtrtmnt2SCRCmddCtlystRgntCnsm 4418;
BA_ "SigType" SG_ 2164078590 Aftrtrtmnt2SCRCmddCtlystRgntCnsm 1;
BA_ "SystemSignalLongSymbol" SG_ 2164078590 Aftrtrtmnt2SCRCmddCtlystRgntCnsm "Aftrtrtmnt2SCRCmddCtlystRgntCnsmptn";
BA_ "SPN" SG_ 2164078590 Aftrtrtmnt2SCRAvrgCtlystRgntCnsm 4417;
BA_ "SigType" SG_ 2164078590 Aftrtrtmnt2SCRAvrgCtlystRgntCnsm 1;
BA_ "SystemSignalLongSymbol" SG_ 2164078590 Aftrtrtmnt2SCRAvrgCtlystRgntCnsm "Aftrtrtmnt2SCRAvrgCtlystRgntCnsmptn";
BA_ "SPN" SG_ 2566731006 Aftrtrtmnt2SCRCtlystRgntTnk2HtrP 4439;
BA_ "SigType" SG_ 2566731006 Aftrtrtmnt2SCRCtlystRgntTnk2HtrP 1;
BA_ "SystemSignalLongSymbol" SG_ 2566731006 Aftrtrtmnt2SCRCtlystRgntTnk2HtrP "Aftrtrtmnt2SCRCtlystRgntTnk2HtrPrlmnryFMI";
BA_ "SPN" SG_ 2566731006 Aftrtrtmnt2SCRCtlystRgntTnk2Htr 4438;
BA_ "SigType" SG_ 2566731006 Aftrtrtmnt2SCRCtlystRgntTnk2Htr 4;
BA_ "SPN" SG_ 2566731006 Aftrtrtmnt2SCRRgntTnk2TmpPrlmnry 4437;
BA_ "SigType" SG_ 2566731006 Aftrtrtmnt2SCRRgntTnk2TmpPrlmnry 1;
BA_ "SystemSignalLongSymbol" SG_ 2566731006 Aftrtrtmnt2SCRRgntTnk2TmpPrlmnry "Aftrtrtmnt2SCRRgntTnk2TmpPrlmnryFMI";
BA_ "SPN" SG_ 2566731006 Aftrtrtmnt2SCRCtlystRgntTnk2LvlP 4436;
BA_ "SigType" SG_ 2566731006 Aftrtrtmnt2SCRCtlystRgntTnk2LvlP 1;
BA_ "SystemSignalLongSymbol" SG_ 2566731006 Aftrtrtmnt2SCRCtlystRgntTnk2LvlP "Aftrtrtmnt2SCRCtlystRgntTnk2LvlPrlmnryFMI";
BA_ "SPN" SG_ 2566731006 Aftrtrtmnt2SCRCtlystRgntTnk2Lvl2 4435;
BA_ "SigType" SG_ 2566731006 Aftrtrtmnt2SCRCtlystRgntTnk2Lvl2 1;
BA_ "SPN" SG_ 2566731006 Aftrtrtmnt2SCRCtlystRgntTnk2Tmp 4434;
BA_ "SigType" SG_ 2566731006 Aftrtrtmnt2SCRCtlystRgntTnk2Tmp 1;
BA_ "SPN" SG_ 2566731006 Aftrtrtmnt2SCRCtlystRgntTnk2Lvl 4433;
BA_ "SigType" SG_ 2566731006 Aftrtrtmnt2SCRCtlystRgntTnk2Lvl 1;
BA_ "SPN" SG_ 2566731262 Aftrtrtmnt2SCRCtlystRgntTnk1HtrP 4432;
BA_ "SigType" SG_ 2566731262 Aftrtrtmnt2SCRCtlystRgntTnk1HtrP 1;
BA_ "SystemSignalLongSymbol" SG_ 2566731262 Aftrtrtmnt2SCRCtlystRgntTnk1HtrP "Aftrtrtmnt2SCRCtlystRgntTnk1HtrPrlmnryFMI";
BA_ "SPN" SG_ 2566731262 Aftrtrtmnt2SCRCtalystTankHeater 4431;
BA_ "SigType" SG_ 2566731262 Aftrtrtmnt2SCRCtalystTankHeater 1;
BA_ "SPN" SG_ 2566731262 Aftrtrtmnt2SCRCtlystRgntTnk1TmpP 4430;
BA_ "SigType" SG_ 2566731262 Aftrtrtmnt2SCRCtlystRgntTnk1TmpP 1;
BA_ "SystemSignalLongSymbol" SG_ 2566731262 Aftrtrtmnt2SCRCtlystRgntTnk1TmpP "Aftrtrtmnt2SCRCtlystRgntTnk1TmpPrlmnryFMI";
BA_ "SPN" SG_ 2566731262 Aftrtrtmnt2SCRCtlystTnkLvlPrlmnr 4429;
BA_ "SigType" SG_ 2566731262 Aftrtrtmnt2SCRCtlystTnkLvlPrlmnr 1;
BA_ "SystemSignalLongSymbol" SG_ 2566731262 Aftrtrtmnt2SCRCtlystTnkLvlPrlmnr "Aftrtrtmnt2SCRCtlystTnkLvlPrlmnryFMI";
BA_ "SPN" SG_ 2566731262 Aftrtrtmnt2SCRCtalystTankLevel2 4428;
BA_ "SigType" SG_ 2566731262 Aftrtrtmnt2SCRCtalystTankLevel2 1;
BA_ "SPN" SG_ 2566731262 Aftrtrtment2SCRCatalystTankTemp 4427;
BA_ "SigType" SG_ 2566731262 Aftrtrtment2SCRCatalystTankTemp 1;
BA_ "SPN" SG_ 2566731262 Aftrtrtmnt2SCRCatalystTankLevel 4426;
BA_ "SigType" SG_ 2566731262 Aftrtrtmnt2SCRCatalystTankLevel 1;
BA_ "SPN" SG_ 2566730750 Aftrtrtmnt2SCRCtlystRgntTnkDrnVl 5439;
BA_ "SigType" SG_ 2566730750 Aftrtrtmnt2SCRCtlystRgntTnkDrnVl 1;
BA_ "SystemSignalLongSymbol" SG_ 2566730750 Aftrtrtmnt2SCRCtlystRgntTnkDrnVl "Aftrtrtmnt2SCRCtlystRgntTnkDrnVlvCmd";
BA_ "SPN" SG_ 2566730750 Aftrtrtmnt2SCRCtlystRgntPmpStte 5438;
BA_ "SigType" SG_ 2566730750 Aftrtrtmnt2SCRCtlystRgntPmpStte 4;
BA_ "SPN" SG_ 2566730750 Aftrtrtmnt2SCRCtlystRgntTnkFllVl 5437;
BA_ "SigType" SG_ 2566730750 Aftrtrtmnt2SCRCtlystRgntTnkFllVl 1;
BA_ "SystemSignalLongSymbol" SG_ 2566730750 Aftrtrtmnt2SCRCtlystRgntTnkFllVl "Aftrtrtmnt2SCRCtlystRgntTnkFllVlvCmd";
BA_ "SPN" SG_ 2566730750 Aftrtrtmnt2SCRCtlystRgntRtrnVlv 4442;
BA_ "SigType" SG_ 2566730750 Aftrtrtmnt2SCRCtlystRgntRtrnVlv 1;
BA_ "SPN" SG_ 2566730750 Aftrtrtmnt2SCRCtlystRgntPmpDrvPr 4441;
BA_ "SigType" SG_ 2566730750 Aftrtrtmnt2SCRCtlystRgntPmpDrvPr 1;
BA_ "SystemSignalLongSymbol" SG_ 2566730750 Aftrtrtmnt2SCRCtlystRgntPmpDrvPr "Aftrtrtmnt2SCRCtlystRgntPmpDrvPrcntg";
BA_ "SPN" SG_ 2566730750 Aftrtrtmnt2SCRCtlystRgntPmpMtrSp 4440;
BA_ "SigType" SG_ 2566730750 Aftrtrtmnt2SCRCtlystRgntPmpMtrSp 1;
BA_ "SystemSignalLongSymbol" SG_ 2566730750 Aftrtrtmnt2SCRCtlystRgntPmpMtrSp "Aftrtrtmnt2SCRCtlystRgntPmpMtrSpd";
BA_ "SPN" SG_ 2566731518 Aftrtrtmnt2SCRCtlystReagentType 4425;
BA_ "SigType" SG_ 2566731518 Aftrtrtmnt2SCRCtlystReagentType 4;
BA_ "SPN" SG_ 2566731518 Aftrtrtmnt2SCRCtlystRgntPrprtsPr 4424;
BA_ "SigType" SG_ 2566731518 Aftrtrtmnt2SCRCtlystRgntPrprtsPr 1;
BA_ "SystemSignalLongSymbol" SG_ 2566731518 Aftrtrtmnt2SCRCtlystRgntPrprtsPr "Aftrtrtmnt2SCRCtlystRgntPrprtsPrlmnryFMI";
BA_ "SPN" SG_ 2566731518 Aftrtrtmnt2SCRCtlystRgntTmp2Prlm 4423;
BA_ "SigType" SG_ 2566731518 Aftrtrtmnt2SCRCtlystRgntTmp2Prlm 1;
BA_ "SystemSignalLongSymbol" SG_ 2566731518 Aftrtrtmnt2SCRCtlystRgntTmp2Prlm "Aftrtrtmnt2SCRCtlystRgntTmp2PrlmnryFMI";
BA_ "SPN" SG_ 2566731518 Aftrtrtmnt2SCRCtlystRgntCndctvty 4422;
BA_ "SigType" SG_ 2566731518 Aftrtrtmnt2SCRCtlystRgntCndctvty 1;
BA_ "SPN" SG_ 2566731518 Aftrtrtmnt2SCRCtlystRgntCncntrtn 4421;
BA_ "SigType" SG_ 2566731518 Aftrtrtmnt2SCRCtlystRgntCncntrtn 1;
BA_ "SPN" SG_ 2566731518 Aftrtrtmnt2SCRCtlystRagentTemp2 4420;
BA_ "SigType" SG_ 2566731518 Aftrtrtmnt2SCRCtlystRagentTemp2 1;
BA_ "SPN" SG_ 2566732030 Aftrtrtmnt2SCRCtlystOtltGsTmpPrl 4416;
BA_ "SigType" SG_ 2566732030 Aftrtrtmnt2SCRCtlystOtltGsTmpPrl 4;
BA_ "SystemSignalLongSymbol" SG_ 2566732030 Aftrtrtmnt2SCRCtlystOtltGsTmpPrl "Aftrtrtmnt2SCRCtlystOtltGsTmpPrlmnryFMI";
BA_ "SPN" SG_ 2566732030 Aftrtrtmnt2SCRCtlystOtltGasTemp 4415;
BA_ "SigType" SG_ 2566732030 Aftrtrtmnt2SCRCtlystOtltGasTemp 1;
BA_ "SPN" SG_ 2566732030 Aftrtrtmnt2SCRCtlystIntkGsTmpPrl 4414;
BA_ "SigType" SG_ 2566732030 Aftrtrtmnt2SCRCtlystIntkGsTmpPrl 4;
BA_ "SystemSignalLongSymbol" SG_ 2566732030 Aftrtrtmnt2SCRCtlystIntkGsTmpPrl "Aftrtrtmnt2SCRCtlystIntkGsTmpPrlmnryFMI";
BA_ "SPN" SG_ 2566732030 Aftrtrtmnt2SCRCtlystIntkGasTemp 4413;
BA_ "SigType" SG_ 2566732030 Aftrtrtmnt2SCRCtlystIntkGasTemp 1;
BA_ "SPN" SG_ 2566732286 Aftrtrtmnt2SCRCtlystExhstGsDffPr 4412;
BA_ "SigType" SG_ 2566732286 Aftrtrtmnt2SCRCtlystExhstGsDffPr 4;
BA_ "SystemSignalLongSymbol" SG_ 2566732286 Aftrtrtmnt2SCRCtlystExhstGsDffPr "Aftrtrtmnt2SCRCtlystExhstGsDffPrssPrlmnryFMI";
BA_ "SPN" SG_ 2566732286 Aftrtrtmnt2SCRCtlystExhstGs_0000 4411;
BA_ "SigType" SG_ 2566732286 Aftrtrtmnt2SCRCtlystExhstGs_0000 1;
BA_ "SystemSignalLongSymbol" SG_ 2566732286 Aftrtrtmnt2SCRCtlystExhstGs_0000 "Aftrtrtmnt2SCRCtlystExhstGsDffPrss";
BA_ "SPN" SG_ 2164079358 Aftrtrtmnt2SCRCtlystTnk2HterCmd 5415;
BA_ "SigType" SG_ 2164079358 Aftrtrtmnt2SCRCtlystTnk2HterCmd 1;
BA_ "SPN" SG_ 2164079358 Aftrtrtmnt2SCRCtlystTnkHaterCmd 5138;
BA_ "SigType" SG_ 2164079358 Aftrtrtmnt2SCRCtlystTnkHaterCmd 1;
BA_ "SPN" SG_ 2164079358 Aftrtrtmnt2SCRCtlystRgntLnHter4 4410;
BA_ "SigType" SG_ 2164079358 Aftrtrtmnt2SCRCtlystRgntLnHter4 4;
BA_ "SPN" SG_ 2164079358 Aftrtrtmnt2SCRCtlystRgntLnHter3 4409;
BA_ "SigType" SG_ 2164079358 Aftrtrtmnt2SCRCtlystRgntLnHter3 4;
BA_ "SPN" SG_ 2164079358 Aftrtrtmnt2SCRCtlystRgntLnHter2 4408;
BA_ "SigType" SG_ 2164079358 Aftrtrtmnt2SCRCtlystRgntLnHter2 4;
BA_ "SPN" SG_ 2164079358 Aftrtrtmnt2SCRCtlystRgntLnHter1 4407;
BA_ "SigType" SG_ 2164079358 Aftrtrtmnt2SCRCtlystRgntLnHter1 4;
BA_ "SPN" SG_ 2164079358 Aftrtrtmnt2SCRDserHeatingModeRq 4406;
BA_ "SigType" SG_ 2164079358 Aftrtrtmnt2SCRDserHeatingModeRq 4;
BA_ "SPN" SG_ 2164079358 Aftrtrtmnt2SCRDsrFltSpprssionRq 4405;
BA_ "SigType" SG_ 2164079358 Aftrtrtmnt2SCRDsrFltSpprssionRq 4;
BA_ "SPN" SG_ 2364549118 Aftrtrtmnt2SCRRqdRgntQnttyFrIntg 4403;
BA_ "SigType" SG_ 2364549118 Aftrtrtmnt2SCRRqdRgntQnttyFrIntg 1;
BA_ "SystemSignalLongSymbol" SG_ 2364549118 Aftrtrtmnt2SCRRqdRgntQnttyFrIntg "Aftrtrtmnt2SCRRqdRgntQnttyFrIntgrtr";
BA_ "SPN" SG_ 2364549118 Aftrtratment2SCRSystemRqedState 4402;
BA_ "SigType" SG_ 2364549118 Aftrtratment2SCRSystemRqedState 4;
BA_ "SPN" SG_ 2364549118 Aftrtrtmnt2SCRRqdDsngRgntQntity 4401;
BA_ "SigType" SG_ 2364549118 Aftrtrtmnt2SCRRqdDsngRgntQntity 1;
BA_ "SPN" SG_ 2566732798 Aftrtrtmnt2SCRCtlystRgntLnHtr4Pr 4400;
BA_ "SigType" SG_ 2566732798 Aftrtrtmnt2SCRCtlystRgntLnHtr4Pr 1;
BA_ "SystemSignalLongSymbol" SG_ 2566732798 Aftrtrtmnt2SCRCtlystRgntLnHtr4Pr "Aftrtrtmnt2SCRCtlystRgntLnHtr4PrlmnryFMI";
BA_ "SPN" SG_ 2566732798 Aftrtrtmnt2SCRCtlystRgntLnHtr4St 4399;
BA_ "SigType" SG_ 2566732798 Aftrtrtmnt2SCRCtlystRgntLnHtr4St 4;
BA_ "SystemSignalLongSymbol" SG_ 2566732798 Aftrtrtmnt2SCRCtlystRgntLnHtr4St "Aftrtrtmnt2SCRCtlystRgntLnHtr4Stt";
BA_ "SPN" SG_ 2566732798 Aftrtrtmnt2SCRCtlystRgntLnHtr3Pr 4398;
BA_ "SigType" SG_ 2566732798 Aftrtrtmnt2SCRCtlystRgntLnHtr3Pr 1;
BA_ "SystemSignalLongSymbol" SG_ 2566732798 Aftrtrtmnt2SCRCtlystRgntLnHtr3Pr "Aftrtrtmnt2SCRCtlystRgntLnHtr3PrlmnryFMI";
BA_ "SPN" SG_ 2566732798 Aftrtrtmnt2SCRCtlystRgntLnHtr3St 4397;
BA_ "SigType" SG_ 2566732798 Aftrtrtmnt2SCRCtlystRgntLnHtr3St 4;
BA_ "SystemSignalLongSymbol" SG_ 2566732798 Aftrtrtmnt2SCRCtlystRgntLnHtr3St "Aftrtrtmnt2SCRCtlystRgntLnHtr3Stt";
BA_ "SPN" SG_ 2566732798 Aftrtrtmnt2SCRCtlystRgntLnHtr2Pr 4396;
BA_ "SigType" SG_ 2566732798 Aftrtrtmnt2SCRCtlystRgntLnHtr2Pr 1;
BA_ "SystemSignalLongSymbol" SG_ 2566732798 Aftrtrtmnt2SCRCtlystRgntLnHtr2Pr "Aftrtrtmnt2SCRCtlystRgntLnHtr2PrlmnryFMI";
BA_ "SPN" SG_ 2566732798 Aftrtrtmnt2SCRCtlystRgntLnHtr2St 4395;
BA_ "SigType" SG_ 2566732798 Aftrtrtmnt2SCRCtlystRgntLnHtr2St 4;
BA_ "SystemSignalLongSymbol" SG_ 2566732798 Aftrtrtmnt2SCRCtlystRgntLnHtr2St "Aftrtrtmnt2SCRCtlystRgntLnHtr2Stt";
BA_ "SPN" SG_ 2566732798 Aftrtrtmnt2SCRCtlystRgntLnHtr1Pr 4394;
BA_ "SigType" SG_ 2566732798 Aftrtrtmnt2SCRCtlystRgntLnHtr1Pr 1;
BA_ "SystemSignalLongSymbol" SG_ 2566732798 Aftrtrtmnt2SCRCtlystRgntLnHtr1Pr "Aftrtrtmnt2SCRCtlystRgntLnHtr1PrlmnryFMI";
BA_ "SPN" SG_ 2566732798 Aftrtrtmnt2SCRCtlystRgntLnHtr1St 4393;
BA_ "SigType" SG_ 2566732798 Aftrtrtmnt2SCRCtlystRgntLnHtr1St 4;
BA_ "SystemSignalLongSymbol" SG_ 2566732798 Aftrtrtmnt2SCRCtlystRgntLnHtr1St "Aftrtrtmnt2SCRCtlystRgntLnHtr1Stt";
BA_ "SPN" SG_ 2566732798 Aftrtrtmnt2SCRFedbackCtrlStatus 4392;
BA_ "SigType" SG_ 2566732798 Aftrtrtmnt2SCRFedbackCtrlStatus 4;
BA_ "SPN" SG_ 2566732798 Aftrtrtmnt2SCRDsngVlvExhstTmpRdc 4391;
BA_ "SigType" SG_ 2566732798 Aftrtrtmnt2SCRDsngVlvExhstTmpRdc 4;
BA_ "SystemSignalLongSymbol" SG_ 2566732798 Aftrtrtmnt2SCRDsngVlvExhstTmpRdc "Aftrtrtmnt2SCRDsngVlvExhstTmpRdctnRq";
BA_ "SPN" SG_ 2566732798 Aftrtrtmnt2SCRDosingReagentTemp 4390;
BA_ "SigType" SG_ 2566732798 Aftrtrtmnt2SCRDosingReagentTemp 1;
BA_ "SPN" SG_ 2566732798 Aftrtrtmnt2SCRDsngArAssistValve 4389;
BA_ "SigType" SG_ 2566732798 Aftrtrtmnt2SCRDsngArAssistValve 1;
BA_ "SPN" SG_ 2566732798 Aftrtrtmnt2SCRDsngArAssstAbsPrss 4388;
BA_ "SigType" SG_ 2566732798 Aftrtrtmnt2SCRDsngArAssstAbsPrss 1;
BA_ "SPN" SG_ 2364548862 Aftrtrtmnt2SCRDsngRgentAbsPress 4387;
BA_ "SigType" SG_ 2364548862 Aftrtrtmnt2SCRDsngRgentAbsPress 1;
BA_ "SPN" SG_ 2364548862 Aftrtrtmnt2SCRActlRgntQnttyOfInt 4386;
BA_ "SigType" SG_ 2364548862 Aftrtrtmnt2SCRActlRgntQnttyOfInt 1;
BA_ "SystemSignalLongSymbol" SG_ 2364548862 Aftrtrtmnt2SCRActlRgntQnttyOfInt "Aftrtrtmnt2SCRActlRgntQnttyOfIntgrtr";
BA_ "SPN" SG_ 2364548862 Aftertreatment2SCRSystemState 4385;
BA_ "SigType" SG_ 2364548862 Aftertreatment2SCRSystemState 4;
BA_ "SPN" SG_ 2364548862 Aftrtrtmnt2SCRActlDsngRgntQntty 4384;
BA_ "SigType" SG_ 2364548862 Aftrtrtmnt2SCRActlDsngRgntQntty 1;
BA_ "SPN" SG_ 2364549374 Aftrtrtmnt2OtltNH3GsSnsrHtrCtrl 4449;
BA_ "SigType" SG_ 2364549374 Aftrtrtmnt2OtltNH3GsSnsrHtrCtrl 4;
BA_ "SPN" SG_ 2364549374 Aftrtrtmnt2OtltNH3GsSnsrHtrPrlmn 4448;
BA_ "SigType" SG_ 2364549374 Aftrtrtmnt2OtltNH3GsSnsrHtrPrlmn 1;
BA_ "SystemSignalLongSymbol" SG_ 2364549374 Aftrtrtmnt2OtltNH3GsSnsrHtrPrlmn "Aftrtrtmnt2OtltNH3GsSnsrHtrPrlmnryFMI";
BA_ "SPN" SG_ 2364549374 Aftrtrtmnt2OtltNH3GsSnsorAtTemp 4447;
BA_ "SigType" SG_ 2364549374 Aftrtrtmnt2OtltNH3GsSnsorAtTemp 4;
BA_ "SPN" SG_ 2364549374 Aftrtrtmnt2OtltNH3GsSnsrPwrInRng 4446;
BA_ "SigType" SG_ 2364549374 Aftrtrtmnt2OtltNH3GsSnsrPwrInRng 4;
BA_ "SPN" SG_ 2364549374 Aftrtrtmnt2OtltNH3ReadingStable 4445;
BA_ "SigType" SG_ 2364549374 Aftrtrtmnt2OtltNH3ReadingStable 4;
BA_ "SPN" SG_ 2364549374 Aftrtrtmnt2OtltNH3SnsrPrlmnryFMI 4444;
BA_ "SigType" SG_ 2364549374 Aftrtrtmnt2OtltNH3SnsrPrlmnryFMI 1;
BA_ "SPN" SG_ 2364549374 Aftertreatment2OutletNH3 4443;
BA_ "SigType" SG_ 2364549374 Aftertreatment2OutletNH3 1;
BA_ "SPN" SG_ 2566726142 Aftrtrtmnt2GsOxdtnCtlystDffPrssP 4764;
BA_ "SigType" SG_ 2566726142 Aftrtrtmnt2GsOxdtnCtlystDffPrssP 1;
BA_ "SystemSignalLongSymbol" SG_ 2566726142 Aftrtrtmnt2GsOxdtnCtlystDffPrssP "Aftrtrtmnt2GsOxdtnCtlystDffPrssPrlmnryFMI";
BA_ "SPN" SG_ 2566726142 Aftrtrtmnt2GsOxdtnCtlystOtltGsTm 4763;
BA_ "SigType" SG_ 2566726142 Aftrtrtmnt2GsOxdtnCtlystOtltGsTm 1;
BA_ "SystemSignalLongSymbol" SG_ 2566726142 Aftrtrtmnt2GsOxdtnCtlystOtltGsTm "Aftrtrtmnt2GsOxdtnCtlystOtltGsTmpPrlmnryFMI";
BA_ "SPN" SG_ 2566726142 Aftrtrtmnt2GsOxdtnCtlystIntkGsTm 4762;
BA_ "SigType" SG_ 2566726142 Aftrtrtmnt2GsOxdtnCtlystIntkGsTm 1;
BA_ "SystemSignalLongSymbol" SG_ 2566726142 Aftrtrtmnt2GsOxdtnCtlystIntkGsTm "Aftrtrtmnt2GsOxdtnCtlystIntkGsTmpPrlmnryFMI";
BA_ "SPN" SG_ 2566726142 Aftrtrtmnt2GsOxdtnCtlystDffPrss 4761;
BA_ "SigType" SG_ 2566726142 Aftrtrtmnt2GsOxdtnCtlystDffPrss 1;
BA_ "SPN" SG_ 2566726142 Aftrtrtmnt2GsOxdtnCtlystOtl_0000 4760;
BA_ "SigType" SG_ 2566726142 Aftrtrtmnt2GsOxdtnCtlystOtl_0000 1;
BA_ "SystemSignalLongSymbol" SG_ 2566726142 Aftrtrtmnt2GsOxdtnCtlystOtl_0000 "Aftrtrtmnt2GsOxdtnCtlystOtltGsTmp";
BA_ "SPN" SG_ 2566726142 Aftrtrtmnt2GsOxdtnCtlystInt_0000 4759;
BA_ "SigType" SG_ 2566726142 Aftrtrtmnt2GsOxdtnCtlystInt_0000 1;
BA_ "SystemSignalLongSymbol" SG_ 2566726142 Aftrtrtmnt2GsOxdtnCtlystInt_0000 "Aftrtrtmnt2GsOxdtnCtlystIntkGsTmp";
BA_ "SPN" SG_ 2566725630 Aftrtrtmnt2DslOxdtnCtlystOtltGsT 4775;
BA_ "SigType" SG_ 2566725630 Aftrtrtmnt2DslOxdtnCtlystOtltGsT 1;
BA_ "SystemSignalLongSymbol" SG_ 2566725630 Aftrtrtmnt2DslOxdtnCtlystOtltGsT "Aftrtrtmnt2DslOxdtnCtlystOtltGsTmpPrlmnryFMI";
BA_ "SPN" SG_ 2566725630 Aftrtrtmnt2DslOxdtnCtlystIntkGsT 4774;
BA_ "SigType" SG_ 2566725630 Aftrtrtmnt2DslOxdtnCtlystIntkGsT 1;
BA_ "SystemSignalLongSymbol" SG_ 2566725630 Aftrtrtmnt2DslOxdtnCtlystIntkGsT "Aftrtrtmnt2DslOxdtnCtlystIntkGsTmpPrlmnryFMI";
BA_ "SPN" SG_ 2566725630 Aftrtrtmnt2DslOxdtnCtlystDffPrss 4773;
BA_ "SigType" SG_ 2566725630 Aftrtrtmnt2DslOxdtnCtlystDffPrss 1;
BA_ "SPN" SG_ 2566725630 Aftrtrtmnt2DslOxdtnCtlystOt_0000 4772;
BA_ "SigType" SG_ 2566725630 Aftrtrtmnt2DslOxdtnCtlystOt_0000 1;
BA_ "SystemSignalLongSymbol" SG_ 2566725630 Aftrtrtmnt2DslOxdtnCtlystOt_0000 "Aftrtrtmnt2DslOxdtnCtlystOtltGsTmp";
BA_ "SPN" SG_ 2566725630 Aftrtrtmnt2DslOxdtnCtlystIn_0000 4771;
BA_ "SigType" SG_ 2566725630 Aftrtrtmnt2DslOxdtnCtlystIn_0000 1;
BA_ "SystemSignalLongSymbol" SG_ 2566725630 Aftrtrtmnt2DslOxdtnCtlystIn_0000 "Aftrtrtmnt2DslOxdtnCtlystIntkGsTmp";
BA_ "SPN" SG_ 2566725630 Aftrtrtmnt2DslOxdtnCtlystDf_0000 4776;
BA_ "SigType" SG_ 2566725630 Aftrtrtmnt2DslOxdtnCtlystDf_0000 1;
BA_ "SystemSignalLongSymbol" SG_ 2566725630 Aftrtrtmnt2DslOxdtnCtlystDf_0000 "Aftrtrtmnt2DslOxdtnCtlystDffPrssPrlmnryFMI";
BA_ "SPN" SG_ 2566733310 Aftrtrtmnt1SCRCtlystRgntTnk2HtrP 4373;
BA_ "SigType" SG_ 2566733310 Aftrtrtmnt1SCRCtlystRgntTnk2HtrP 1;
BA_ "SystemSignalLongSymbol" SG_ 2566733310 Aftrtrtmnt1SCRCtlystRgntTnk2HtrP "Aftrtrtmnt1SCRCtlystRgntTnk2HtrPrlmnryFMI";
BA_ "SPN" SG_ 2566733310 Aftrtrtmnt1SCRCtlystRgntTnk2Htr 4372;
BA_ "SigType" SG_ 2566733310 Aftrtrtmnt1SCRCtlystRgntTnk2Htr 1;
BA_ "SPN" SG_ 2566733310 Aftrtrtmnt1SCRRgntTnk2TmpPrlmnry 4371;
BA_ "SigType" SG_ 2566733310 Aftrtrtmnt1SCRRgntTnk2TmpPrlmnry 1;
BA_ "SystemSignalLongSymbol" SG_ 2566733310 Aftrtrtmnt1SCRRgntTnk2TmpPrlmnry "Aftrtrtmnt1SCRRgntTnk2TmpPrlmnryFMI";
BA_ "SPN" SG_ 2566733310 Aftrtrtmnt1SCRCtlystRgntTnk2LvlP 4370;
BA_ "SigType" SG_ 2566733310 Aftrtrtmnt1SCRCtlystRgntTnk2LvlP 1;
BA_ "SystemSignalLongSymbol" SG_ 2566733310 Aftrtrtmnt1SCRCtlystRgntTnk2LvlP "Aftrtrtmnt1SCRCtlystRgntTnk2LvlPrlmnryFMI";
BA_ "SPN" SG_ 2566733310 Aftrtrtmnt1SCRCtlystRgntTnk2Lvl2 4369;
BA_ "SigType" SG_ 2566733310 Aftrtrtmnt1SCRCtlystRgntTnk2Lvl2 1;
BA_ "SPN" SG_ 2566733310 Aftrtrtmnt1SCRCtlystRgntTnk2Tmp 4368;
BA_ "SigType" SG_ 2566733310 Aftrtrtmnt1SCRCtlystRgntTnk2Tmp 1;
BA_ "SPN" SG_ 2566733310 Aftrtrtmnt1SCRCtlystRgntTnk2Lvl 4367;
BA_ "SigType" SG_ 2566733310 Aftrtrtmnt1SCRCtlystRgntTnk2Lvl 1;
BA_ "SPN" SG_ 2566733054 Aftrtrtmnt1SCRCtlystRgntTnkDrnVl 5436;
BA_ "SigType" SG_ 2566733054 Aftrtrtmnt1SCRCtlystRgntTnkDrnVl 1;
BA_ "SystemSignalLongSymbol" SG_ 2566733054 Aftrtrtmnt1SCRCtlystRgntTnkDrnVl "Aftrtrtmnt1SCRCtlystRgntTnkDrnVlvCmd";
BA_ "SPN" SG_ 2566733054 Aftrtrtmnt1SCRCtlystRgntPmpStte 5435;
BA_ "SigType" SG_ 2566733054 Aftrtrtmnt1SCRCtlystRgntPmpStte 4;
BA_ "SPN" SG_ 2566733054 Aftrtrtmnt1SCRCtlystRgntTnkFllVl 5434;
BA_ "SigType" SG_ 2566733054 Aftrtrtmnt1SCRCtlystRgntTnkFllVl 1;
BA_ "SystemSignalLongSymbol" SG_ 2566733054 Aftrtrtmnt1SCRCtlystRgntTnkFllVl "Aftrtrtmnt1SCRCtlystRgntTnkFllVlvCmd";
BA_ "SPN" SG_ 2566733054 Aftrtrtmnt1SCRCtlystRgntRtrnVlv 4376;
BA_ "SigType" SG_ 2566733054 Aftrtrtmnt1SCRCtlystRgntRtrnVlv 1;
BA_ "SPN" SG_ 2566733054 Aftrtrtmnt1SCRCtlystRgntPmpDrvPr 4375;
BA_ "SigType" SG_ 2566733054 Aftrtrtmnt1SCRCtlystRgntPmpDrvPr 1;
BA_ "SystemSignalLongSymbol" SG_ 2566733054 Aftrtrtmnt1SCRCtlystRgntPmpDrvPr "Aftrtrtmnt1SCRCtlystRgntPmpDrvPrcntg";
BA_ "SPN" SG_ 2566733054 Aftrtrtmnt1SCRCtlystRgntPmpMtrSp 4374;
BA_ "SigType" SG_ 2566733054 Aftrtrtmnt1SCRCtlystRgntPmpMtrSp 1;
BA_ "SystemSignalLongSymbol" SG_ 2566733054 Aftrtrtmnt1SCRCtlystRgntPmpMtrSp "Aftrtrtmnt1SCRCtlystRgntPmpMtrSpd";
BA_ "SPN" SG_ 2499624702 Aftrtrtmnt1SCRCtlystOtltGsTmpPrl 4362;
BA_ "SigType" SG_ 2499624702 Aftrtrtmnt1SCRCtlystOtltGsTmpPrl 4;
BA_ "SystemSignalLongSymbol" SG_ 2499624702 Aftrtrtmnt1SCRCtlystOtltGsTmpPrl "Aftrtrtmnt1SCRCtlystOtltGsTmpPrlmnryFMI";
BA_ "SPN" SG_ 2499624702 Aftrtrtmnt1SCRCtlystOtltGasTemp 4363;
BA_ "SigType" SG_ 2499624702 Aftrtrtmnt1SCRCtlystOtltGasTemp 1;
BA_ "SPN" SG_ 2499624702 Aftrtrtmnt1SCRCtlystIntkGsTmpPrl 4361;
BA_ "SigType" SG_ 2499624702 Aftrtrtmnt1SCRCtlystIntkGsTmpPrl 4;
BA_ "SystemSignalLongSymbol" SG_ 2499624702 Aftrtrtmnt1SCRCtlystIntkGsTmpPrl "Aftrtrtmnt1SCRCtlystIntkGsTmpPrlmnryFMI";
BA_ "SPN" SG_ 2499624702 Aftrtrtmnt1SCRCtlystIntkGasTemp 4360;
BA_ "SigType" SG_ 2499624702 Aftrtrtmnt1SCRCtlystIntkGasTemp 1;
BA_ "SPN" SG_ 2566733822 Aftrtrtmnt1SCRCtlystExhstGsDffPr 4359;
BA_ "SigType" SG_ 2566733822 Aftrtrtmnt1SCRCtlystExhstGsDffPr 4;
BA_ "SystemSignalLongSymbol" SG_ 2566733822 Aftrtrtmnt1SCRCtlystExhstGsDffPr "Aftrtrtmnt1SCRCtlystExhstGsDffPrssPrlmnryFMI";
BA_ "SPN" SG_ 2566733822 Aftrtrtmnt1SCRCtlystExhstGs_0000 4358;
BA_ "SigType" SG_ 2566733822 Aftrtrtmnt1SCRCtlystExhstGs_0000 1;
BA_ "SystemSignalLongSymbol" SG_ 2566733822 Aftrtrtmnt1SCRCtlystExhstGs_0000 "Aftrtrtmnt1SCRCtlystExhstGsDffPrss";
BA_ "SPN" SG_ 2566734078 Aftrtrtmnt1SCRCtlystTnk2HterCmd 5414;
BA_ "SigType" SG_ 2566734078 Aftrtrtmnt1SCRCtlystTnk2HterCmd 1;
BA_ "SPN" SG_ 2566734078 Aftrtrtmnt1SCRCtlystTnkHaterCmd 5137;
BA_ "SigType" SG_ 2566734078 Aftrtrtmnt1SCRCtlystTnkHaterCmd 1;
BA_ "SPN" SG_ 2566734078 Aftrtrtmnt1SCRCtlystRgntLnHter4 4357;
BA_ "SigType" SG_ 2566734078 Aftrtrtmnt1SCRCtlystRgntLnHter4 4;
BA_ "SPN" SG_ 2566734078 Aftrtrtmnt1SCRCtlystRgntLnHter3 4356;
BA_ "SigType" SG_ 2566734078 Aftrtrtmnt1SCRCtlystRgntLnHter3 4;
BA_ "SPN" SG_ 2566734078 Aftrtrtmnt1SCRCtlystRgntLnHter2 4355;
BA_ "SigType" SG_ 2566734078 Aftrtrtmnt1SCRCtlystRgntLnHter2 4;
BA_ "SPN" SG_ 2566734078 Aftrtrtmnt1SCRCtlystRgntLnHter1 4354;
BA_ "SigType" SG_ 2566734078 Aftrtrtmnt1SCRCtlystRgntLnHter1 4;
BA_ "SPN" SG_ 2566734078 Aftrtrtmnt1SCRDserHeatingModeRq 4353;
BA_ "SigType" SG_ 2566734078 Aftrtrtmnt1SCRDserHeatingModeRq 4;
BA_ "SPN" SG_ 2566734078 Aftrtrtmnt1SCRDsrFltSpprssionRq 4352;
BA_ "SigType" SG_ 2566734078 Aftrtrtmnt1SCRDsrFltSpprssionRq 4;
BA_ "SPN" SG_ 2364548350 Aftrtrtmnt1SCRRqdRgntQnttyFrIntg 4350;
BA_ "SigType" SG_ 2364548350 Aftrtrtmnt1SCRRqdRgntQnttyFrIntg 1;
BA_ "SystemSignalLongSymbol" SG_ 2364548350 Aftrtrtmnt1SCRRqdRgntQnttyFrIntg "Aftrtrtmnt1SCRRqdRgntQnttyFrIntgrtr";
BA_ "SPN" SG_ 2364548350 Aftrtratment1SCRSystemRqedState 4349;
BA_ "SigType" SG_ 2364548350 Aftrtratment1SCRSystemRqedState 4;
BA_ "SPN" SG_ 2364548350 Aftrtrtmnt1SCRRqdDsngRgntQntity 4348;
BA_ "SigType" SG_ 2364548350 Aftrtrtmnt1SCRRqdDsngRgntQntity 1;
BA_ "SPN" SG_ 2566734334 Aftrtrtmnt1SCRCtlystRgntLnHtr4Pr 4347;
BA_ "SigType" SG_ 2566734334 Aftrtrtmnt1SCRCtlystRgntLnHtr4Pr 1;
BA_ "SystemSignalLongSymbol" SG_ 2566734334 Aftrtrtmnt1SCRCtlystRgntLnHtr4Pr "Aftrtrtmnt1SCRCtlystRgntLnHtr4PrlmnryFMI";
BA_ "SPN" SG_ 2566734334 Aftrtrtmnt1SCRCtlystRgntLnHtr4St 4346;
BA_ "SigType" SG_ 2566734334 Aftrtrtmnt1SCRCtlystRgntLnHtr4St 4;
BA_ "SystemSignalLongSymbol" SG_ 2566734334 Aftrtrtmnt1SCRCtlystRgntLnHtr4St "Aftrtrtmnt1SCRCtlystRgntLnHtr4Stt";
BA_ "SPN" SG_ 2566734334 Aftrtrtmnt1SCRCtlystRgntLnHtr3Pr 4345;
BA_ "SigType" SG_ 2566734334 Aftrtrtmnt1SCRCtlystRgntLnHtr3Pr 1;
BA_ "SystemSignalLongSymbol" SG_ 2566734334 Aftrtrtmnt1SCRCtlystRgntLnHtr3Pr "Aftrtrtmnt1SCRCtlystRgntLnHtr3PrlmnryFMI";
BA_ "SPN" SG_ 2566734334 Aftrtrtmnt1SCRCtlystRgntLnHtr3St 4344;
BA_ "SigType" SG_ 2566734334 Aftrtrtmnt1SCRCtlystRgntLnHtr3St 4;
BA_ "SystemSignalLongSymbol" SG_ 2566734334 Aftrtrtmnt1SCRCtlystRgntLnHtr3St "Aftrtrtmnt1SCRCtlystRgntLnHtr3Stt";
BA_ "SPN" SG_ 2566734334 Aftrtrtmnt1SCRCtlystRgntLnHtr2Pr 4343;
BA_ "SigType" SG_ 2566734334 Aftrtrtmnt1SCRCtlystRgntLnHtr2Pr 1;
BA_ "SystemSignalLongSymbol" SG_ 2566734334 Aftrtrtmnt1SCRCtlystRgntLnHtr2Pr "Aftrtrtmnt1SCRCtlystRgntLnHtr2PrlmnryFMI";
BA_ "SPN" SG_ 2566734334 Aftrtrtmnt1SCRCtlystRgntLnHtr2St 4342;
BA_ "SigType" SG_ 2566734334 Aftrtrtmnt1SCRCtlystRgntLnHtr2St 4;
BA_ "SystemSignalLongSymbol" SG_ 2566734334 Aftrtrtmnt1SCRCtlystRgntLnHtr2St "Aftrtrtmnt1SCRCtlystRgntLnHtr2Stt";
BA_ "SPN" SG_ 2566734334 Aftrtrtmnt1SCRCtlystRgntLnHtr1Pr 4341;
BA_ "SigType" SG_ 2566734334 Aftrtrtmnt1SCRCtlystRgntLnHtr1Pr 1;
BA_ "SystemSignalLongSymbol" SG_ 2566734334 Aftrtrtmnt1SCRCtlystRgntLnHtr1Pr "Aftrtrtmnt1SCRCtlystRgntLnHtr1PrlmnryFMI";
BA_ "SPN" SG_ 2566734334 Aftrtrtmnt1SCRCtlystRgntLnHtr1St 4340;
BA_ "SigType" SG_ 2566734334 Aftrtrtmnt1SCRCtlystRgntLnHtr1St 4;
BA_ "SystemSignalLongSymbol" SG_ 2566734334 Aftrtrtmnt1SCRCtlystRgntLnHtr1St "Aftrtrtmnt1SCRCtlystRgntLnHtr1Stt";
BA_ "SPN" SG_ 2566734334 Aftrtrtmnt1SCRFedbackCtrlStatus 4339;
BA_ "SigType" SG_ 2566734334 Aftrtrtmnt1SCRFedbackCtrlStatus 4;
BA_ "SPN" SG_ 2566734334 Aftrtrtmnt1SCRDsngVlvExhstTmpRdc 4338;
BA_ "SigType" SG_ 2566734334 Aftrtrtmnt1SCRDsngVlvExhstTmpRdc 4;
BA_ "SystemSignalLongSymbol" SG_ 2566734334 Aftrtrtmnt1SCRDsngVlvExhstTmpRdc "Aftrtrtmnt1SCRDsngVlvExhstTmpRdctnRq";
BA_ "SPN" SG_ 2566734334 Aftrtrtmnt1SCRDosingReagentTemp 4337;
BA_ "SigType" SG_ 2566734334 Aftrtrtmnt1SCRDosingReagentTemp 1;
BA_ "SPN" SG_ 2566734334 Aftrtrtmnt1SCRDsngArAssistValve 4336;
BA_ "SigType" SG_ 2566734334 Aftrtrtmnt1SCRDsngArAssistValve 1;
BA_ "SPN" SG_ 2566734334 Aftrtrtmnt1SCRDsngArAssstAbsPrss 4335;
BA_ "SigType" SG_ 2566734334 Aftrtrtmnt1SCRDsngArAssstAbsPrss 1;
BA_ "SPN" SG_ 2364548094 Aftrtrtmnt1SCRDsngRgentAbsPress 4334;
BA_ "SigType" SG_ 2364548094 Aftrtrtmnt1SCRDsngRgentAbsPress 1;
BA_ "SPN" SG_ 2364548094 Aftrtrtmnt1SCRActlRgntQnttyOfInt 4333;
BA_ "SigType" SG_ 2364548094 Aftrtrtmnt1SCRActlRgntQnttyOfInt 1;
BA_ "SystemSignalLongSymbol" SG_ 2364548094 Aftrtrtmnt1SCRActlRgntQnttyOfInt "Aftrtrtmnt1SCRActlRgntQnttyOfIntgrtr";
BA_ "SPN" SG_ 2364548094 Aftertreatment1SCRSystemState 4332;
BA_ "SigType" SG_ 2364548094 Aftertreatment1SCRSystemState 4;
BA_ "SPN" SG_ 2364548094 Aftrtrtmnt1SCRActlDsngRgntQntty 4331;
BA_ "SigType" SG_ 2364548094 Aftrtrtmnt1SCRActlDsngRgntQntty 1;
BA_ "SPN" SG_ 2364548606 Aftrtrtmnt1OtltNH3GsSnsrHtrCtrl 4383;
BA_ "SigType" SG_ 2364548606 Aftrtrtmnt1OtltNH3GsSnsrHtrCtrl 4;
BA_ "SPN" SG_ 2364548606 Aftrtrtmnt1OtltNH3GsSnsrHtrPrlmn 4382;
BA_ "SigType" SG_ 2364548606 Aftrtrtmnt1OtltNH3GsSnsrHtrPrlmn 1;
BA_ "SystemSignalLongSymbol" SG_ 2364548606 Aftrtrtmnt1OtltNH3GsSnsrHtrPrlmn "Aftrtrtmnt1OtltNH3GsSnsrHtrPrlmnryFMI";
BA_ "SPN" SG_ 2364548606 Aftrtrtmnt1OtltNH3GsSnsorAtTemp 4381;
BA_ "SigType" SG_ 2364548606 Aftrtrtmnt1OtltNH3GsSnsorAtTemp 4;
BA_ "SPN" SG_ 2364548606 Aftrtrtmnt1OtltNH3GsSnsrPwrInRng 4380;
BA_ "SigType" SG_ 2364548606 Aftrtrtmnt1OtltNH3GsSnsrPwrInRng 4;
BA_ "SPN" SG_ 2364548606 Aftrtrtmnt1OtltNH3ReadingStable 4379;
BA_ "SigType" SG_ 2364548606 Aftrtrtmnt1OtltNH3ReadingStable 4;
BA_ "SPN" SG_ 2364548606 Aftrtrtmnt1OtltNH3SnsrPrlmnryFMI 4378;
BA_ "SigType" SG_ 2364548606 Aftrtrtmnt1OtltNH3SnsrPrlmnryFMI 1;
BA_ "SPN" SG_ 2364548606 Aftertreatment1OutletNH3 4377;
BA_ "SigType" SG_ 2364548606 Aftertreatment1OutletNH3 1;
BA_ "SPN" SG_ 2566726398 Aftrtrtmnt1GsOxdtnCtlystDffPrssP 4758;
BA_ "SigType" SG_ 2566726398 Aftrtrtmnt1GsOxdtnCtlystDffPrssP 1;
BA_ "SystemSignalLongSymbol" SG_ 2566726398 Aftrtrtmnt1GsOxdtnCtlystDffPrssP "Aftrtrtmnt1GsOxdtnCtlystDffPrssPrlmnryFMI";
BA_ "SPN" SG_ 2566726398 Aftrtrtmnt1GsOxdtnCtlystOtltGsTm 4757;
BA_ "SigType" SG_ 2566726398 Aftrtrtmnt1GsOxdtnCtlystOtltGsTm 1;
BA_ "SystemSignalLongSymbol" SG_ 2566726398 Aftrtrtmnt1GsOxdtnCtlystOtltGsTm "Aftrtrtmnt1GsOxdtnCtlystOtltGsTmpPrlmnryFMI";
BA_ "SPN" SG_ 2566726398 Aftrtrtmnt1GsOxdtnCtlystIntkGsTm 4756;
BA_ "SigType" SG_ 2566726398 Aftrtrtmnt1GsOxdtnCtlystIntkGsTm 1;
BA_ "SystemSignalLongSymbol" SG_ 2566726398 Aftrtrtmnt1GsOxdtnCtlystIntkGsTm "Aftrtrtmnt1GsOxdtnCtlystIntkGsTmpPrlmnryFMI";
BA_ "SPN" SG_ 2566726398 Aftrtrtmnt1GsOxdtnCtlystDffPrss 4755;
BA_ "SigType" SG_ 2566726398 Aftrtrtmnt1GsOxdtnCtlystDffPrss 1;
BA_ "SPN" SG_ 2566726398 Aftrtrtmnt1GsOxdtnCtlystOtl_0000 4754;
BA_ "SigType" SG_ 2566726398 Aftrtrtmnt1GsOxdtnCtlystOtl_0000 1;
BA_ "SystemSignalLongSymbol" SG_ 2566726398 Aftrtrtmnt1GsOxdtnCtlystOtl_0000 "Aftrtrtmnt1GsOxdtnCtlystOtltGsTmp";
BA_ "SPN" SG_ 2566726398 Aftrtrtmnt1GsOxdtnCtlystInt_0000 4753;
BA_ "SigType" SG_ 2566726398 Aftrtrtmnt1GsOxdtnCtlystInt_0000 1;
BA_ "SystemSignalLongSymbol" SG_ 2566726398 Aftrtrtmnt1GsOxdtnCtlystInt_0000 "Aftrtrtmnt1GsOxdtnCtlystIntkGsTmp";
BA_ "SPN" SG_ 2566742270 FailureSpecificB1Counter 4147;
BA_ "SigType" SG_ 2566742270 FailureSpecificB1Counter 1;
BA_ "SPN" SG_ 2566742270 FailureModeIdentifier1 1215;
BA_ "SPN" SG_ 2566742270 SPN1High 1214;
BA_ "SPN" SG_ 2566742270 SPN1 1214;
BA_ "SPN" SG_ 2566742526 SysGreatestB1Counter 4146;
BA_ "SigType" SG_ 2566742526 SysGreatestB1Counter 1;
BA_ "SPN" SG_ 2566742526 SysCumulativeContinuousMITime 4145;
BA_ "SigType" SG_ 2566742526 SysCumulativeContinuousMITime 1;
BA_ "SPN" SG_ 2566742782 RegulationDescription 4144;
BA_ "SigType" SG_ 2566742782 RegulationDescription 8;
BA_ "SPN" SG_ 2566743038 SysIncompleteMonitorCount 4143;
BA_ "SigType" SG_ 2566743038 SysIncompleteMonitorCount 1;
BA_ "SPN" SG_ 2566743038 SysMalIndActivationMode 4142;
BA_ "SPN" SG_ 2566743038 SysMalIndDisplayStrategy 4141;
BA_ "SigType" SG_ 2566743038 SysMalIndDisplayStrategy 4;
BA_ "SPN" SG_ 2566743038 SysContinuousMalfunctionInd 4140;
BA_ "SigType" SG_ 2566743038 SysContinuousMalfunctionInd 4;
BA_ "SPN" SG_ 2566743038 SysNonRoadworthyCompCount 4139;
BA_ "SigType" SG_ 2566743038 SysNonRoadworthyCompCount 1;
BA_ "SPN" SG_ 2566743294 VehicleCurrentMIAccumTime 4138;
BA_ "SigType" SG_ 2566743294 VehicleCurrentMIAccumTime 1;
BA_ "SPN" SG_ 2566743294 VehicleIncompleteMonitorCount 4137;
BA_ "SigType" SG_ 2566743294 VehicleIncompleteMonitorCount 1;
BA_ "SPN" SG_ 2566743294 VehicleMalfunctionIndActMode 4136;
BA_ "SigType" SG_ 2566743294 VehicleMalfunctionIndActMode 4;
BA_ "SPN" SG_ 2566743294 VehicleMalfunctionIndStrategy 4135;
BA_ "SigType" SG_ 2566743294 VehicleMalfunctionIndStrategy 4;
BA_ "SPN" SG_ 2566743294 VehicleContinuousMalfunctionInd 4134;
BA_ "SigType" SG_ 2566743294 VehicleContinuousMalfunctionInd 4;
BA_ "SPN" SG_ 2566743294 VehicleNonRoadworthyCompCount 4133;
BA_ "SigType" SG_ 2566743294 VehicleNonRoadworthyCompCount 1;
BA_ "SPN" SG_ 2560687870 PMNTEDeficiencyAreaStatus 4132;
BA_ "SigType" SG_ 2560687870 PMNTEDeficiencyAreaStatus 4;
BA_ "SPN" SG_ 2560687870 MnfcPMNTECarveOutAreaStatus 4131;
BA_ "SigType" SG_ 2560687870 MnfcPMNTECarveOutAreaStatus 4;
BA_ "SPN" SG_ 2560687870 PMNTEControlAreaStatus 4130;
BA_ "SigType" SG_ 2560687870 PMNTEControlAreaStatus 4;
BA_ "SPN" SG_ 2560687870 NOxNTEDeficiencyAreaStatus 4129;
BA_ "SigType" SG_ 2560687870 NOxNTEDeficiencyAreaStatus 4;
BA_ "SPN" SG_ 2560687870 MnfcNOxNTECarveOutAreaStatus 4128;
BA_ "SigType" SG_ 2560687870 MnfcNOxNTECarveOutAreaStatus 4;
BA_ "SPN" SG_ 2560687870 NOxNTEControlAreaStatus 4127;
BA_ "SigType" SG_ 2560687870 NOxNTEControlAreaStatus 4;
BA_ "SPN" SG_ 2292317950 AECDEngineHours1Timer2 4126;
BA_ "SigType" SG_ 2292317950 AECDEngineHours1Timer2 1;
BA_ "SPN" SG_ 2292317950 AECDEngineHours1Timer1 4125;
BA_ "SigType" SG_ 2292317950 AECDEngineHours1Timer1 1;
BA_ "SPN" SG_ 2292317950 AECDNumber1 4124;
BA_ "SigType" SG_ 2292317950 AECDNumber1 1;
BA_ "SPN" SG_ 2566809342 BatteryMainSwitchHoldState 1681;
BA_ "SigType" SG_ 2566809342 BatteryMainSwitchHoldState 4;
BA_ "SPN" SG_ 2365446910 Joystick3XAxisDetentPosStatus 2754;
BA_ "SigType" SG_ 2365446910 Joystick3XAxisDetentPosStatus 4;
BA_ "SPN" SG_ 2365446910 Joystick3Button9PressedStatus 2767;
BA_ "SigType" SG_ 2365446910 Joystick3Button9PressedStatus 4;
BA_ "SPN" SG_ 2365446910 Joystick3Button10PressedStatus 2768;
BA_ "SigType" SG_ 2365446910 Joystick3Button10PressedStatus 4;
BA_ "SPN" SG_ 2365446910 Joystick3Button11PressedStatus 2769;
BA_ "SigType" SG_ 2365446910 Joystick3Button11PressedStatus 4;
BA_ "SPN" SG_ 2365446910 Joystick3Button12PressedStatus 2770;
BA_ "SigType" SG_ 2365446910 Joystick3Button12PressedStatus 4;
BA_ "SPN" SG_ 2365446910 Joystick3YAxisDetentPosStatus 2755;
BA_ "SigType" SG_ 2365446910 Joystick3YAxisDetentPosStatus 4;
BA_ "SPN" SG_ 2365446910 Joystick3YAxisPos 2735;
BA_ "SigType" SG_ 2365446910 Joystick3YAxisPos 1;
BA_ "SPN" SG_ 2365446910 Jystck3YAxsLvrFrwrdPstvPsStatus 2740;
BA_ "SigType" SG_ 2365446910 Jystck3YAxsLvrFrwrdPstvPsStatus 4;
BA_ "SPN" SG_ 2365446910 Jystck3YAxsLvrBckNgtvePosStatus 2745;
BA_ "SigType" SG_ 2365446910 Jystck3YAxsLvrBckNgtvePosStatus 4;
BA_ "SPN" SG_ 2365446910 Joystick3YAxisNeutralPosStatus 2750;
BA_ "SigType" SG_ 2365446910 Joystick3YAxisNeutralPosStatus 4;
BA_ "SPN" SG_ 2365446910 Joystick3XAxisPos 2734;
BA_ "SigType" SG_ 2365446910 Joystick3XAxisPos 1;
BA_ "SPN" SG_ 2365446910 Jystck3XAxsLvrRghtPstvPosStatus 2739;
BA_ "SigType" SG_ 2365446910 Jystck3XAxsLvrRghtPstvPosStatus 4;
BA_ "SPN" SG_ 2365446910 Jystck3XAxsLvrLftNgtvePosStatus 2744;
BA_ "SigType" SG_ 2365446910 Jystck3XAxsLvrLftNgtvePosStatus 4;
BA_ "SPN" SG_ 2365446910 Joystick3XAxisNeutralPosStatus 2749;
BA_ "SigType" SG_ 2365446910 Joystick3XAxisNeutralPosStatus 4;
BA_ "SPN" SG_ 2365446910 Joystick3Button5PressedStatus 2763;
BA_ "SigType" SG_ 2365446910 Joystick3Button5PressedStatus 4;
BA_ "SPN" SG_ 2365446910 Joystick3Button6PressedStatus 2764;
BA_ "SigType" SG_ 2365446910 Joystick3Button6PressedStatus 4;
BA_ "SPN" SG_ 2365446910 Joystick3Button7PressedStatus 2765;
BA_ "SigType" SG_ 2365446910 Joystick3Button7PressedStatus 4;
BA_ "SPN" SG_ 2365446910 Joystick3Button8PressedStatus 2766;
BA_ "SigType" SG_ 2365446910 Joystick3Button8PressedStatus 4;
BA_ "SPN" SG_ 2365446910 Joystick3Button1PressedStatus 2759;
BA_ "SigType" SG_ 2365446910 Joystick3Button1PressedStatus 4;
BA_ "SPN" SG_ 2365446910 Joystick3Button2PressedStatus 2760;
BA_ "SigType" SG_ 2365446910 Joystick3Button2PressedStatus 4;
BA_ "SPN" SG_ 2365446910 Joystick3Button3PressedStatus 2761;
BA_ "SigType" SG_ 2365446910 Joystick3Button3PressedStatus 4;
BA_ "SPN" SG_ 2365446910 Joystick3Button4PressedStatus 2762;
BA_ "SigType" SG_ 2365446910 Joystick3Button4PressedStatus 4;
BA_ "SPN" SG_ 2365446398 Joystick2XAxisDetentPosStatus 2717;
BA_ "SigType" SG_ 2365446398 Joystick2XAxisDetentPosStatus 4;
BA_ "SPN" SG_ 2365446398 Joystick2YAxisDetentPosStatus 2718;
BA_ "SigType" SG_ 2365446398 Joystick2YAxisDetentPosStatus 4;
BA_ "SPN" SG_ 2365446398 Joystick2YAxisPos 2698;
BA_ "SigType" SG_ 2365446398 Joystick2YAxisPos 1;
BA_ "SPN" SG_ 2365446398 Jystck2YAxsLvrFrwrdPstvPsStatus 2703;
BA_ "SigType" SG_ 2365446398 Jystck2YAxsLvrFrwrdPstvPsStatus 4;
BA_ "SPN" SG_ 2365446398 Jystck2YAxsLvrBckNgtvePosStatus 2708;
BA_ "SigType" SG_ 2365446398 Jystck2YAxsLvrBckNgtvePosStatus 4;
BA_ "SPN" SG_ 2365446398 Joystick2YAxisNeutralPosStatus 2713;
BA_ "SigType" SG_ 2365446398 Joystick2YAxisNeutralPosStatus 4;
BA_ "SPN" SG_ 2365446398 Joystick2XAxisPos 2697;
BA_ "SigType" SG_ 2365446398 Joystick2XAxisPos 1;
BA_ "SPN" SG_ 2365446398 Jystck2XAxsLvrRghtPstvPosStatus 2702;
BA_ "SigType" SG_ 2365446398 Jystck2XAxsLvrRghtPstvPosStatus 4;
BA_ "SPN" SG_ 2365446398 Jystck2XAxsLvrLftNgtvePosStatus 2707;
BA_ "SigType" SG_ 2365446398 Jystck2XAxsLvrLftNgtvePosStatus 4;
BA_ "SPN" SG_ 2365446398 Joystick2XAxisNeutralPosStatus 2712;
BA_ "SigType" SG_ 2365446398 Joystick2XAxisNeutralPosStatus 4;
BA_ "SPN" SG_ 2365446398 Joystick2Button9PressedStatus 2730;
BA_ "SigType" SG_ 2365446398 Joystick2Button9PressedStatus 4;
BA_ "SPN" SG_ 2365446398 Joystick2Button10PressedStatus 2731;
BA_ "SigType" SG_ 2365446398 Joystick2Button10PressedStatus 4;
BA_ "SPN" SG_ 2365446398 Joystick2Button11PressedStatus 2732;
BA_ "SigType" SG_ 2365446398 Joystick2Button11PressedStatus 4;
BA_ "SPN" SG_ 2365446398 Joystick2Button12PressedStatus 2733;
BA_ "SigType" SG_ 2365446398 Joystick2Button12PressedStatus 4;
BA_ "SPN" SG_ 2365446398 Joystick2Button5PressedStatus 2726;
BA_ "SigType" SG_ 2365446398 Joystick2Button5PressedStatus 4;
BA_ "SPN" SG_ 2365446398 Joystick2Button6PressedStatus 2727;
BA_ "SigType" SG_ 2365446398 Joystick2Button6PressedStatus 4;
BA_ "SPN" SG_ 2365446398 Joystick2Button7PressedStatus 2728;
BA_ "SigType" SG_ 2365446398 Joystick2Button7PressedStatus 4;
BA_ "SPN" SG_ 2365446398 Joystick2Button8PressedStatus 2729;
BA_ "SigType" SG_ 2365446398 Joystick2Button8PressedStatus 4;
BA_ "SPN" SG_ 2365446398 Joystick2Button1PressedStatus 2722;
BA_ "SigType" SG_ 2365446398 Joystick2Button1PressedStatus 4;
BA_ "SPN" SG_ 2365446398 Joystick2Button2PressedStatus 2723;
BA_ "SigType" SG_ 2365446398 Joystick2Button2PressedStatus 4;
BA_ "SPN" SG_ 2365446398 Joystick2Button3PressedStatus 2724;
BA_ "SigType" SG_ 2365446398 Joystick2Button3PressedStatus 4;
BA_ "SPN" SG_ 2365446398 Joystick2Button4PressedStatus 2725;
BA_ "SigType" SG_ 2365446398 Joystick2Button4PressedStatus 4;
BA_ "SPN" SG_ 2365445886 Joystick1XAxisDetentPosStatus 2680;
BA_ "SigType" SG_ 2365445886 Joystick1XAxisDetentPosStatus 4;
BA_ "SPN" SG_ 2365445886 Joystick1YAxisDetentPosStatus 2681;
BA_ "SigType" SG_ 2365445886 Joystick1YAxisDetentPosStatus 4;
BA_ "SPN" SG_ 2365445886 Joystick1YAxisPos 2661;
BA_ "SigType" SG_ 2365445886 Joystick1YAxisPos 1;
BA_ "SPN" SG_ 2365445886 Jystck1YAxsLvrFrwrdPstvPsStatus 2666;
BA_ "SigType" SG_ 2365445886 Jystck1YAxsLvrFrwrdPstvPsStatus 4;
BA_ "SPN" SG_ 2365445886 Jystck1YAxsLvrBckNgtvePosStatus 2671;
BA_ "SigType" SG_ 2365445886 Jystck1YAxsLvrBckNgtvePosStatus 4;
BA_ "SPN" SG_ 2365445886 Joystick1YAxisNeutralPosStatus 2676;
BA_ "SigType" SG_ 2365445886 Joystick1YAxisNeutralPosStatus 4;
BA_ "SPN" SG_ 2365445886 Joystick1XAxisPos 2660;
BA_ "SigType" SG_ 2365445886 Joystick1XAxisPos 1;
BA_ "SPN" SG_ 2365445886 Joystick1Button9PressedStatus 2693;
BA_ "SigType" SG_ 2365445886 Joystick1Button9PressedStatus 4;
BA_ "SPN" SG_ 2365445886 Joystick1Button10PressedStatus 2694;
BA_ "SigType" SG_ 2365445886 Joystick1Button10PressedStatus 4;
BA_ "SPN" SG_ 2365445886 Joystick1Button11PressedStatus 2695;
BA_ "SigType" SG_ 2365445886 Joystick1Button11PressedStatus 4;
BA_ "SPN" SG_ 2365445886 Joystick1Button12PressedStatus 2696;
BA_ "SigType" SG_ 2365445886 Joystick1Button12PressedStatus 4;
BA_ "SPN" SG_ 2365445886 Joystick1Button5PressedStatus 2689;
BA_ "SigType" SG_ 2365445886 Joystick1Button5PressedStatus 4;
BA_ "SPN" SG_ 2365445886 Joystick1Button6PressedStatus 2690;
BA_ "SigType" SG_ 2365445886 Joystick1Button6PressedStatus 4;
BA_ "SPN" SG_ 2365445886 Joystick1Button7PressedStatus 2691;
BA_ "SigType" SG_ 2365445886 Joystick1Button7PressedStatus 4;
BA_ "SPN" SG_ 2365445886 Joystick1Button8PressedStatus 2692;
BA_ "SigType" SG_ 2365445886 Joystick1Button8PressedStatus 4;
BA_ "SPN" SG_ 2365445886 Joystick1Button1PressedStatus 2685;
BA_ "SigType" SG_ 2365445886 Joystick1Button1PressedStatus 4;
BA_ "SPN" SG_ 2365445886 Joystick1Button2PressedStatus 2686;
BA_ "SigType" SG_ 2365445886 Joystick1Button2PressedStatus 4;
BA_ "SPN" SG_ 2365445886 Joystick1Button3PressedStatus 2687;
BA_ "SigType" SG_ 2365445886 Joystick1Button3PressedStatus 4;
BA_ "SPN" SG_ 2365445886 Joystick1Button4PressedStatus 2688;
BA_ "SigType" SG_ 2365445886 Joystick1Button4PressedStatus 4;
BA_ "SPN" SG_ 2365445886 Jystck1XAxsLvrRghtPstvPosStatus 2665;
BA_ "SigType" SG_ 2365445886 Jystck1XAxsLvrRghtPstvPosStatus 4;
BA_ "SPN" SG_ 2365445886 Jystck1XAxsLvrLftNgtvePosStatus 2670;
BA_ "SigType" SG_ 2365445886 Jystck1XAxsLvrLftNgtvePosStatus 4;
BA_ "SPN" SG_ 2365445886 Joystick1XAxisNeutralPosStatus 2675;
BA_ "SigType" SG_ 2365445886 Joystick1XAxisNeutralPosStatus 4;
BA_ "SPN" SG_ 2566847230 ParkingBrakeRedWarningSignal 3557;
BA_ "SigType" SG_ 2566847230 ParkingBrakeRedWarningSignal 4;
BA_ "SPN" SG_ 2566847230 ParkBrakeReleaseInhibitStatus 3808;
BA_ "SigType" SG_ 2566847230 ParkBrakeReleaseInhibitStatus 4;
BA_ "SPN" SG_ 2566847230 ParkingBrakeActuator 619;
BA_ "SigType" SG_ 2566847230 ParkingBrakeActuator 4;
BA_ "SPN" SG_ 2566847230 BrakeSecondPress 118;
BA_ "SigType" SG_ 2566847230 BrakeSecondPress 1;
BA_ "SPN" SG_ 2566847230 BrakePrimaryPress 117;
BA_ "SigType" SG_ 2566847230 BrakePrimaryPress 1;
BA_ "SPN" SG_ 2566847230 BrakeAppPress 116;
BA_ "SigType" SG_ 2566847230 BrakeAppPress 1;
BA_ "SPN" SG_ 2566848254 AuxPumpPress 73;
BA_ "SigType" SG_ 2566848254 AuxPumpPress 1;
BA_ "SPN" SG_ 2566725886 Aftrtrtmnt1DslOxdtnCtlystDf_0000 4770;
BA_ "SigType" SG_ 2566725886 Aftrtrtmnt1DslOxdtnCtlystDf_0000 1;
BA_ "SystemSignalLongSymbol" SG_ 2566725886 Aftrtrtmnt1DslOxdtnCtlystDf_0000 "Aftrtrtmnt1DslOxdtnCtlystDffPrssPrlmnryFMI";
BA_ "SPN" SG_ 2566725886 Aftrtrtmnt1DslOxdtnCtlystOtltGsT 4769;
BA_ "SigType" SG_ 2566725886 Aftrtrtmnt1DslOxdtnCtlystOtltGsT 1;
BA_ "SystemSignalLongSymbol" SG_ 2566725886 Aftrtrtmnt1DslOxdtnCtlystOtltGsT "Aftrtrtmnt1DslOxdtnCtlystOtltGsTmpPrlmnryFMI";
BA_ "SPN" SG_ 2566725886 Aftrtrtmnt1DslOxdtnCtlystIntkGsT 4768;
BA_ "SigType" SG_ 2566725886 Aftrtrtmnt1DslOxdtnCtlystIntkGsT 1;
BA_ "SystemSignalLongSymbol" SG_ 2566725886 Aftrtrtmnt1DslOxdtnCtlystIntkGsT "Aftrtrtmnt1DslOxdtnCtlystIntkGsTmpPrlmnryFMI";
BA_ "SPN" SG_ 2566725886 Aftrtrtmnt1DslOxdtnCtlystDffPrss 4767;
BA_ "SigType" SG_ 2566725886 Aftrtrtmnt1DslOxdtnCtlystDffPrss 1;
BA_ "SPN" SG_ 2566725886 Aftrtrtmnt1DslOxdtnCtlystOt_0000 4766;
BA_ "SigType" SG_ 2566725886 Aftrtrtmnt1DslOxdtnCtlystOt_0000 1;
BA_ "SystemSignalLongSymbol" SG_ 2566725886 Aftrtrtmnt1DslOxdtnCtlystOt_0000 "Aftrtrtmnt1DslOxdtnCtlystOtltGsTmp";
BA_ "SPN" SG_ 2566725886 Aftrtrtmnt1DslOxdtnCtlystIn_0000 4765;
BA_ "SigType" SG_ 2566725886 Aftrtrtmnt1DslOxdtnCtlystIn_0000 1;
BA_ "SystemSignalLongSymbol" SG_ 2566725886 Aftrtrtmnt1DslOxdtnCtlystIn_0000 "Aftrtrtmnt1DslOxdtnCtlystIntkGsTmp";
BA_ "SPN" SG_ 2560884478 DTCWarnLampSupportStatus 4115;
BA_ "SigType" SG_ 2560884478 DTCWarnLampSupportStatus 4;
BA_ "SPN" SG_ 2560884478 DTCWarnLampSupportFlash 4119;
BA_ "SigType" SG_ 2560884478 DTCWarnLampSupportFlash 4;
BA_ "SPN" SG_ 2560884478 DTCStopLampSupportStatus 4114;
BA_ "SigType" SG_ 2560884478 DTCStopLampSupportStatus 4;
BA_ "SPN" SG_ 2560884478 DTCStopLampSupportFlash 4118;
BA_ "SigType" SG_ 2560884478 DTCStopLampSupportFlash 4;
BA_ "SPN" SG_ 2560884478 DTCProtectLampSupportStatus 4116;
BA_ "SigType" SG_ 2560884478 DTCProtectLampSupportStatus 4;
BA_ "SPN" SG_ 2560884478 DTCProtectLampSupportFlash 4120;
BA_ "SigType" SG_ 2560884478 DTCProtectLampSupportFlash 4;
BA_ "SPN" SG_ 2560884478 DTCMilSupportStatus 4113;
BA_ "SPN" SG_ 2560884478 DTCMilSupportFlash 4117;
BA_ "SigType" SG_ 2560884478 DTC1 7;
BA_ "SPN" SG_ 2560360190 DataDictionaryMethod 4181;
BA_ "SPN" SG_ 2560360190 DataDictionaryManufacturerCode 4180;
BA_ "SPN" SG_ 2566736126 ShorttermFuelTrimBank2 4238;
BA_ "SigType" SG_ 2566736126 ShorttermFuelTrimBank2 1;
BA_ "SPN" SG_ 2566736126 LongtermFuelTrimBank2 4239;
BA_ "SigType" SG_ 2566736126 LongtermFuelTrimBank2 1;
BA_ "SPN" SG_ 2566736126 EngExhstGsOxygnSnsrClsdLpOprtnBn 4241;
BA_ "SigType" SG_ 2566736126 EngExhstGsOxygnSnsrClsdLpOprtnBn 4;
BA_ "SystemSignalLongSymbol" SG_ 2566736126 EngExhstGsOxygnSnsrClsdLpOprtnBn "EngExhstGsOxygnSnsrClsdLpOprtnBnk2";
BA_ "SPN" SG_ 2566736382 ShorttermFuelTrimBank1 4236;
BA_ "SigType" SG_ 2566736382 ShorttermFuelTrimBank1 1;
BA_ "SPN" SG_ 2566736382 LongtermFuelTrimBank1 4237;
BA_ "SigType" SG_ 2566736382 LongtermFuelTrimBank1 1;
BA_ "SPN" SG_ 2566736382 EngExhstGsOxygnSnsrClsdLpOp_0000 4240;
BA_ "SigType" SG_ 2566736382 EngExhstGsOxygnSnsrClsdLpOp_0000 4;
BA_ "SystemSignalLongSymbol" SG_ 2566736382 EngExhstGsOxygnSnsrClsdLpOp_0000 "EngExhstGsOxygnSnsrClsdLpOprtnBnk1";
BA_ "SPN" SG_ 2565874174 EngSpdSnsor1TimingPatternStatus 4203;
BA_ "SigType" SG_ 2565874174 EngSpdSnsor1TimingPatternStatus 4;
BA_ "SPN" SG_ 2565874174 EngSpdSnsor2TimingPatternStatus 4204;
BA_ "SigType" SG_ 2565874174 EngSpdSnsor2TimingPatternStatus 4;
BA_ "SPN" SG_ 2565874174 EngSpdSnsor3TimingPatternStatus 4205;
BA_ "SigType" SG_ 2565874174 EngSpdSnsor3TimingPatternStatus 4;
BA_ "SPN" SG_ 2565874174 EngSpeed3 4202;
BA_ "SigType" SG_ 2565874174 EngSpeed3 1;
BA_ "SPN" SG_ 2565874174 EngSpeed2 723;
BA_ "SigType" SG_ 2565874174 EngSpeed2 1;
BA_ "SPN" SG_ 2565874174 EngSpeed1 4201;
BA_ "SigType" SG_ 2565874174 EngSpeed1 1;
BA_ "SPN" SG_ 2432520958 DsrdEngCoolantThermostatOpening 4197;
BA_ "SigType" SG_ 2432520958 DsrdEngCoolantThermostatOpening 1;
BA_ "SPN" SG_ 2432520958 DesiredEngCoolantPumpOutletTemp 4196;
BA_ "SigType" SG_ 2432520958 DesiredEngCoolantPumpOutletTemp 1;
BA_ "SPN" SG_ 2432520958 EngCoolantThermostatMode 4195;
BA_ "SigType" SG_ 2432520958 EngCoolantThermostatMode 4;
BA_ "SPN" SG_ 2560425726 AuxI_OChannel19 4174;
BA_ "SigType" SG_ 2560425726 AuxI_OChannel19 1;
BA_ "SPN" SG_ 2560425726 AuxI_OChannel20 4173;
BA_ "SigType" SG_ 2560425726 AuxI_OChannel20 1;
BA_ "SPN" SG_ 2560425726 AuxI_OChannel21 4172;
BA_ "SigType" SG_ 2560425726 AuxI_OChannel21 1;
BA_ "SPN" SG_ 2560425726 AuxI_OChannel22 4171;
BA_ "SigType" SG_ 2560425726 AuxI_OChannel22 1;
BA_ "SPN" SG_ 2560425726 AuxI_OChannel15 4170;
BA_ "SigType" SG_ 2560425726 AuxI_OChannel15 1;
BA_ "SPN" SG_ 2560425726 AuxI_OChannel16 4169;
BA_ "SigType" SG_ 2560425726 AuxI_OChannel16 1;
BA_ "SPN" SG_ 2560425726 AuxI_OChannel17 4168;
BA_ "SigType" SG_ 2560425726 AuxI_OChannel17 1;
BA_ "SPN" SG_ 2560425726 AuxI_OChannel18 4167;
BA_ "SigType" SG_ 2560425726 AuxI_OChannel18 1;
BA_ "SPN" SG_ 2560491262 AuxI_OChannel11 4166;
BA_ "SigType" SG_ 2560491262 AuxI_OChannel11 1;
BA_ "SPN" SG_ 2560491262 AuxI_OChannel12 4165;
BA_ "SigType" SG_ 2560491262 AuxI_OChannel12 1;
BA_ "SPN" SG_ 2560491262 AuxI_OChannel13 4164;
BA_ "SigType" SG_ 2560491262 AuxI_OChannel13 1;
BA_ "SPN" SG_ 2560491262 AuxI_OChannel14 4163;
BA_ "SigType" SG_ 2560491262 AuxI_OChannel14 1;
BA_ "SPN" SG_ 2560491262 AuxI_OChannel7 4162;
BA_ "SigType" SG_ 2560491262 AuxI_OChannel7 1;
BA_ "SPN" SG_ 2560491262 AuxI_OChannel8 4161;
BA_ "SigType" SG_ 2560491262 AuxI_OChannel8 1;
BA_ "SPN" SG_ 2560491262 AuxI_OChannel9 4160;
BA_ "SigType" SG_ 2560491262 AuxI_OChannel9 1;
BA_ "SPN" SG_ 2560491262 AuxI_OChannel10 4159;
BA_ "SigType" SG_ 2560491262 AuxI_OChannel10 1;
BA_ "SPN" SG_ 2349399806 AuxI_OChannel3 4158;
BA_ "SigType" SG_ 2349399806 AuxI_OChannel3 1;
BA_ "SPN" SG_ 2349399806 AuxI_OChannel4 4157;
BA_ "SigType" SG_ 2349399806 AuxI_OChannel4 1;
BA_ "SPN" SG_ 2349399806 AuxI_OChannel5 4156;
BA_ "SigType" SG_ 2349399806 AuxI_OChannel5 1;
BA_ "SPN" SG_ 2349399806 AuxI_OChannel6 4155;
BA_ "SigType" SG_ 2349399806 AuxI_OChannel6 1;
BA_ "SPN" SG_ 2566758398 Aftrtreatment1AirEnableActuator 3489;
BA_ "SigType" SG_ 2566758398 Aftrtreatment1AirEnableActuator 4;
BA_ "SPN" SG_ 2566758398 Aftertreatment1PurgeAirActuator 3490;
BA_ "SigType" SG_ 2566758398 Aftertreatment1PurgeAirActuator 4;
BA_ "SPN" SG_ 2566758398 Aftrtrtmnt1AtmzationAirActuator 3491;
BA_ "SigType" SG_ 2566758398 Aftrtrtmnt1AtmzationAirActuator 4;
BA_ "SPN" SG_ 2566758398 Aftertreatment1AirSystemRelay 3492;
BA_ "SigType" SG_ 2566758398 Aftertreatment1AirSystemRelay 4;
BA_ "SPN" SG_ 2566758398 Aftrtrtment1AirPressActuatorPos 3488;
BA_ "SigType" SG_ 2566758398 Aftrtrtment1AirPressActuatorPos 1;
BA_ "SPN" SG_ 2566758398 Aftertreatment1AirPressCtrl 3487;
BA_ "SigType" SG_ 2566758398 Aftertreatment1AirPressCtrl 1;
BA_ "SPN" SG_ 2566758398 Aftertreatment1PurgeAirPress 3486;
BA_ "SigType" SG_ 2566758398 Aftertreatment1PurgeAirPress 1;
BA_ "SPN" SG_ 2566758398 Aftertreatment1SupplyAirPress 3485;
BA_ "SigType" SG_ 2566758398 Aftertreatment1SupplyAirPress 1;
BA_ "SPN" SG_ 2566745598 Aftertreatment1SecondAirPress 3837;
BA_ "SigType" SG_ 2566745598 Aftertreatment1SecondAirPress 1;
BA_ "SPN" SG_ 2566745598 Aftrtreatment1SecondAirMassFlow 3832;
BA_ "SigType" SG_ 2566745598 Aftrtreatment1SecondAirMassFlow 1;
BA_ "SPN" SG_ 2566745598 Aftertreatment1SecondAirTemp 3831;
BA_ "SigType" SG_ 2566745598 Aftertreatment1SecondAirTemp 1;
BA_ "SPN" SG_ 2566745598 Aftrtratment1SecondAirDiffPress 3830;
BA_ "SigType" SG_ 2566745598 Aftrtratment1SecondAirDiffPress 1;
BA_ "SPN" SG_ 2566758910 Aftrtrtmnt1FlInjctor1HeaterCtrl 4301;
BA_ "SigType" SG_ 2566758910 Aftrtrtmnt1FlInjctor1HeaterCtrl 1;
BA_ "SPN" SG_ 2566758910 Aftertreatment1FuelPress1Ctrl 3479;
BA_ "SigType" SG_ 2566758910 Aftertreatment1FuelPress1Ctrl 1;
BA_ "SPN" SG_ 2566758910 Aftrtratment1FuelEnableActuator 3482;
BA_ "SigType" SG_ 2566758910 Aftrtratment1FuelEnableActuator 4;
BA_ "SPN" SG_ 2566758910 Aftrtratment1RegenerationStatus 3483;
BA_ "SigType" SG_ 2566758910 Aftrtratment1RegenerationStatus 4;
BA_ "SPN" SG_ 2566758910 Aftertreatment1Ignt 3484;
BA_ "SigType" SG_ 2566758910 Aftertreatment1Ignt 4;
BA_ "SPN" SG_ 2566758910 Aftrtreatment1FuelDrainActuator 4097;
BA_ "SigType" SG_ 2566758910 Aftrtreatment1FuelDrainActuator 4;
BA_ "SPN" SG_ 2566758910 Aftertreatment1FuelRate 3481;
BA_ "SigType" SG_ 2566758910 Aftertreatment1FuelRate 1;
BA_ "SPN" SG_ 2566758910 Aftertreatment1FuelPress1 3480;
BA_ "SigType" SG_ 2566758910 Aftertreatment1FuelPress1 1;
BA_ "SPN" SG_ 2566743550 Aftrtrtmnt1HydrcrbnDsrIntkFlTmp 5456;
BA_ "SigType" SG_ 2566743550 Aftrtrtmnt1HydrcrbnDsrIntkFlTmp 1;
BA_ "SPN" SG_ 2566743550 Aftrtrtmnt1FlPress2ActuatorCtrl 5425;
BA_ "SigType" SG_ 2566743550 Aftrtrtmnt1FlPress2ActuatorCtrl 1;
BA_ "SPN" SG_ 2566743550 Aftrtrtmnt1FlFlwDvrterValveCtrl 5424;
BA_ "SigType" SG_ 2566743550 Aftrtrtmnt1FlFlwDvrterValveCtrl 4;
BA_ "SPN" SG_ 2566743550 Aftrtreatment1FuelPumpRelayCtrl 5423;
BA_ "SigType" SG_ 2566743550 Aftrtreatment1FuelPumpRelayCtrl 4;
BA_ "SPN" SG_ 2566743550 Aftertreatment1FuelPress2 4077;
BA_ "SigType" SG_ 2566743550 Aftertreatment1FuelPress2 1;
BA_ "SPN" SG_ 2566753534 DslPrticulateFilterOutletPress1 3610;
BA_ "SigType" SG_ 2566753534 DslPrticulateFilterOutletPress1 1;
BA_ "SPN" SG_ 2566753534 DslPrticulateFilterIntakePress1 3609;
BA_ "SigType" SG_ 2566753534 DslPrticulateFilterIntakePress1 1;
BA_ "SPN" SG_ 2566756606 Aftrtrtmnt1TtlNmbrOfActvRgnrtnMn 3728;
BA_ "SigType" SG_ 2566756606 Aftrtrtmnt1TtlNmbrOfActvRgnrtnMn 1;
BA_ "SystemSignalLongSymbol" SG_ 2566756606 Aftrtrtmnt1TtlNmbrOfActvRgnrtnMn "Aftrtrtmnt1TtlNmbrOfActvRgnrtnMnlRqs";
BA_ "SPN" SG_ 2566756606 Aftrtrtmnt1TtlNmbrOfActvRgnrtnIn 3727;
BA_ "SigType" SG_ 2566756606 Aftrtrtmnt1TtlNmbrOfActvRgnrtnIn 1;
BA_ "SystemSignalLongSymbol" SG_ 2566756606 Aftrtrtmnt1TtlNmbrOfActvRgnrtnIn "Aftrtrtmnt1TtlNmbrOfActvRgnrtnInhbtRqs";
BA_ "SPN" SG_ 2566756606 Aftrtrtmnt1AvrgTmBtwnActvRgnrtns 5454;
BA_ "SigType" SG_ 2566756606 Aftrtrtmnt1AvrgTmBtwnActvRgnrtns 1;
BA_ "SPN" SG_ 2566756606 Aftrtrtmnt1TtlNmbrOfPssvRgnrtns 3726;
BA_ "SigType" SG_ 2566756606 Aftrtrtmnt1TtlNmbrOfPssvRgnrtns 1;
BA_ "SPN" SG_ 2566756606 Aftrtrtmnt1TtlPssvRgnrationTime 3725;
BA_ "SigType" SG_ 2566756606 Aftrtrtmnt1TtlPssvRgnrationTime 1;
BA_ "SPN" SG_ 2566756606 Aftrtrtmnt1TtlNmbrOfActvRgnrtns 3525;
BA_ "SigType" SG_ 2566756606 Aftrtrtmnt1TtlNmbrOfActvRgnrtns 1;
BA_ "SPN" SG_ 2566756606 Aftrtreatment1TotalDisabledTime 3524;
BA_ "SigType" SG_ 2566756606 Aftrtreatment1TotalDisabledTime 1;
BA_ "SPN" SG_ 2566756606 Aftrtrtmnt1TtalRegenerationTime 3523;
BA_ "SigType" SG_ 2566756606 Aftrtrtmnt1TtalRegenerationTime 1;
BA_ "SPN" SG_ 2566756606 Aftertreatment1TotalFuelUsed 3522;
BA_ "SigType" SG_ 2566756606 Aftertreatment1TotalFuelUsed 1;
BA_ "SPN" SG_ 2565869310 Aftrtrtmnt1IntkOxygnSnsrPrlmnryF 3225;
BA_ "SigType" SG_ 2565869310 Aftrtrtmnt1IntkOxygnSnsrPrlmnryF 1;
BA_ "SystemSignalLongSymbol" SG_ 2565869310 Aftrtrtmnt1IntkOxygnSnsrPrlmnryF "Aftrtrtmnt1IntkOxygnSnsrPrlmnryFMI";
BA_ "SPN" SG_ 2565869310 Aftrtrtmnt1IntkGsSnsrPwerStatus 3218;
BA_ "SigType" SG_ 2565869310 Aftrtrtmnt1IntkGsSnsrPwerStatus 4;
BA_ "SPN" SG_ 2565869310 Aftrtrtmnt1IntkGsSnsrHtrPrlmnryF 3222;
BA_ "SigType" SG_ 2565869310 Aftrtrtmnt1IntkGsSnsrHtrPrlmnryF 1;
BA_ "SystemSignalLongSymbol" SG_ 2565869310 Aftrtrtmnt1IntkGsSnsrHtrPrlmnryF "Aftrtrtmnt1IntkGsSnsrHtrPrlmnryFMI";
BA_ "SPN" SG_ 2565869310 Aftrtrtmnt1IntkNOxSnsrPrlmnryFMI 3224;
BA_ "SPN" SG_ 2565869310 Aftrtrtmnt1IntkGsSnsrHeaterCtrl 3223;
BA_ "SigType" SG_ 2565869310 Aftrtrtmnt1IntkGsSnsrHeaterCtrl 4;
BA_ "SPN" SG_ 2565869310 Aftrtrtmnt1IntkWdRngO2RdngStble 3221;
BA_ "SigType" SG_ 2565869310 Aftrtrtmnt1IntkWdRngO2RdngStble 4;
BA_ "SPN" SG_ 2565869310 Aftrtrtmnt1IntkNOxReadingStable 3220;
BA_ "SigType" SG_ 2565869310 Aftrtrtmnt1IntkNOxReadingStable 4;
BA_ "SPN" SG_ 2565869310 Aftrtrtmnt1IntkeGasSensorAtTemp 3219;
BA_ "SigType" SG_ 2565869310 Aftrtrtmnt1IntkeGasSensorAtTemp 4;
BA_ "SPN" SG_ 2565869310 Aftertreatment1IntakeO2 3217;
BA_ "SigType" SG_ 2565869310 Aftertreatment1IntakeO2 1;
BA_ "SPN" SG_ 2565869310 Aftertreatment1IntakeNOx 3216;
BA_ "SigType" SG_ 2565869310 Aftertreatment1IntakeNOx 1;
BA_ "SPN" SG_ 2566763774 Aftrtrtmnt1DslPrtcltFltrIntkGsTm 3244;
BA_ "SigType" SG_ 2566763774 Aftrtrtmnt1DslPrtcltFltrIntkGsTm 1;
BA_ "SystemSignalLongSymbol" SG_ 2566763774 Aftrtrtmnt1DslPrtcltFltrIntkGsTm "Aftrtrtmnt1DslPrtcltFltrIntkGsTmpPrlmnryFMI";
BA_ "SPN" SG_ 2566763774 Aftrtrtmnt1ExhstGsTmp1PrlmnryFMI 3243;
BA_ "SPN" SG_ 2566763774 Aftertreatment1ExhaustGasTemp1 3241;
BA_ "SigType" SG_ 2566763774 Aftertreatment1ExhaustGasTemp1 1;
BA_ "SPN" SG_ 2566763774 Aftrtrtmnt1DslPrtcltFltrInt_0000 3242;
BA_ "SigType" SG_ 2566763774 Aftrtrtmnt1DslPrtcltFltrInt_0000 1;
BA_ "SystemSignalLongSymbol" SG_ 2566763774 Aftrtrtmnt1DslPrtcltFltrInt_0000 "Aftrtrtmnt1DslPrtcltFltrIntkGsTmp";
BA_ "SPN" SG_ 2631728894 AntitheftRandomNumber 1198;
BA_ "SigType" SG_ 2631728894 AntitheftRandomNumber 1;
BA_ "SPN" SG_ 2631728894 AntitheftComponentStatusStates 1196;
BA_ "SigType" SG_ 2631728894 AntitheftComponentStatusStates 4;
BA_ "SPN" SG_ 2631728894 AntthftEncryptnSdPrsntIndicator 1194;
BA_ "SigType" SG_ 2631728894 AntthftEncryptnSdPrsntIndicator 4;
BA_ "SPN" SG_ 2631728894 AntitheftModifyPwdStates 1197;
BA_ "SigType" SG_ 2631728894 AntitheftModifyPwdStates 4;
BA_ "SPN" SG_ 2631728894 AntitheftPwdValidIndicator 1195;
BA_ "SigType" SG_ 2631728894 AntitheftPwdValidIndicator 4;
BA_ "SPN" SG_ 2631794430 AntitheftPasswordRepresentation 1202;
BA_ "SigType" SG_ 2631794430 AntitheftPasswordRepresentation 1;
BA_ "SPN" SG_ 2631794430 AntitheftCmdStates 1201;
BA_ "SPN" SG_ 2631794430 AntitheftDesiredExitModeStates 1200;
BA_ "SigType" SG_ 2631794430 AntitheftDesiredExitModeStates 4;
BA_ "SPN" SG_ 2631794430 AntthftEncryptonIndicatorStates 1199;
BA_ "SigType" SG_ 2631794430 AntthftEncryptonIndicatorStates 4;
BA_ "SPN" SG_ 2633934846 EngAltWinding3Temp 1126;
BA_ "SigType" SG_ 2633934846 EngAltWinding3Temp 1;
BA_ "SPN" SG_ 2633934846 EngAltWinding2Temp 1125;
BA_ "SigType" SG_ 2633934846 EngAltWinding2Temp 1;
BA_ "SPN" SG_ 2633934846 EngAltWinding1Temp 1124;
BA_ "SigType" SG_ 2633934846 EngAltWinding1Temp 1;
BA_ "SPN" SG_ 2633934846 EngAltBearing2Temp 1123;
BA_ "SigType" SG_ 2633934846 EngAltBearing2Temp 1;
BA_ "SPN" SG_ 2633934846 EngAltBearing1Temp 1122;
BA_ "SigType" SG_ 2633934846 EngAltBearing1Temp 1;
BA_ "SPN" SG_ 2362572542 LevelPresetRearAxleRight 1735;
BA_ "SigType" SG_ 2362572542 LevelPresetRearAxleRight 1;
BA_ "SPN" SG_ 2362572542 LevelPresetRearAxleLeft 1758;
BA_ "SigType" SG_ 2362572542 LevelPresetRearAxleLeft 1;
BA_ "SPN" SG_ 2362572542 LevelPresetFrontAxleRight 1757;
BA_ "SigType" SG_ 2362572542 LevelPresetFrontAxleRight 1;
BA_ "SPN" SG_ 2362572542 LevelPresetFrontAxleLeft 1732;
BA_ "SigType" SG_ 2362572542 LevelPresetFrontAxleLeft 1;
BA_ "SPN" SG_ 2365478910 ElctrncShckAbsrbrCtrlMdLft_TgAxl 1831;
BA_ "SigType" SG_ 2365478910 ElctrncShckAbsrbrCtrlMdLft_TgAxl 4;
BA_ "SPN" SG_ 2365478910 ElctrncShckAbsrbrCtrlMdRearAxle 1832;
BA_ "SigType" SG_ 2365478910 ElctrncShckAbsrbrCtrlMdRearAxle 4;
BA_ "SPN" SG_ 2365478910 ElctrncShckAbsrbrCtrlMdFrntAxle 1833;
BA_ "SigType" SG_ 2365478910 ElctrncShckAbsrbrCtrlMdFrntAxle 4;
BA_ "SPN" SG_ 2365478910 DamperStiffnessLift_TagAxle 1731;
BA_ "SigType" SG_ 2365478910 DamperStiffnessLift_TagAxle 1;
BA_ "SPN" SG_ 2365478910 DamperStiffnessRearAxle 1730;
BA_ "SigType" SG_ 2365478910 DamperStiffnessRearAxle 1;
BA_ "SPN" SG_ 2365478910 DamperStiffnessFrontAxle 1729;
BA_ "SigType" SG_ 2365478910 DamperStiffnessFrontAxle 1;
BA_ "SPN" SG_ 2560950014 TestLimitMinimum 4112;
BA_ "SigType" SG_ 2560950014 TestLimitMinimum 1;
BA_ "SPN" SG_ 2560950014 TestLimitMaximum 4111;
BA_ "SigType" SG_ 2560950014 TestLimitMaximum 1;
BA_ "SPN" SG_ 2560950014 TestValue 4110;
BA_ "SigType" SG_ 2560950014 TestValue 1;
BA_ "SPN" SG_ 2560950014 SlotId 4109;
BA_ "SigType" SG_ 2560950014 SlotId 1;
BA_ "SPN" SG_ 2560950014 FailureModeIdentifier1 1215;
BA_ "SPN" SG_ 2560950014 SPN1High 1214;
BA_ "SPN" SG_ 2560950014 SPN1 1214;
BA_ "SPN" SG_ 2566763262 Aftrtrtmnt1DslPrtcltFltrIntrmdtG 3254;
BA_ "SigType" SG_ 2566763262 Aftrtrtmnt1DslPrtcltFltrIntrmdtG 1;
BA_ "SystemSignalLongSymbol" SG_ 2566763262 Aftrtrtmnt1DslPrtcltFltrIntrmdtG "Aftrtrtmnt1DslPrtcltFltrIntrmdtGsTmpPrlmnryFMI";
BA_ "SPN" SG_ 2566763262 Aftrtrtmnt1DslPrtcltFltrInt_0001 3250;
BA_ "SigType" SG_ 2566763262 Aftrtrtmnt1DslPrtcltFltrInt_0001 1;
BA_ "SystemSignalLongSymbol" SG_ 2566763262 Aftrtrtmnt1DslPrtcltFltrInt_0001 "Aftrtrtmnt1DslPrtcltFltrIntrmdtGsTmp";
BA_ "SPN" SG_ 2566763262 Aftrtrtmnt1DslPrtcltFltrDltPrssP 3253;
BA_ "SigType" SG_ 2566763262 Aftrtrtmnt1DslPrtcltFltrDltPrssP 1;
BA_ "SystemSignalLongSymbol" SG_ 2566763262 Aftrtrtmnt1DslPrtcltFltrDltPrssP "Aftrtrtmnt1DslPrtcltFltrDltPrssPrlmnryFMI";
BA_ "SPN" SG_ 2566763262 Aftrtrtmnt1DslPrtcltFltrDffPrss 3251;
BA_ "SigType" SG_ 2566763262 Aftrtrtmnt1DslPrtcltFltrDffPrss 1;
BA_ "SPN" SG_ 2566763262 Aftrtrtmnt1ExhstGsTmp2PrlmnryFMI 3252;
BA_ "SPN" SG_ 2566763262 Aftertreatment1ExhaustGasTemp2 3249;
BA_ "SigType" SG_ 2566763262 Aftertreatment1ExhaustGasTemp2 1;
BA_ "SPN" SG_ 2565869566 Aftrtrtmnt1OtltOxygnSnsrPrlmnryF 3235;
BA_ "SigType" SG_ 2565869566 Aftrtrtmnt1OtltOxygnSnsrPrlmnryF 1;
BA_ "SystemSignalLongSymbol" SG_ 2565869566 Aftrtrtmnt1OtltOxygnSnsrPrlmnryF "Aftrtrtmnt1OtltOxygnSnsrPrlmnryFMI";
BA_ "SPN" SG_ 2565869566 Aftrtrtmnt1OtltGsSnsrPwerStatus 3228;
BA_ "SigType" SG_ 2565869566 Aftrtrtmnt1OtltGsSnsrPwerStatus 4;
BA_ "SPN" SG_ 2565869566 Aftrtrtmnt1OtltGsSnsrHtrPrlmnryF 3232;
BA_ "SigType" SG_ 2565869566 Aftrtrtmnt1OtltGsSnsrHtrPrlmnryF 1;
BA_ "SystemSignalLongSymbol" SG_ 2565869566 Aftrtrtmnt1OtltGsSnsrHtrPrlmnryF "Aftrtrtmnt1OtltGsSnsrHtrPrlmnryFMI";
BA_ "SPN" SG_ 2565869566 Aftrtrtmnt1OtltNOxSnsrPrlmnryFMI 3234;
BA_ "SPN" SG_ 2565869566 Aftrtrtmnt1OtltGsSnsrHeaterCtrl 3233;
BA_ "SigType" SG_ 2565869566 Aftrtrtmnt1OtltGsSnsrHeaterCtrl 4;
BA_ "SPN" SG_ 2565869566 Aftrtrtmnt1OtltWdRngO2RdngStble 3231;
BA_ "SigType" SG_ 2565869566 Aftrtrtmnt1OtltWdRngO2RdngStble 4;
BA_ "SPN" SG_ 2565869566 Aftrtrtmnt1OtltNOxReadingStable 3230;
BA_ "SigType" SG_ 2565869566 Aftrtrtmnt1OtltNOxReadingStable 4;
BA_ "SPN" SG_ 2565869566 Aftrtrtmnt1OtletGasSensorAtTemp 3229;
BA_ "SigType" SG_ 2565869566 Aftrtrtmnt1OtletGasSensorAtTemp 4;
BA_ "SPN" SG_ 2565869566 Aftertreatment1OutletO2 3227;
BA_ "SigType" SG_ 2565869566 Aftertreatment1OutletO2 1;
BA_ "SPN" SG_ 2565869566 Aftertreatment1OutletNOx 3226;
BA_ "SigType" SG_ 2565869566 Aftertreatment1OutletNOx 1;
BA_ "SPN" SG_ 2566763518 Aftrtrtmnt1DslPrtcltFltrOtltGsTm 3246;
BA_ "SigType" SG_ 2566763518 Aftrtrtmnt1DslPrtcltFltrOtltGsTm 1;
BA_ "SystemSignalLongSymbol" SG_ 2566763518 Aftrtrtmnt1DslPrtcltFltrOtltGsTm "Aftrtrtmnt1DslPrtcltFltrOtltGsTmp";
BA_ "SPN" SG_ 2566763518 Aftrtrtmnt1DslPrtcltFltrOtltExhs 3248;
BA_ "SigType" SG_ 2566763518 Aftrtrtmnt1DslPrtcltFltrOtltExhs 1;
BA_ "SystemSignalLongSymbol" SG_ 2566763518 Aftrtrtmnt1DslPrtcltFltrOtltExhs "Aftrtrtmnt1DslPrtcltFltrOtltExhstGsTmpPrlmnryFMI";
BA_ "SPN" SG_ 2566763518 Aftrtrtmnt1ExhstGsTmp3PrlmnryFMI 3247;
BA_ "SPN" SG_ 2566763518 Aftertreatment1ExhaustGasTemp3 3245;
BA_ "SigType" SG_ 2566763518 Aftertreatment1ExhaustGasTemp3 1;
BA_ "SPN" SG_ 2566749182 DslPrtclteFilter1AshLoadPercent 3720;
BA_ "SigType" SG_ 2566749182 DslPrtclteFilter1AshLoadPercent 1;
BA_ "SPN" SG_ 2566749182 DslPrtcltFltr1TmSncLstActvRgnrtn 3721;
BA_ "SigType" SG_ 2566749182 DslPrtcltFltr1TmSncLstActvRgnrtn 1;
BA_ "SPN" SG_ 2566749182 DslPrtcltFilter1SootLoadPercent 3719;
BA_ "SigType" SG_ 2566749182 DslPrtcltFilter1SootLoadPercent 1;
BA_ "SPN" SG_ 2566749182 Aftrtrtmnt1DslPrtcltFltrStLdRgnr 5466;
BA_ "SigType" SG_ 2566749182 Aftrtrtmnt1DslPrtcltFltrStLdRgnr 1;
BA_ "SystemSignalLongSymbol" SG_ 2566749182 Aftrtrtmnt1DslPrtcltFltrStLdRgnr "Aftrtrtmnt1DslPrtcltFltrStLdRgnrtnThrshld";
BA_ "SPN" SG_ 2566748670 Aftrtrtmnt1TrpNmbrOfActvRgnrtnMn 3740;
BA_ "SigType" SG_ 2566748670 Aftrtrtmnt1TrpNmbrOfActvRgnrtnMn 1;
BA_ "SystemSignalLongSymbol" SG_ 2566748670 Aftrtrtmnt1TrpNmbrOfActvRgnrtnMn "Aftrtrtmnt1TrpNmbrOfActvRgnrtnMnlRqs";
BA_ "SPN" SG_ 2566748670 Aftrtrtmnt1TrpNmbrOfActvRgnrtnIn 3739;
BA_ "SigType" SG_ 2566748670 Aftrtrtmnt1TrpNmbrOfActvRgnrtnIn 1;
BA_ "SystemSignalLongSymbol" SG_ 2566748670 Aftrtrtmnt1TrpNmbrOfActvRgnrtnIn "Aftrtrtmnt1TrpNmbrOfActvRgnrtnInhbtRqs";
BA_ "SPN" SG_ 2566748670 Aftrtrtmnt1TrpNmbrOfPssvRgnrtns 3738;
BA_ "SigType" SG_ 2566748670 Aftrtrtmnt1TrpNmbrOfPssvRgnrtns 1;
BA_ "SPN" SG_ 2566748670 Aftrtrtmnt1TrpPssvRgnrationTime 3737;
BA_ "SigType" SG_ 2566748670 Aftrtrtmnt1TrpPssvRgnrationTime 1;
BA_ "SPN" SG_ 2566748670 Aftrtrtmnt1TrpNmbrOfActvRgnrtns 3736;
BA_ "SigType" SG_ 2566748670 Aftrtrtmnt1TrpNmbrOfActvRgnrtns 1;
BA_ "SPN" SG_ 2566748670 Aftertreatment1TripDisabledTime 3735;
BA_ "SigType" SG_ 2566748670 Aftertreatment1TripDisabledTime 1;
BA_ "SPN" SG_ 2566748670 Aftrtrtmnt1TrpActvRgnrationTime 3734;
BA_ "SigType" SG_ 2566748670 Aftrtrtmnt1TrpActvRgnrationTime 1;
BA_ "SPN" SG_ 2566748670 Aftertreatment1TripFuelUsed 3733;
BA_ "SigType" SG_ 2566748670 Aftertreatment1TripFuelUsed 1;
BA_ "SPN" SG_ 2566758142 Aftrtreatment2AirEnableActuator 3503;
BA_ "SigType" SG_ 2566758142 Aftrtreatment2AirEnableActuator 4;
BA_ "SPN" SG_ 2566758142 Aftertreatment2PurgeAirActuator 3504;
BA_ "SigType" SG_ 2566758142 Aftertreatment2PurgeAirActuator 4;
BA_ "SPN" SG_ 2566758142 Aftrtrtmnt2AtmzationAirActuator 3505;
BA_ "SigType" SG_ 2566758142 Aftrtrtmnt2AtmzationAirActuator 4;
BA_ "SPN" SG_ 2566758142 Aftertreatment2AirSystemRelay 3506;
BA_ "SigType" SG_ 2566758142 Aftertreatment2AirSystemRelay 4;
BA_ "SPN" SG_ 2566758142 Aftrtrtment2AirPressActuatorPos 3502;
BA_ "SigType" SG_ 2566758142 Aftrtrtment2AirPressActuatorPos 1;
BA_ "SPN" SG_ 2566758142 Aftertreatment2AirPressCtrl 3501;
BA_ "SigType" SG_ 2566758142 Aftertreatment2AirPressCtrl 1;
BA_ "SPN" SG_ 2566758142 Aftertreatment2PurgeAirPress 3500;
BA_ "SigType" SG_ 2566758142 Aftertreatment2PurgeAirPress 1;
BA_ "SPN" SG_ 2566758142 Aftertreatment2SupplyAirPress 3499;
BA_ "SigType" SG_ 2566758142 Aftertreatment2SupplyAirPress 1;
BA_ "SPN" SG_ 2566745342 Aftertreatment2SecondAirPress 3838;
BA_ "SigType" SG_ 2566745342 Aftertreatment2SecondAirPress 1;
BA_ "SPN" SG_ 2566745342 Aftrtreatment2SecondAirMassFlow 3835;
BA_ "SigType" SG_ 2566745342 Aftrtreatment2SecondAirMassFlow 1;
BA_ "SPN" SG_ 2566745342 Aftertreatment2SecondAirTemp 3834;
BA_ "SigType" SG_ 2566745342 Aftertreatment2SecondAirTemp 1;
BA_ "SPN" SG_ 2566745342 Aftrtratment2SecondAirDiffPress 3833;
BA_ "SigType" SG_ 2566745342 Aftrtratment2SecondAirDiffPress 1;
BA_ "SPN" SG_ 2566758654 Aftrtrtmnt2FlInjctor1HeaterCtrl 4302;
BA_ "SigType" SG_ 2566758654 Aftrtrtmnt2FlInjctor1HeaterCtrl 1;
BA_ "SPN" SG_ 2566758654 Aftertreatment2FuelPress1Ctrl 3493;
BA_ "SigType" SG_ 2566758654 Aftertreatment2FuelPress1Ctrl 1;
BA_ "SPN" SG_ 2566758654 Aftertreatment2FuelPress1 3494;
BA_ "SigType" SG_ 2566758654 Aftertreatment2FuelPress1 1;
BA_ "SPN" SG_ 2566758654 Aftrtratment2FuelEnableActuator 3496;
BA_ "SigType" SG_ 2566758654 Aftrtratment2FuelEnableActuator 4;
BA_ "SPN" SG_ 2566758654 Aftrtratment2RegenerationStatus 3497;
BA_ "SigType" SG_ 2566758654 Aftrtratment2RegenerationStatus 4;
BA_ "SPN" SG_ 2566758654 Aftertreatment2Ignt 3498;
BA_ "SigType" SG_ 2566758654 Aftertreatment2Ignt 4;
BA_ "SPN" SG_ 2566758654 Aftrtreatment2FuelDrainActuator 4098;
BA_ "SigType" SG_ 2566758654 Aftrtreatment2FuelDrainActuator 4;
BA_ "SPN" SG_ 2566758654 Aftertreatment2FuelRate 3495;
BA_ "SigType" SG_ 2566758654 Aftertreatment2FuelRate 1;
VAL_ 2364549886 YawRateExRangeFigureOfMerit 3 "NotAvailable" 2 "Error" 1 "YwRtDgrddDtIsSspctDTEnvrnmntlCn" 0 "YwRtFllyFnctnlDtIsWthnSnsrSpcfc" ;
VAL_ 2364549886 RollRateExRangeFigureOfMerit 3 "NotAvailable" 2 "Error" 1 "RllRtDgrddDtIsSspctDTEnvrnmntlC" 0 "RllRtFllyFnctnlDtIsWthnSnsrSpcf" ;
VAL_ 2364549886 PitchRateExRangeFigureOfMerit 3 "NotAvailable" 2 "Error" 1 "PtchRtDgrddDtIsSspctDTEnvrnmntl" 0 "PtchRtFllyFnctnlDtIsWthnSnsrSpc" ;
VAL_ 2566712318 Aftrtrtmnt2NOxAdsrbrDSOxRgnrtnSt 3 "NotAvailable" 2 "ErrorIndicator" 1 "Active" 0 "Inactive" ;
VAL_ 2566712318 Aftrtrtmnt2NOxAdsrbrDNOxRgnrtnSt 3 "NotAvailable" 2 "ErrorIndicator" 1 "Active" 0 "Inactive" ;
VAL_ 2566712574 Aftrtrtmnt1NOxAdsrbrDSOxRgnrtnSt 3 "NotAvailable" 2 "ErrorIndicator" 1 "Active" 0 "Inactive" ;
VAL_ 2566712574 Aftrtrtmnt1NOxAdsrbrDNOxRgnrtnSt 3 "NotAvailable" 2 "ErrorIndicator" 1 "Active" 0 "Inactive" ;
VAL_ 2566731262 Aftrtrtmnt2SCRCatalystTankLevel 4 "Full" 0 "Empty" ;
VAL_ 2566730750 Aftrtrtmnt2SCRCtlystRgntPmpStte 3 "notAvailable" 2 "reservedForSAEAssignment" 1 "pumpError" 0 "pumpOperational" ;
VAL_ 2566731518 Aftrtrtmnt2SCRCtlystReagentType 15 "NotAvailable" 14 "ErrrDtctdWthUrRgntTypeDetection" 13 "NtAblTDtrmneCatalystReagentType" 5 "to1100ReservedForSAEAssignment" 3 "CatalystReagentIsProperMixture" 2 "CatalystReagentIsDiesel" 1 "CtlystRgntIsUrCncntrationTooLow" 0 "CtlystRgntIsUrCncntrtionTooHigh" ;
VAL_ 2164079358 Aftrtrtmnt2SCRCtlystRgntLnHter4 3 "notAvailable" 2 "rservedForFutureAssignmentBySAE" 1 "RqForHeaterToBeActive" 0 "RqForHeaterToBeInactive" ;
VAL_ 2164079358 Aftrtrtmnt2SCRCtlystRgntLnHter3 3 "notAvailable" 2 "rservedForFutureAssignmentBySAE" 1 "RqForHeaterToBeActive" 0 "RqForHeaterToBeInactive" ;
VAL_ 2164079358 Aftrtrtmnt2SCRCtlystRgntLnHter2 3 "notAvailable" 2 "rservedForFutureAssignmentBySAE" 1 "RqForHeaterToBeActive" 0 "RqForHeaterToBeInactive" ;
VAL_ 2164079358 Aftrtrtmnt2SCRCtlystRgntLnHter1 3 "notAvailable" 2 "rservedForFutureAssignmentBySAE" 1 "RqForHeaterToBeActive" 0 "RqForHeaterToBeInactive" ;
VAL_ 2164079358 Aftrtrtmnt2SCRDserHeatingModeRq 7 "NotAvailable" 4 "110Reserved" 3 "HeaterOn" 2 "HeaterAutomaticMode" 1 "HeaterEconomyMode" 0 "HeaterOff" ;
VAL_ 2164079358 Aftrtrtmnt2SCRDsrFltSpprssionRq 3 "NotAvailable" 2 "Reserved" 1 "ErrorSuppressionOn" 0 "ErrorSuppressionOff" ;
VAL_ 2364549118 Aftrtratment2SCRSystemRqedState 15 "NotAvailable" 14 "Error" 11 "1101RsrvdFrFtureAssignmentBySAE" 10 "ServiceTestModeDosingNotAllowed" 9 "ServiceTestModeDosingAllowed" 8 "Diagnosis" 7 "Shutoff" 6 "ProtectModeAgainstCold" 5 "ProtectModeAgainstHeat" 4 "RservedForFutureAssignmentBySAE" 3 "SystemErrorPending" 2 "NormalDosingOperation" 1 "PreparingDosingReadiness" 0 "Dormant" ;
VAL_ 2566732798 Aftrtrtmnt2SCRCtlystRgntLnHtr4St 3 "notAvailable" 2 "error" 1 "heaterActive" 0 "heaterInactive" ;
VAL_ 2566732798 Aftrtrtmnt2SCRCtlystRgntLnHtr3St 3 "notAvailable" 2 "error" 1 "heaterActive" 0 "heaterInactive" ;
VAL_ 2566732798 Aftrtrtmnt2SCRCtlystRgntLnHtr2St 3 "notAvailable" 2 "error" 1 "heaterActive" 0 "heaterInactive" ;
VAL_ 2566732798 Aftrtrtmnt2SCRCtlystRgntLnHtr1St 3 "notAvailable" 2 "error" 1 "heaterActive" 0 "heaterInactive" ;
VAL_ 2566732798 Aftrtrtmnt2SCRFedbackCtrlStatus 7 "notAvailable" 6 "error" 5 "rservedForFutureAssignmentBySAE" 1 "closedLoopCtrlActive" 0 "openLoopCtrlActive" ;
VAL_ 2566732798 Aftrtrtmnt2SCRDsngVlvExhstTmpRdc 7 "NotAvailable" 6 "Error" 5 "RservedForFutureAssignmentBySAE" 2 "ReductionRqStage2" 1 "ReductionRqStage1" 0 "NoRq" ;
VAL_ 2364548862 Aftertreatment2SCRSystemState 15 "NotAvailable" 14 "Error" 11 "1101RsrvdFrFtureAssignmentBySAE" 10 "ServiceTestModeDosingNotAllowed" 9 "ServiceTestModeDosingAllowed" 8 "Diagnosis" 7 "Shutoff" 6 "ProtectModeAgainstCold" 5 "ProtectModeAgainstHeat" 4 "RservedForFutureAssignmentBySAE" 3 "SystemErrorPending" 2 "NormalDosingOperation" 1 "PreparingDosingReadiness" 0 "Dormant" ;
VAL_ 2364549374 Aftrtrtmnt2OtltNH3GsSnsrHtrCtrl 3 "HeaterOffNotAvailable" 2 "Preheat1" 1 "Preheat2" 0 "Automatic" ;
VAL_ 2566733054 Aftrtrtmnt1SCRCtlystRgntPmpStte 3 "notAvailable" 2 "reservedForSAEAssignment" 1 "pumpError" 0 "pumpOperational" ;
VAL_ 2566734078 Aftrtrtmnt1SCRCtlystRgntLnHter4 3 "notAvailable" 2 "rservedForFutureAssignmentBySAE" 1 "RqForHeaterToBeActive" 0 "RqForHeaterToBeInactive" ;
VAL_ 2566734078 Aftrtrtmnt1SCRCtlystRgntLnHter3 3 "notAvailable" 2 "rservedForFutureAssignmentBySAE" 1 "RqForHeaterToBeActive" 0 "RqForHeaterToBeInactive" ;
VAL_ 2566734078 Aftrtrtmnt1SCRCtlystRgntLnHter2 3 "notAvailable" 2 "rservedForFutureAssignmentBySAE" 1 "RqForHeaterToBeActive" 0 "RqForHeaterToBeInactive" ;
VAL_ 2566734078 Aftrtrtmnt1SCRCtlystRgntLnHter1 3 "notAvailable" 2 "rservedForFutureAssignmentBySAE" 1 "RqForHeaterToBeActive" 0 "RqForHeaterToBeInactive" ;
VAL_ 2566734078 Aftrtrtmnt1SCRDserHeatingModeRq 7 "NotAvailable" 4 "110Reserved" 3 "HeaterOn" 2 "HeaterAutomaticMode" 1 "HeaterEconomyMode" 0 "HeaterOff" ;
VAL_ 2566734078 Aftrtrtmnt1SCRDsrFltSpprssionRq 3 "NotAvailable" 2 "Reserved" 1 "ErrorSuppressionOn" 0 "ErrorSuppressionOff" ;
VAL_ 2364548350 Aftrtratment1SCRSystemRqedState 15 "NotAvailable" 14 "Error" 11 "1101RsrvdFrFtureAssignmentBySAE" 10 "ServiceTestModeDosingNotAllowed" 9 "ServiceTestModeDosingAllowed" 8 "Diagnosis" 7 "Shutoff" 6 "ProtectModeAgainstCold" 5 "ProtectModeAgainstHeat" 4 "RservedForFutureAssignmentBySAE" 3 "SystemErrorPending" 2 "NormalDosingOperation" 1 "PreparingDosingReadiness" 0 "Dormant" ;
VAL_ 2566734334 Aftrtrtmnt1SCRCtlystRgntLnHtr4St 3 "notAvailable" 2 "error" 1 "heaterActive" 0 "heaterInactive" ;
VAL_ 2566734334 Aftrtrtmnt1SCRCtlystRgntLnHtr3St 3 "notAvailable" 2 "error" 1 "heaterActive" 0 "heaterInactive" ;
VAL_ 2566734334 Aftrtrtmnt1SCRCtlystRgntLnHtr2St 3 "notAvailable" 2 "error" 1 "heaterActive" 0 "heaterInactive" ;
VAL_ 2566734334 Aftrtrtmnt1SCRCtlystRgntLnHtr1St 3 "notAvailable" 2 "error" 1 "heaterActive" 0 "heaterInactive" ;
VAL_ 2566734334 Aftrtrtmnt1SCRFedbackCtrlStatus 7 "notAvailable" 6 "error" 5 "rservedForFutureAssignmentBySAE" 1 "closedLoopCtrlActive" 0 "openLoopCtrlActive" ;
VAL_ 2566734334 Aftrtrtmnt1SCRDsngVlvExhstTmpRdc 7 "NotAvailable" 6 "Error" 5 "RservedForFutureAssignmentBySAE" 2 "ReductionRqStage2" 1 "ReductionRqStage1" 0 "NoRq" ;
VAL_ 2364548094 Aftertreatment1SCRSystemState 15 "NotAvailable" 14 "Error" 11 "1101RsrvdFrFtureAssignmentBySAE" 10 "ServiceTestModeDosingNotAllowed" 9 "ServiceTestModeDosingAllowed" 8 "Diagnosis" 7 "Shutoff" 6 "ProtectModeAgainstCold" 5 "ProtectModeAgainstHeat" 4 "RservedForFutureAssignmentBySAE" 3 "SystemErrorPending" 2 "NormalDosingOperation" 1 "PreparingDosingReadiness" 0 "Dormant" ;
VAL_ 2364548606 Aftrtrtmnt1OtltNH3GsSnsrHtrCtrl 3 "HeaterOffNotAvailable" 2 "Preheat1" 1 "Preheat2" 0 "Automatic" ;
VAL_ 2566742270 FailureModeIdentifier1 31 "Not available" 19 "Received network data in error" 18 "Below normal (moderately severe)" 17 "Below normal (least severe)" 16 "Above normal (moderately severe)" 15 "Above normal (least severe)" 14 "Special intstructions" 13 "Out of calibration" 12 "Bad intelligent device" 11 "Root cause not known" 10 "Abnormal rate of change" 9 "Abnormal update rate" 8 "Abnormal frequency" 7 "Mechanical system not responding" 6 "Current above normal" 5 "Current below normal" 4 "Voltage below normal" 3 "Voltage above normal" 2 "Data erratic" 1 "Below normal (most severe)" 0 "Above normal (most severe)" ;
VAL_ 2560687870 PMNTEDeficiencyAreaStatus 3 "NotAvailable" 2 "Reserved" 1 "InsideControlArea" 0 "OutsideControlArea" ;
VAL_ 2560687870 MnfcPMNTECarveOutAreaStatus 3 "NotAvailable" 2 "Reserved" 1 "InsideControlArea" 0 "OutsideControlArea" ;
VAL_ 2560687870 PMNTEControlAreaStatus 3 "NotAvailable" 2 "Reserved" 1 "InsideControlArea" 0 "OutsideControlArea" ;
VAL_ 2560687870 NOxNTEDeficiencyAreaStatus 3 "NotAvailable" 2 "Reserved" 1 "InsideControlArea" 0 "OutsideControlArea" ;
VAL_ 2560687870 MnfcNOxNTECarveOutAreaStatus 3 "NotAvailable" 2 "Reserved" 1 "InsideControlArea" 0 "OutsideControlArea" ;
VAL_ 2560687870 NOxNTEControlAreaStatus 3 "NotAvailable" 2 "Reserved" 1 "InsideControlArea" 0 "OutsideControlArea" ;
VAL_ 2566809342 BatteryMainSwitchHoldState 3 "DontCare_TakeNoAction" 2 "Reserved" 1 "BatteryMainSwitchHeld" 0 "BatteryMainSwitchNotHeld" ;
VAL_ 2365446910 Joystick3XAxisDetentPosStatus 3 "NotAvailable" 2 "ErrorIndicator" 1 "InDetentPos" 0 "NotInDetentPos" ;
VAL_ 2365446910 Joystick3Button9PressedStatus 3 "NotAvailable" 2 "ErrorIndicator" 1 "ButtonPressed" 0 "ButtonNotPressed" ;
VAL_ 2365446910 Joystick3Button10PressedStatus 3 "NotAvailable" 2 "ErrorIndicator" 1 "ButtonPressed" 0 "ButtonNotPressed" ;
VAL_ 2365446910 Joystick3Button11PressedStatus 3 "NotAvailable" 2 "ErrorIndicator" 1 "ButtonPressed" 0 "ButtonNotPressed" ;
VAL_ 2365446910 Joystick3Button12PressedStatus 3 "NotAvailable" 2 "ErrorIndicator" 1 "ButtonPressed" 0 "ButtonNotPressed" ;
VAL_ 2365446910 Joystick3YAxisDetentPosStatus 3 "NotAvailable" 2 "ErrorIndicator" 1 "InDetentPos" 0 "NotInDetentPos" ;
VAL_ 2365446910 Jystck3YAxsLvrFrwrdPstvPsStatus 3 "NotAvailable" 2 "ErrorIndicator" 1 "OnPositiveSideOfNeutral" 0 "NotOnPositiveSideOfNeutral" ;
VAL_ 2365446910 Jystck3YAxsLvrBckNgtvePosStatus 3 "NotAvailable" 2 "ErrorIndicator" 1 "OnNegativeSideOfNeutral" 0 "NotOnNegativeSideOfNeutral" ;
VAL_ 2365446910 Joystick3YAxisNeutralPosStatus 3 "NotAvailable" 2 "ErrorIndicator" 1 "InNeutralPos" 0 "NotInNeutralPos" ;
VAL_ 2365446910 Jystck3XAxsLvrRghtPstvPosStatus 3 "NotAvailable" 2 "ErrorIndicator" 1 "OnPositiveSideOfNeutral" 0 "NotOnPositiveSideOfNeutral" ;
VAL_ 2365446910 Jystck3XAxsLvrLftNgtvePosStatus 3 "NotAvailable" 2 "ErrorIndicator" 1 "OnNegativeSideOfNeutral" 0 "NotOnNegativeSideOfNeutral" ;
VAL_ 2365446910 Joystick3XAxisNeutralPosStatus 3 "NotAvailable" 2 "ErrorIndicator" 1 "InNeutralPos" 0 "NotInNeutralPos" ;
VAL_ 2365446910 Joystick3Button5PressedStatus 3 "NotAvailable" 2 "ErrorIndicator" 1 "ButtonPressed" 0 "ButtonNotPressed" ;
VAL_ 2365446910 Joystick3Button6PressedStatus 3 "NotAvailable" 2 "ErrorIndicator" 1 "ButtonPressed" 0 "ButtonNotPressed" ;
VAL_ 2365446910 Joystick3Button7PressedStatus 3 "NotAvailable" 2 "ErrorIndicator" 1 "ButtonPressed" 0 "ButtonNotPressed" ;
VAL_ 2365446910 Joystick3Button8PressedStatus 3 "NotAvailable" 2 "ErrorIndicator" 1 "ButtonPressed" 0 "ButtonNotPressed" ;
VAL_ 2365446910 Joystick3Button1PressedStatus 3 "NotAvailable" 2 "ErrorIndicator" 1 "ButtonPressed" 0 "ButtonNotPressed" ;
VAL_ 2365446910 Joystick3Button2PressedStatus 3 "NotAvailable" 2 "ErrorIndicator" 1 "ButtonPressed" 0 "ButtonNotPressed" ;
VAL_ 2365446910 Joystick3Button3PressedStatus 3 "NotAvailable" 2 "ErrorIndicator" 1 "ButtonPressed" 0 "ButtonNotPressed" ;
VAL_ 2365446910 Joystick3Button4PressedStatus 3 "NotAvailable" 2 "ErrorIndicator" 1 "ButtonPressed" 0 "ButtonNotPressed" ;
VAL_ 2365446398 Joystick2XAxisDetentPosStatus 3 "NotAvailable" 2 "ErrorIndicator" 1 "InDetentPos" 0 "NotInDetentPos" ;
VAL_ 2365446398 Joystick2YAxisDetentPosStatus 3 "NotAvailable" 2 "ErrorIndicator" 1 "InDetentPos" 0 "NotInDetentPos" ;
VAL_ 2365446398 Jystck2YAxsLvrFrwrdPstvPsStatus 3 "NotAvailable" 2 "ErrorIndicator" 1 "OnPositiveSideOfNeutral" 0 "NotOnPositiveSideOfNeutral" ;
VAL_ 2365446398 Jystck2YAxsLvrBckNgtvePosStatus 3 "NotAvailable" 2 "ErrorIndicator" 1 "OnNegativeSideOfNeutral" 0 "NotOnNegativeSideOfNeutral" ;
VAL_ 2365446398 Joystick2YAxisNeutralPosStatus 3 "NotAvailable" 2 "ErrorIndicator" 1 "InNeutralPos" 0 "NotInNeutralPos" ;
VAL_ 2365446398 Jystck2XAxsLvrRghtPstvPosStatus 3 "NotAvailable" 2 "ErrorIndicator" 1 "OnPositiveSideOfNeutral" 0 "NotOnPositiveSideOfNeutral" ;
VAL_ 2365446398 Jystck2XAxsLvrLftNgtvePosStatus 3 "NotAvailable" 2 "ErrorIndicator" 1 "OnNegativeSideOfNeutral" 0 "NotOnNegativeSideOfNeutral" ;
VAL_ 2365446398 Joystick2XAxisNeutralPosStatus 3 "NotAvailable" 2 "ErrorIndicator" 1 "InNeutralPos" 0 "NotInNeutralPos" ;
VAL_ 2365446398 Joystick2Button9PressedStatus 3 "NotAvailable" 2 "ErrorIndicator" 1 "ButtonPressed" 0 "ButtonNotPressed" ;
VAL_ 2365446398 Joystick2Button10PressedStatus 3 "NotAvailable" 2 "ErrorIndicator" 1 "ButtonPressed" 0 "ButtonNotPressed" ;
VAL_ 2365446398 Joystick2Button11PressedStatus 3 "NotAvailable" 2 "ErrorIndicator" 1 "ButtonPressed" 0 "ButtonNotPressed" ;
VAL_ 2365446398 Joystick2Button12PressedStatus 3 "NotAvailable" 2 "ErrorIndicator" 1 "ButtonPressed" 0 "ButtonNotPressed" ;
VAL_ 2365446398 Joystick2Button5PressedStatus 3 "NotAvailable" 2 "ErrorIndicator" 1 "ButtonPressed" 0 "ButtonNotPressed" ;
VAL_ 2365446398 Joystick2Button6PressedStatus 3 "NotAvailable" 2 "ErrorIndicator" 1 "ButtonPressed" 0 "ButtonNotPressed" ;
VAL_ 2365446398 Joystick2Button7PressedStatus 3 "NotAvailable" 2 "ErrorIndicator" 1 "ButtonPressed" 0 "ButtonNotPressed" ;
VAL_ 2365446398 Joystick2Button8PressedStatus 3 "NotAvailable" 2 "ErrorIndicator" 1 "ButtonPressed" 0 "ButtonNotPressed" ;
VAL_ 2365446398 Joystick2Button1PressedStatus 3 "NotAvailable" 2 "ErrorIndicator" 1 "ButtonPressed" 0 "ButtonNotPressed" ;
VAL_ 2365446398 Joystick2Button2PressedStatus 3 "NotAvailable" 2 "ErrorIndicator" 1 "ButtonPressed" 0 "ButtonNotPressed" ;
VAL_ 2365446398 Joystick2Button3PressedStatus 3 "NotAvailable" 2 "ErrorIndicator" 1 "ButtonPressed" 0 "ButtonNotPressed" ;
VAL_ 2365446398 Joystick2Button4PressedStatus 3 "NotAvailable" 2 "ErrorIndicator" 1 "ButtonPressed" 0 "ButtonNotPressed" ;
VAL_ 2365445886 Joystick1XAxisDetentPosStatus 3 "NotAvailable" 2 "ErrorIndicator" 1 "InDetentPos" 0 "NotInDetentPos" ;
VAL_ 2365445886 Joystick1YAxisDetentPosStatus 3 "NotAvailable" 2 "ErrorIndicator" 1 "InDetentPos" 0 "NotInDetentPos" ;
VAL_ 2365445886 Jystck1YAxsLvrFrwrdPstvPsStatus 3 "NotAvailable" 2 "ErrorIndicator" 1 "OnPositiveSideOfNeutral" 0 "NotOnPositiveSideOfNeutral" ;
VAL_ 2365445886 Jystck1YAxsLvrBckNgtvePosStatus 3 "NotAvailable" 2 "ErrorIndicator" 1 "OnNegativeSideOfNeutral" 0 "NotOnNegativeSideOfNeutral" ;
VAL_ 2365445886 Joystick1YAxisNeutralPosStatus 3 "NotAvailable" 2 "ErrorIndicator" 1 "InNeutralPos" 0 "NotInNeutralPos" ;
VAL_ 2365445886 Joystick1Button9PressedStatus 3 "NotAvailable" 2 "ErrorIndicator" 1 "ButtonPressed" 0 "ButtonNotPressed" ;
VAL_ 2365445886 Joystick1Button10PressedStatus 3 "NotAvailable" 2 "ErrorIndicator" 1 "ButtonPressed" 0 "ButtonNotPressed" ;
VAL_ 2365445886 Joystick1Button11PressedStatus 3 "NotAvailable" 2 "ErrorIndicator" 1 "ButtonPressed" 0 "ButtonNotPressed" ;
VAL_ 2365445886 Joystick1Button12PressedStatus 3 "NotAvailable" 2 "ErrorIndicator" 1 "ButtonPressed" 0 "ButtonNotPressed" ;
VAL_ 2365445886 Joystick1Button5PressedStatus 3 "NotAvailable" 2 "ErrorIndicator" 1 "ButtonPressed" 0 "ButtonNotPressed" ;
VAL_ 2365445886 Joystick1Button6PressedStatus 3 "NotAvailable" 2 "ErrorIndicator" 1 "ButtonPressed" 0 "ButtonNotPressed" ;
VAL_ 2365445886 Joystick1Button7PressedStatus 3 "NotAvailable" 2 "ErrorIndicator" 1 "ButtonPressed" 0 "ButtonNotPressed" ;
VAL_ 2365445886 Joystick1Button8PressedStatus 3 "NotAvailable" 2 "ErrorIndicator" 1 "ButtonPressed" 0 "ButtonNotPressed" ;
VAL_ 2365445886 Joystick1Button1PressedStatus 3 "NotAvailable" 2 "ErrorIndicator" 1 "ButtonPressed" 0 "ButtonNotPressed" ;
VAL_ 2365445886 Joystick1Button2PressedStatus 3 "NotAvailable" 2 "ErrorIndicator" 1 "ButtonPressed" 0 "ButtonNotPressed" ;
VAL_ 2365445886 Joystick1Button3PressedStatus 3 "NotAvailable" 2 "ErrorIndicator" 1 "ButtonPressed" 0 "ButtonNotPressed" ;
VAL_ 2365445886 Joystick1Button4PressedStatus 3 "NotAvailable" 2 "ErrorIndicator" 1 "ButtonPressed" 0 "ButtonNotPressed" ;
VAL_ 2365445886 Jystck1XAxsLvrRghtPstvPosStatus 3 "NotAvailable" 2 "ErrorIndicator" 1 "OnPositiveSideOfNeutral" 0 "NotOnPositiveSideOfNeutral" ;
VAL_ 2365445886 Jystck1XAxsLvrLftNgtvePosStatus 3 "NotAvailable" 2 "ErrorIndicator" 1 "OnNegativeSideOfNeutral" 0 "NotOnNegativeSideOfNeutral" ;
VAL_ 2365445886 Joystick1XAxisNeutralPosStatus 3 "NotAvailable" 2 "ErrorIndicator" 1 "InNeutralPos" 0 "NotInNeutralPos" ;
VAL_ 2566847230 ParkingBrakeRedWarningSignal 3 "TakeNoAction" 2 "Reserved" 1 "On" 0 "Off" ;
VAL_ 2566847230 ParkBrakeReleaseInhibitStatus 3 "Unavailable" 2 "Error" 1 "ParkBrakeReleaseIsInhibited" 0 "ParkBrakeReleaseIsNotInhibited" ;
VAL_ 2566847230 ParkingBrakeActuator 3 "NotAvailable" 2 "Error" 1 "ParkingBrakeActuatorActive" 0 "ParkingBrakeActuatorInactive" ;
VAL_ 2560884478 DTCWarnLampSupportStatus 3 "Unavailable" 2 "Reserved" 1 "LampOn" 0 "LampOff" ;
VAL_ 2560884478 DTCWarnLampSupportFlash 3 "Unavailable" 2 "Reserved" 1 "FastFlash" 0 "SlowFlash" ;
VAL_ 2560884478 DTCStopLampSupportStatus 3 "Unavailable" 2 "Reserved" 1 "LampOn" 0 "LampOff" ;
VAL_ 2560884478 DTCStopLampSupportFlash 3 "Unavailable" 2 "Reserved" 1 "FastFlash" 0 "SlowFlash" ;
VAL_ 2560884478 DTCProtectLampSupportStatus 3 "Unavailable" 2 "Reserved" 1 "LampOn" 0 "LampOff" ;
VAL_ 2560884478 DTCProtectLampSupportFlash 3 "Unavailable" 2 "Reserved" 1 "FastFlash" 0 "SlowFlash" ;
VAL_ 2560884478 DTCMilSupportStatus 3 "Unavailable" 2 "ShortMI" 1 "LampOn" 0 "LampOff" ;
VAL_ 2560884478 DTCMilSupportFlash 3 "Unavailable" 2 "Class_C_DTC" 1 "FastFlash" 0 "SlowFlash" ;
VAL_ 2566736126 EngExhstGsOxygnSnsrClsdLpOprtnBn 15 "NotSupported" 5 "1110Reserved" 4 "ClsdLpBtFltWthAtLstOnOxygnSnsrM" 3 "OpnLoopDueToDetectedSystemFault" 2 "OpenLoopDueToDrivingConditions" 1 "ClsdLpUsngOxygnSnsrAsFdbckFrFlC" 0 "OpnLpHsNtYtStsfdCndtnsTGClsdLop" ;
VAL_ 2566736382 EngExhstGsOxygnSnsrClsdLpOp_0000 15 "NotSupported" 5 "1110Reserved" 4 "ClsdLpBtFltWthAtLstOnOxygnSnsrM" 3 "OpnLoopDueToDetectedSystemFault" 2 "OpenLoopDueToDrivingConditions" 1 "ClsdLpUsngOxygnSnsrAsFdbckFrFlC" 0 "OpnLpHsNtYtStsfdCndtnsTGClsdLop" ;
VAL_ 2565874174 EngSpdSnsor1TimingPatternStatus 3 "NotAvailable" 2 "Error" 1 "OK" 0 "NotOK" ;
VAL_ 2565874174 EngSpdSnsor2TimingPatternStatus 3 "NotAvailable" 2 "Error" 1 "OK" 0 "NotOK" ;
VAL_ 2565874174 EngSpdSnsor3TimingPatternStatus 3 "NotAvailable" 2 "Error" 1 "OK" 0 "NotOK" ;
VAL_ 2432520958 EngCoolantThermostatMode 3 "DontCare_Reserved" 2 "Reserved" 1 "PosCtrlMode" 0 "TempCtrlMode" ;
VAL_ 2566758398 Aftrtreatment1AirEnableActuator 3 "notAvailable" 2 "reservedForSAEAssignment" 1 "active" 0 "notActive" ;
VAL_ 2566758398 Aftertreatment1PurgeAirActuator 3 "notAvailable" 2 "reservedForSAEAssignment" 1 "active" 0 "notActive" ;
VAL_ 2566758398 Aftrtrtmnt1AtmzationAirActuator 3 "notAvailable" 2 "reservedForSAEAssignment" 1 "active" 0 "notActive" ;
VAL_ 2566758398 Aftertreatment1AirSystemRelay 3 "notAvailable" 2 "reservedForSAEAssignment" 1 "active" 0 "notActive" ;
VAL_ 2566758910 Aftrtrtmnt1FlInjctor1HeaterCtrl 4 "Max" ;
VAL_ 2566758910 Aftrtratment1FuelEnableActuator 3 "notAvailable" 2 "reservedForSAEAssignment" 1 "active" 0 "notActive" ;
VAL_ 2566758910 Aftrtratment1RegenerationStatus 3 "notAvailable" 2 "reservedForSAEAssignment" 1 "active" 0 "notActive" ;
VAL_ 2566758910 Aftertreatment1Ignt 3 "notAvailable" 2 "reservedForSAEAssignment" 1 "active" 0 "notActive" ;
VAL_ 2566758910 Aftrtreatment1FuelDrainActuator 3 "notAvailable" 2 "reservedForSAEAssignment" 1 "active" 0 "notActive" ;
VAL_ 2566743550 Aftrtrtmnt1FlPress2ActuatorCtrl 4 "fullyOpen" ;
VAL_ 2566743550 Aftrtrtmnt1FlFlwDvrterValveCtrl 3 "notAvailable" 2 "reservedForSAEAssignment" 1 "on" 0 "off" ;
VAL_ 2566743550 Aftrtreatment1FuelPumpRelayCtrl 3 "notAvailable" 2 "reservedForSAEAssignment" 1 "on" 0 "off" ;
VAL_ 2565869310 Aftrtrtmnt1IntkGsSnsrPwerStatus 3 "NotAvailable" 2 "Error" 1 "InRange" 0 "NotInRange" ;
VAL_ 2565869310 Aftrtrtmnt1IntkGsSnsrHeaterCtrl 3 "HeaterOff" 2 "Preheat1" 1 "Preheat2" 0 "Automatic" ;
VAL_ 2565869310 Aftrtrtmnt1IntkWdRngO2RdngStble 3 "NotAvailable" 2 "Error" 1 "Stable" 0 "NotStable" ;
VAL_ 2565869310 Aftrtrtmnt1IntkNOxReadingStable 3 "NotAvailable" 2 "Error" 1 "Stable" 0 "NotStable" ;
VAL_ 2631728894 AntitheftComponentStatusStates 3 "NotDefined" 2 "BlckdThsSttIndctsThtALckUnlckCm" 1 "LckdThsSttIndctsThtCmpnntCnNOTB" 0 "UnlckdThsSttIndctsThtCmpnntCnBS" ;
VAL_ 2631728894 AntthftEncryptnSdPrsntIndicator 3 "NotAvailable" 2 "Error" 1 "RandomNumberIsPresent" 0 "RandomNumberIsNotPresent" ;
VAL_ 2631728894 AntitheftModifyPwdStates 3 "Notvalid" 2 "EmptyOfPwdsThsSttIndctsThtCmpnn" 1 "FullofPwds" 0 "OkThsSttIndctsThtRqWsSccssfllyP" ;
VAL_ 2631728894 AntitheftPwdValidIndicator 3 "NotAvailable" 2 "Error" 1 "PwdIsAValidatedPassword" 0 "PwdIsNotAValidatedPassword" ;
VAL_ 2631794430 AntitheftCmdStates 6 "111NotDefined" 5 "Login" 4 "ChckSttsThsSttRprsntsARqTChckTS" 3 "LockorUnlock" 2 "ChngPwdThsSttRprsntsARqTCmpnntT" 1 "DeletePwd" 0 "AddPwdThsSttRprsntsARqTCmpnntTA" ;
VAL_ 2631794430 AntitheftDesiredExitModeStates 3 "NtAvlblThsSttIsIndctsThtOptnIsN" 2 "NotDefined" 1 "LckWhnKyffThsSttIsUsdTIndctThtC" 0 "LckUpnOprtrRqThsSttIsUsdTIndctT" ;
VAL_ 2631794430 AntthftEncryptonIndicatorStates 3 "NtAvlblThsSttIsUsdTIndctThtARnd" 2 "NotDefined" 1 "EncryptdCdPrsntThsSttIsUsdTIndc" 0 "EncryptnSdRqThsSttRprsntsARqstT" ;
VAL_ 2365478910 ElctrncShckAbsrbrCtrlMdLft_TgAxl 3 "NotAvailable" 2 "Error" 1 "NormalOperationDampersActive" 0 "NormalOperationDampersPassive" ;
VAL_ 2365478910 ElctrncShckAbsrbrCtrlMdRearAxle 3 "NotAvailable" 2 "Error" 1 "NormalOperationDampersActive" 0 "NormalOperationDampersPassive" ;
VAL_ 2365478910 ElctrncShckAbsrbrCtrlMdFrntAxle 3 "NotAvailable" 2 "Error" 1 "NormalOperationDampersActive" 0 "NormalOperationDampersPassive" ;
VAL_ 2560950014 FailureModeIdentifier1 31 "Not available" 19 "Received network data in error" 18 "Below normal (moderately severe)" 17 "Below normal (least severe)" 16 "Above normal (moderately severe)" 15 "Above normal (least severe)" 14 "Special intstructions" 13 "Out of calibration" 12 "Bad intelligent device" 11 "Root cause not known" 10 "Abnormal rate of change" 9 "Abnormal update rate" 8 "Abnormal frequency" 7 "Mechanical system not responding" 6 "Current above normal" 5 "Current below normal" 4 "Voltage below normal" 3 "Voltage above normal" 2 "Data erratic" 1 "Below normal (most severe)" 0 "Above normal (most severe)" ;
VAL_ 2565869566 Aftrtrtmnt1OtltGsSnsrPwerStatus 3 "NotAvailable" 2 "Error" 1 "InRange" 0 "NotInRange" ;
VAL_ 2565869566 Aftrtrtmnt1OtltGsSnsrHeaterCtrl 3 "HeaterOff" 2 "Preheat1" 1 "Preheat2" 0 "Automatic" ;
VAL_ 2565869566 Aftrtrtmnt1OtltWdRngO2RdngStble 3 "NotAvailable" 2 "Error" 1 "Stable" 0 "NotStable" ;
VAL_ 2565869566 Aftrtrtmnt1OtltNOxReadingStable 3 "NotAvailable" 2 "Error" 1 "Stable" 0 "NotStable" ;
VAL_ 2565869566 Aftrtrtmnt1OtletGasSensorAtTemp 3 "NotAvailable" 2 "Error" 1 "InRange" 0 "NotInRange" ;
VAL_ 2566749182 DslPrtclteFilter1AshLoadPercent 4 "LevelIsTargetAshServiceInterval" ;
VAL_ 2566749182 DslPrtcltFilter1SootLoadPercent 4 "LvlIsActvRgnerationTriggerLevel" ;
VAL_ 2566749182 Aftrtrtmnt1DslPrtcltFltrStLdRgnr 4 "IsLvlAtWhchActvDslPrtcltFltrRgn" ;
VAL_ 2566758142 Aftrtreatment2AirEnableActuator 3 "notAvailable" 2 "reservedForSAEAssignment" 1 "active" 0 "notActive" ;
VAL_ 2566758142 Aftertreatment2PurgeAirActuator 3 "notAvailable" 2 "reservedForSAEAssignment" 1 "active" 0 "notActive" ;
VAL_ 2566758142 Aftrtrtmnt2AtmzationAirActuator 3 "notAvailable" 2 "reservedForSAEAssignment" 1 "active" 0 "notActive" ;
VAL_ 2566758142 Aftertreatment2AirSystemRelay 3 "notAvailable" 2 "reservedForSAEAssignment" 1 "active" 0 "notActive" ;
VAL_ 2566758654 Aftrtrtmnt2FlInjctor1HeaterCtrl 4 "Max" ;
VAL_ 2566758654 Aftrtratment2FuelEnableActuator 3 "notAvailable" 2 "reservedForSAEAssignment" 1 "active" 0 "notActive" ;
VAL_ 2566758654 Aftrtratment2RegenerationStatus 3 "notAvailable" 2 "reservedForSAEAssignment" 1 "active" 0 "notActive" ;
VAL_ 2566758654 Aftertreatment2Ignt 3 "notAvailable" 2 "reservedForSAEAssignment" 1 "active" 0 "notActive" ;
VAL_ 2566758654 Aftrtreatment2FuelDrainActuator 3 "notAvailable" 2 "reservedForSAEAssignment" 1 "active" 0 "notActive" ;
